VERSION ""

NS_ :

CM_ "#file:heartbeat.h";
CM_ "#file:VCU_heartbeat_state.h";
CM_ "#file:vcu_state_machine.c";

VAL_ 2418327552 BMU_Heartbeat_State 0 "BMU_UNKNOWN" 1 "BMU_READY" 2 "BMU_PRECHARGE" 3 "BMU_TS_ACTIVE" 4 "BMU_ERROR";

VAL_ 2424619008 SW_Heartbeat_State 0 "START" 1 "PERIPHERAL_INIT" 2 "SENSOR_INIT" 3 "BOARD_CHECK" 10 "IDLE" 11 "PEDAL_CHECK" 15 "BMU_CHECK" 20 "EBS_PWR" 21 "EBS_CHECK_ASMS" 22 "EBS_CHECK_PRESSURE" 23 "EBS_CHECK_PRESSURE_BTN" 24 "EBS_CHECK_PRESSURE_LOW" 25 "EBS_CHECK_PRESSURE_HIGH" 26 "EBS_CTRL_ACK" 27 "EBS_IDLE" 28 "EBS_PCHRG_PRESSED" 29 "EBS_CHECK_TS" 30 "EBS_CHECK_COMPUTE" 31 "EBS_READY" 32 "EBS_RELEASE_BRAKE" 33 "EBS_DRIVE" 34 "EBS_BRAKING" 40 "PRECHARGE_REQUEST" 41 "PRECHARGE" 42 "INVERTER_CHECK" 43 "INVERTER_ENERGIZE" 60 "RTD_RDY" 61 "RTD_BTN" 100 "DRIVING" 150 "AV_IDLE" 151 "AV_PRECHARGE_REQUEST" 152 "AV_PRECHARGE" 153 "AV_INVERTER_CHECK" 154 "AV_RTD" 155 "AV_DRIVING" 156 "AV_EMERGENCY" 240 "TS_ERROR" 250 "SHUTDOWN" 251 "ERROR";

BS_:

BU_:

BO_ 2418327552 BMU_Heartbeat: 7 Vector__XXX
 SG_ BMU_Heartbeat_Flags : 8|32@1+ (1,0) [0|0] "" Vector__XXX
 SG_ BMU_Heartbeat_State : 0|8@1+ (1,0) [0|0] "" Vector__XXX

BO_ 2424356864 VCU_Heartbeat_CTRL: 8 Vector__XXX
 SG_ VCU_Heartbeat_StateID : 0|8@1+ (1,0) [0|0] "" Vector__XXX
 SG_ VCU_Heartbeat_Flags : 32|16@1+ (1,0) [0|0] "" Vector__XXX
 SG_ VCU_WARN_PedalPolarity : 48|1@1+ (1,0) [0|1] "" Vector__XXX
 SG_ VCU_Heartbeat_Reserved : 49|15@1+ (1,0) [0|0] "" Vector__XXX

BO_ 2424356865 VCU_Heartbeat_PERIPH: 8 Vector__XXX
 SG_ VCU_HeartbeatState_PERIPH : 0|64@1+ (1,0) [0|0] "" Vector__XXX

BO_ 1285 VCU_Sync: 4 Vector__XXX
 SG_ VCU_Timestamp : 0|32@1+ (1,0) [0|4294967295] "ms" Vector__XXX

BO_ 2290122752 VCU_ShutdownStatus: 3 Vector__XXX
 SG_ VCU_ShutdownStatus : 16|8@1+ (1,0) [0|1] "" Vector__XXX
 SG_ VCU_ShutdownLines : 0|16@1+ (1,0) [0|0] "" Vector__XXX

BO_ 2449473537 VCU_RTD: 8 Vector__XXX
 SG_ VCU_RTD_Front : 0|1@1+ (1,0) [0|1] "" Vector__XXX
 SG_ VCU_RTD_Rear : 1|1@1+ (1,0) [0|1] "" Vector__XXX

BO_ 2449473538 VCU_MotorTemp: 8 Vector__XXX
 SG_ VCU_MotorTemp_FL : 0|16@1+ (0.1,0) [0|100] "" Vector__XXX
 SG_ VCU_MotorTemp_FR : 16|16@1+ (0.1,0) [0|100] "" Vector__XXX
 SG_ VCU_MotorTemp_RL : 32|16@1+ (0.1,0) [0|100] "" Vector__XXX
 SG_ VCU_MotorTemp_RR : 48|16@1+ (0.1,0) [0|100] "" Vector__XXXd

BO_ 2449473539 VCU_IMU_Accel: 8 Vector__XXX
 SG_ VCU_IMU_Accel_X : 0|16@1+ (0.01,-10) [-10|10] "" Vector__XXX
 SG_ VCU_IMU_Accel_Y : 16|16@1+ (0.01,-10) [-10|10] "" Vector__XXX
 SG_ VCU_IMU_Accel_Z : 32|16@1+ (0.01,-10) [-10|10] "" Vector__XXX

BO_ 2449473540 VCU_IMU_Gyro: 8 Vector__XXX
 SG_ VCU_IMU_Gyro_X : 0|16@1+ (0.01,-500) [-500|500] "" Vector__XXX
 SG_ VCU_IMU_Gyro_Y : 16|16@1+ (0.01,-500) [-500|500] "" Vector__XXX
 SG_ VCU_IMU_Gyro_Z : 32|16@1+ (0.01,-500) [-500|500] "" Vector__XXX

BO_ 2449473541 VCU_OBJ_DICT: 8 Vector__XXX
 SG_ VCU_OBJ_DICT_Index : 0|16@1+ (1,0) [0|65535] "" Vector__XXX
 SG_ VCU_OBJ_DICT_SubIndex : 16|8@1+ (1,0) [0|255] "" Vector__XXX
 SG_ VCU_OBJ_DICT_Data : 24|40@1+ (1,0) [0|0] "" Vector__XXX

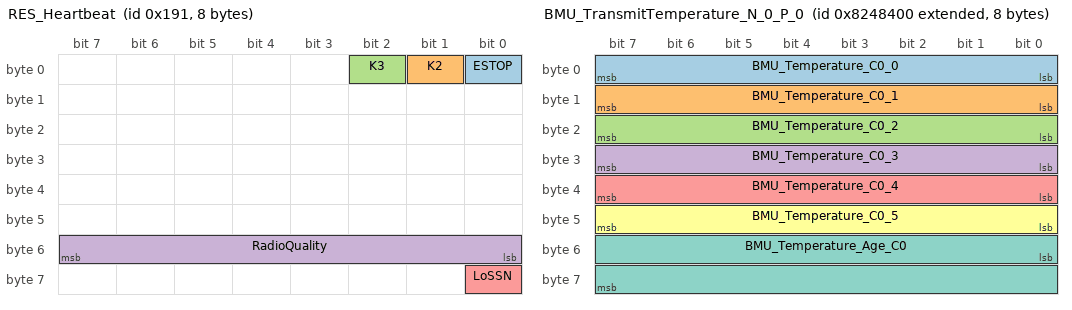
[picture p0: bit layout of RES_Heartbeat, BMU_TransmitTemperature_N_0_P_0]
BO_ 401 RES_Heartbeat: 8 Vector__XXX
 SG_ ESTOP : 0|1@1- (1,0) [0|1] "" Vector__XXX
 SG_ K2 : 1|1@1- (1,0) [0|1] "" Vector__XXX
 SG_ K3 : 2|1@1- (1,0) [0|1] "" Vector__XXX
 SG_ RadioQuality : 48|8@1+ (1,0) [0|255] "" Vector__XXX
 SG_ LoSSN : 56|1@1- (1,0) [0|1] "" Vector__XXX

BO_ 2420948992 EBS_CTRL_Heartbeat: 8 Vector___XXX
 SG_ State : 0|8@1+ (1, 0) [0|0] "" Vector__XXX

BO_ 2420424705 MCISO_Heartbeat_Right: 8 Vector__XXX
 SG_ MCISO_HeartbeatState_Right : 0|16@1+ (1,0) [0|0] "" Vector__XXX

BO_ 2420424704 MCISO_Heartbeat_Left: 8 Vector__XXX
 SG_ MCISO_HeartbeatState_Left : 0|16@1+ (1,0) [0|0] "" Vector__XXX

BO_ 2424619008 SW_Heartbeat: 8 Vector__XXX
 SG_ SW_Heartbeat_Flags : 16|16@1+ (1,0) [0|0] "" Vector__XXX
 SG_ SW_Heartbeat_State : 0|8@1+ (1,0) [0|0] "" Vector__XXX
 SG_ SW_Heartbeat_MissionID : 8|8@1+ (1,0) [0|0] "" Vector__XXX

BO_ 2290122937 VCU_Suspension_Rot_Front: 8 Vector__XXX
 SG_ VCU_Suspension_Rot_FL_ADC : 7|16@0+ (1,0) [0|0] "" Vector__XXX
 SG_ VCU_Suspension_Rot_FR_ADC : 23|16@0+ (1,0) [0|0] "" Vector__XXX
 SG_ VCU_Suspension_Rot_FL : 39|16@0- (0.001,0) [0|0] "" Vector__XXX
 SG_ VCU_Suspension_Rot_FR : 55|16@0- (0.001,0) [0|0] "" Vector__XXX

BO_ 2290122934 VCU_Suspension_Rot_Rear: 8 Vector__XXX
 SG_ VCU_Suspension_Rot_RL_ADC : 7|16@0+ (1,0) [0|0] "" Vector__XXX
 SG_ VCU_Suspension_Rot_RR_ADC : 23|16@0+ (1,0) [0|0] "" Vector__XXX
 SG_ VCU_Suspension_Rot_RL : 39|16@0- (0.001,0) [0|0] "" Vector__XXX
 SG_ VCU_Suspension_Rot_RR : 55|16@0- (0.001,0) [0|0] "" Vector__XXX

BO_ 2290122920 VCU_Temp_Gearbox_Right: 8 Vector__XXX
 SG_ VCU_Gearbox_Temp_Right_Temp : 39|16@0+ (0.1,0) [0|0] "" Vector__XXX
 SG_ VCU_Gearbox_Temp_Right_R : 23|16@0+ (1,0) [0|0] "" Vector__XXX
 SG_ VCU_Gearbox_Temp_Right_ADC : 7|16@0+ (1,0) [0|0] "" Vector__XXX

BO_ 2290122919 VCU_Temp_Gearbox_Left: 8 Vector__XXX
 SG_ VCU_Gearbox_Temp_Left_Temp : 39|16@0+ (0.1,0) [0|0] "" Vector__XXX
 SG_ VCU_Gearbox_Temp_Left_R : 23|16@0+ (1,0) [0|0] "" Vector__XXX
 SG_ VCU_Gearbox_Temp_Left_ADC : 7|16@0+ (1,0) [0|0] "" Vector__XXX

BO_ 2290122832 VCU_AirPressure: 8 Vector__XXX
 SG_ VCU_AirPressure_ADC : 7|16@0+ (1,0) [0|0] "" Vector__XXX

BO_ 2290122818 VCU_SuspensionTravel_DASH: 8 Vector__XXX
 SG_ VCU_SuspensionTravel_ADC_FR : 31|16@0+ (1,0) [0|0] "" Vector__XXX
 SG_ VCU_SuspensionTravel_ADC_FL : 15|16@0+ (1,0) [0|0] "" Vector__XXX

BO_ 2290122816 VCU_SuspensionTravel_SHDN: 8 Vector__XXX
 SG_ VCU_SuspensionTravel_ADC_RR : 31|16@0+ (1,0) [0|0] "" Vector__XXX
 SG_ VCU_SuspensionTravel_ADC_RL : 15|16@0+ (1,0) [0|0] "" Vector__XXX

BO_ 2290122784 VCU_Pedal_Accel: 8 Vector__XXX
 SG_ VCU_Pedal_Accel_0 : 7|16@0+ (1,0) [0|0] "" Vector__XXX
 SG_ VCU_Pedal_Accel_1 : 23|16@0+ (1,0) [0|0] "" Vector__XXX
 SG_ VCU_Pedal_Accel_ADC_0 : 39|16@0+ (1,0) [0|0] "" Vector__XXX
 SG_ VCU_Pedal_Accel_ADC_1 : 55|16@0+ (1,0) [0|0] "" Vector__XXX

BO_ 2290122800 VCU_Pedal_Brake: 8 Vector__XXX
 SG_ VCU_Pedal_Brake_ADC_0 : 7|16@0+ (1,0) [0|0] "" Vector__XXX
 SG_ VCU_Pedal_Brake_ADC_1 : 23|16@0+ (1,0) [0|0] "" Vector__XXX
 SG_ VCU_Pedal_Brake_PSI_0 : 39|16@0- (0.0625,0) [0|0] "" Vector__XXX
 SG_ VCU_Pedal_Brake_PSI_1 : 55|16@0- (0.0625,0) [0|0] "" Vector__XXX

BO_ 2290122848 VCU_TransmitSteering: 8 Vector__XXX
 SG_ VCU_Steering_ADC_0 : 32|16@1+ (0.1,0) [0|0] "" Vector__XXX
 SG_ VCU_Steering_ADC_1 : 48|16@1+ (0.1,0) [0|0] "" Vector__XXX
 SG_ VCU_Steering_0 : 0|16@1- (0.1,0) [0|0] "deg" Vector__XXX
 SG_ VCU_Steering_1 : 16|16@1- (0.1,0) [0|0] "deg" Vector__XXX

BO_ 2290122960 VCU_Wheel_Speed_Front: 8 Vector__XXX
 SG_ VCU_Wheel_Freq_FL : 7|16@0+ (1,0) [0|0] "" Vector__XXX
 SG_ VCU_Wheel_Freq_FR : 23|16@0+ (1,0) [0|0] "" Vector__XXX
 SG_ VCU_Wheel_RPM_FL : 39|16@0+ (0.1,0) [0|0] "" Vector__XXX
 SG_ VCU_Wheel_RPM_FR : 55|16@0+ (0.1,0) [0|0] "" Vector__XXX

BO_ 2290122951 VCU_FlowRate_Left: 8 Vector__XXX
 SG_ VCU_FlowRate_lpm_L : 7|16@0+ (0.01,0) [0|0] "L/min" Vector___XXX
 SG_ VCU_FlowRate_Freq_L : 23|16@0+ (0.01,0) [0|0] "" Vector___XXX

BO_ 2291122952 VCU_FlowRate_Right: 8 Vector__XXX
 SG_ VCU_FlowRate_lpm_R : 7|16@0+ (0.01,0) [0|0] "L/min" Vector___XXX
 SG_ VCU_FlowRate_Freq_R : 23|16@0+ (0.01,0) [0|0] "" Vector___XXX

BO_ 2290122993 VCU_Pitot_Tube: 8 Vector___XXX
 SG_ VCU_Pitot_Tube_ADC : 7|16@0+ (1,0) [0|0] "" Vector___XXX
 SG_ VCU_Pitot_Tube_Pressure : 23|16@0+ (0.01,0) [0|0] "kPa" Vector___XXX

BO_ 2424340672 VCU_Cooling_R_In: 8 Vector__XXX
 SG_ VCU_CoolR_In_Pressure_kPa : 7|16@0+ (0.1,0) [0|1000] "kPa" Vector__XXX
 SG_ VCU_CoolR_In_Temp_mV : 23|16@0+ (1,0) [0|5000] "mV" Vector__XXX
 SG_ VCU_CoolR_In_Pressure_PSI : 39|16@0+ (0.01,0) [0|150] "PSI" Vector__XXX
 SG_ VCU_CoolR_In_Temp_Celsius : 55|16@0- (0.1,0) [-40|150] "degC" Vector__XXX

BO_ 2424340673 VCU_Cooling_L_In: 8 Vector__XXX
 SG_ VCU_CoolL_In_Pressure_kPa : 7|16@0+ (0.1,0) [0|1000] "kPa" Vector__XXX
 SG_ VCU_CoolL_In_Temp_mV : 23|16@0+ (1,0) [0|5000] "mV" Vector__XXX
 SG_ VCU_CoolL_In_Pressure_PSI : 39|16@0+ (0.01,0) [0|150] "PSI" Vector__XXX
 SG_ VCU_CoolL_In_Temp_Celsius : 55|16@0- (0.1,0) [-40|150] "degC" Vector__XXX

BO_ 2424340676 VCU_Cooling_R_Out: 8 Vector__XXX
 SG_ VCU_CoolR_Out_Pressure_kPa : 7|16@0+ (0.1,0) [0|1000] "kPa" Vector__XXX
 SG_ VCU_CoolR_Out_Temp_mV : 23|16@0+ (1,0) [0|5000] "mV" Vector__XXX
 SG_ VCU_CoolR_Out_Pressure_PSI : 39|16@0+ (0.01,0) [0|150] "PSI" Vector__XXX
 SG_ VCU_CoolR_Out_Temp_Celsius : 55|16@0- (0.1,0) [-40|150] "degC" Vector__XXX

BO_ 2424340677 VCU_Cooling_L_Out: 8 Vector__XXX
 SG_ VCU_CoolL_Out_Pressure_kPa : 7|16@0+ (0.1,0) [0|1000] "kPa" Vector__XXX
 SG_ VCU_CoolL_Out_Temp_mV : 23|16@0+ (1,0) [0|5000] "mV" Vector__XXX
 SG_ VCU_CoolL_Out_Pressure_PSI : 39|16@0+ (0.01,0) [0|150] "PSI" Vector__XXX
 SG_ VCU_CoolL_Out_Temp_Celsius : 55|16@0- (0.1,0) [-40|150] "degC" Vector__XXX

BO_ 2424340674 VCU_CoolingLoop_Status: 8 Vector__XXX
 SG_ VCU_Pump1_Pressure_Filtered : 7|16@0+ (1,0) [0|65535] "mV" Vector__XXX
 SG_ VCU_Pump1_Temp_Filtered : 23|16@0+ (1,0) [0|65535] "mV" Vector__XXX
 SG_ VCU_Pump2_Pressure_Filtered : 39|16@0+ (1,0) [0|65535] "mV" Vector__XXX
 SG_ VCU_Pump2_Temp_Filtered : 55|16@0+ (1,0) [0|65535] "mV" Vector__XXX

BO_ 2424340675 VCU_CoolingLoop_Pressure_Bar: 8 Vector__XXX
 SG_ VCU_Pump1_Pressure_Bar : 7|16@0+ (0.001,0) [0|65.535] "bar" Vector__XXX
 SG_ VCU_Pump2_Pressure_Bar : 23|16@0+ (0.001,0) [0|65.535] "bar" Vector__XXX
 SG_ VCU_Sensor_Status : 39|8@0+ (1,0) [0|255] "" Vector__XXX

BO_ 2284097024 BMU_TransmitPower: 8 Vector__XXX
 SG_ BMU_Power : 0|4@1- (0.001,0) [0|0] "" Vector__XXX

BO_ 2284096768 BMU_TransmitPackInfo: 8 Vector__XXX
 SG_ BMU_PackVoltage : 32|32@1- (1E-006,0) [0|0] "" Vector__XXX
 SG_ BMU_PackCurrent : 0|32@1- (1E-006,0) [0|0] "" Vector__XXX

BO_ 2284093440 BMU_TransmitVoltage_N_0_P_0: 8 Vector__XXX
 SG_ BMU_Voltage_C0_0 : 0|16@1+ (1,0) [0|0] "" Vector__XXX
 SG_ BMU_Voltage_C0_1 : 16|16@1+ (1,0) [0|0] "" Vector__XXX
 SG_ BMU_Voltage_C0_2 : 32|16@1+ (1,0) [0|0] "" Vector__XXX
 SG_ BMU_Voltage_Age_C0 : 48|16@1+ (1,0) [0|0] "" Vector__XXX

BO_ 2284093441 BMU_TransmitVoltage_N_0_P_1: 8 Vector__XXX
 SG_ BMU_Voltage_C0_3 : 0|16@1+ (1,0) [0|0] "" Vector__XXX
 SG_ BMU_Voltage_C0_4 : 16|16@1+ (1,0) [0|0] "" Vector__XXX
 SG_ BMU_Voltage_C0_5 : 32|16@1+ (1,0) [0|0] "" Vector__XXX
 SG_ BMU_Voltage_Age_C0 : 48|16@1+ (1,0) [0|0] "" Vector__XXX

BO_ 2284093442 BMU_TransmitVoltage_N_0_P_2: 8 Vector__XXX
 SG_ BMU_Voltage_C0_6 : 0|16@1+ (1,0) [0|0] "" Vector__XXX
 SG_ BMU_Voltage_C0_7 : 16|16@1+ (1,0) [0|0] "" Vector__XXX
 SG_ BMU_Voltage_C0_8 : 32|16@1+ (1,0) [0|0] "" Vector__XXX
 SG_ BMU_Voltage_Age_C0 : 48|16@1+ (1,0) [0|0] "" Vector__XXX

BO_ 2284093443 BMU_TransmitVoltage_N_0_P_3: 8 Vector__XXX
 SG_ BMU_Voltage_C0_9 : 0|16@1+ (1,0) [0|0] "" Vector__XXX
 SG_ BMU_Voltage_C0_10 : 16|16@1+ (1,0) [0|0] "" Vector__XXX
 SG_ BMU_Voltage_C0_11 : 32|16@1+ (1,0) [0|0] "" Vector__XXX
 SG_ BMU_Voltage_Age_C0 : 48|16@1+ (1,0) [0|0] "" Vector__XXX

BO_ 2284093444 BMU_TransmitVoltage_N_0_P_4: 8 Vector__XXX
 SG_ BMU_Voltage_C0_12 : 0|16@1+ (1,0) [0|0] "" Vector__XXX
 SG_ BMU_Voltage_C0_13 : 16|16@1+ (1,0) [0|0] "" Vector__XXX
 SG_ BMU_Voltage_Age_C0 : 48|16@1+ (1,0) [0|0] "" Vector__XXX

BO_ 2284093456 BMU_TransmitVoltage_N_1_P_0: 8 Vector__XXX
 SG_ BMU_Voltage_C1_0 : 0|16@1+ (1,0) [0|0] "" Vector__XXX
 SG_ BMU_Voltage_C1_1 : 16|16@1+ (1,0) [0|0] "" Vector__XXX
 SG_ BMU_Voltage_C1_2 : 32|16@1+ (1,0) [0|0] "" Vector__XXX
 SG_ BMU_Voltage_Age_C1 : 48|16@1+ (1,0) [0|0] "" Vector__XXX

BO_ 2284093457 BMU_TransmitVoltage_N_1_P_1: 8 Vector__XXX
 SG_ BMU_Voltage_C1_3 : 0|16@1+ (1,0) [0|0] "" Vector__XXX
 SG_ BMU_Voltage_C1_4 : 16|16@1+ (1,0) [0|0] "" Vector__XXX
 SG_ BMU_Voltage_C1_5 : 32|16@1+ (1,0) [0|0] "" Vector__XXX
 SG_ BMU_Voltage_Age_C1 : 48|16@1+ (1,0) [0|0] "" Vector__XXX

BO_ 2284093458 BMU_TransmitVoltage_N_1_P_2: 8 Vector__XXX
 SG_ BMU_Voltage_C1_6 : 0|16@1+ (1,0) [0|0] "" Vector__XXX
 SG_ BMU_Voltage_C1_7 : 16|16@1+ (1,0) [0|0] "" Vector__XXX
 SG_ BMU_Voltage_C1_8 : 32|16@1+ (1,0) [0|0] "" Vector__XXX
 SG_ BMU_Voltage_Age_C1 : 48|16@1+ (1,0) [0|0] "" Vector__XXX

BO_ 2284093459 BMU_TransmitVoltage_N_1_P_3: 8 Vector__XXX
 SG_ BMU_Voltage_C1_9 : 0|16@1+ (1,0) [0|0] "" Vector__XXX
 SG_ BMU_Voltage_C1_10 : 16|16@1+ (1,0) [0|0] "" Vector__XXX
 SG_ BMU_Voltage_C1_11 : 32|16@1+ (1,0) [0|0] "" Vector__XXX
 SG_ BMU_Voltage_Age_C1 : 48|16@1+ (1,0) [0|0] "" Vector__XXX

BO_ 2284093460 BMU_TransmitVoltage_N_1_P_4: 8 Vector__XXX
 SG_ BMU_Voltage_C1_12 : 0|16@1+ (1,0) [0|0] "" Vector__XXX
 SG_ BMU_Voltage_C1_13 : 16|16@1+ (1,0) [0|0] "" Vector__XXX
 SG_ BMU_Voltage_Age_C1 : 48|16@1+ (1,0) [0|0] "" Vector__XXX

BO_ 2284093472 BMU_TransmitVoltage_N_2_P_0: 8 Vector__XXX
 SG_ BMU_Voltage_C2_0 : 0|16@1+ (1,0) [0|0] "" Vector__XXX
 SG_ BMU_Voltage_C2_1 : 16|16@1+ (1,0) [0|0] "" Vector__XXX
 SG_ BMU_Voltage_C2_2 : 32|16@1+ (1,0) [0|0] "" Vector__XXX
 SG_ BMU_Voltage_Age_C2 : 48|16@1+ (1,0) [0|0] "" Vector__XXX

BO_ 2284093473 BMU_TransmitVoltage_N_2_P_1: 8 Vector__XXX
 SG_ BMU_Voltage_C2_3 : 0|16@1+ (1,0) [0|0] "" Vector__XXX
 SG_ BMU_Voltage_C2_4 : 16|16@1+ (1,0) [0|0] "" Vector__XXX
 SG_ BMU_Voltage_C2_5 : 32|16@1+ (1,0) [0|0] "" Vector__XXX
 SG_ BMU_Voltage_Age_C2 : 48|16@1+ (1,0) [0|0] "" Vector__XXX

BO_ 2284093474 BMU_TransmitVoltage_N_2_P_2: 8 Vector__XXX
 SG_ BMU_Voltage_C2_6 : 0|16@1+ (1,0) [0|0] "" Vector__XXX
 SG_ BMU_Voltage_C2_7 : 16|16@1+ (1,0) [0|0] "" Vector__XXX
 SG_ BMU_Voltage_C2_8 : 32|16@1+ (1,0) [0|0] "" Vector__XXX
 SG_ BMU_Voltage_Age_C2 : 48|16@1+ (1,0) [0|0] "" Vector__XXX

BO_ 2284093475 BMU_TransmitVoltage_N_2_P_3: 8 Vector__XXX
 SG_ BMU_Voltage_C2_9 : 0|16@1+ (1,0) [0|0] "" Vector__XXX
 SG_ BMU_Voltage_C2_10 : 16|16@1+ (1,0) [0|0] "" Vector__XXX
 SG_ BMU_Voltage_C2_11 : 32|16@1+ (1,0) [0|0] "" Vector__XXX
 SG_ BMU_Voltage_Age_C2 : 48|16@1+ (1,0) [0|0] "" Vector__XXX

BO_ 2284093476 BMU_TransmitVoltage_N_2_P_4: 8 Vector__XXX
 SG_ BMU_Voltage_C2_12 : 0|16@1+ (1,0) [0|0] "" Vector__XXX
 SG_ BMU_Voltage_C2_13 : 16|16@1+ (1,0) [0|0] "" Vector__XXX
 SG_ BMU_Voltage_Age_C2 : 48|16@1+ (1,0) [0|0] "" Vector__XXX

BO_ 2284093488 BMU_TransmitVoltage_N_3_P_0: 8 Vector__XXX
 SG_ BMU_Voltage_C3_0 : 0|16@1+ (1,0) [0|0] "" Vector__XXX
 SG_ BMU_Voltage_C3_1 : 16|16@1+ (1,0) [0|0] "" Vector__XXX
 SG_ BMU_Voltage_C3_2 : 32|16@1+ (1,0) [0|0] "" Vector__XXX
 SG_ BMU_Voltage_Age_C3 : 48|16@1+ (1,0) [0|0] "" Vector__XXX

BO_ 2284093489 BMU_TransmitVoltage_N_3_P_1: 8 Vector__XXX
 SG_ BMU_Voltage_C3_3 : 0|16@1+ (1,0) [0|0] "" Vector__XXX
 SG_ BMU_Voltage_C3_4 : 16|16@1+ (1,0) [0|0] "" Vector__XXX
 SG_ BMU_Voltage_C3_5 : 32|16@1+ (1,0) [0|0] "" Vector__XXX
 SG_ BMU_Voltage_Age_C3 : 48|16@1+ (1,0) [0|0] "" Vector__XXX

BO_ 2284093490 BMU_TransmitVoltage_N_3_P_2: 8 Vector__XXX
 SG_ BMU_Voltage_C3_6 : 0|16@1+ (1,0) [0|0] "" Vector__XXX
 SG_ BMU_Voltage_C3_7 : 16|16@1+ (1,0) [0|0] "" Vector__XXX
 SG_ BMU_Voltage_C3_8 : 32|16@1+ (1,0) [0|0] "" Vector__XXX
 SG_ BMU_Voltage_Age_C3 : 48|16@1+ (1,0) [0|0] "" Vector__XXX

BO_ 2284093491 BMU_TransmitVoltage_N_3_P_3: 8 Vector__XXX
 SG_ BMU_Voltage_C3_9 : 0|16@1+ (1,0) [0|0] "" Vector__XXX
 SG_ BMU_Voltage_C3_10 : 16|16@1+ (1,0) [0|0] "" Vector__XXX
 SG_ BMU_Voltage_C3_11 : 32|16@1+ (1,0) [0|0] "" Vector__XXX
 SG_ BMU_Voltage_Age_C3 : 48|16@1+ (1,0) [0|0] "" Vector__XXX

BO_ 2284093492 BMU_TransmitVoltage_N_3_P_4: 8 Vector__XXX
 SG_ BMU_Voltage_C3_12 : 0|16@1+ (1,0) [0|0] "" Vector__XXX
 SG_ BMU_Voltage_C3_13 : 16|16@1+ (1,0) [0|0] "" Vector__XXX
 SG_ BMU_Voltage_Age_C3 : 48|16@1+ (1,0) [0|0] "" Vector__XXX

BO_ 2284093504 BMU_TransmitVoltage_N_4_P_0: 8 Vector__XXX
 SG_ BMU_Voltage_C4_0 : 0|16@1+ (1,0) [0|0] "" Vector__XXX
 SG_ BMU_Voltage_C4_1 : 16|16@1+ (1,0) [0|0] "" Vector__XXX
 SG_ BMU_Voltage_C4_2 : 32|16@1+ (1,0) [0|0] "" Vector__XXX
 SG_ BMU_Voltage_Age_C4 : 48|16@1+ (1,0) [0|0] "" Vector__XXX

BO_ 2284093505 BMU_TransmitVoltage_N_4_P_1: 8 Vector__XXX
 SG_ BMU_Voltage_C4_3 : 0|16@1+ (1,0) [0|0] "" Vector__XXX
 SG_ BMU_Voltage_C4_4 : 16|16@1+ (1,0) [0|0] "" Vector__XXX
 SG_ BMU_Voltage_C4_5 : 32|16@1+ (1,0) [0|0] "" Vector__XXX
 SG_ BMU_Voltage_Age_C4 : 48|16@1+ (1,0) [0|0] "" Vector__XXX

BO_ 2284093506 BMU_TransmitVoltage_N_4_P_2: 8 Vector__XXX
 SG_ BMU_Voltage_C4_6 : 0|16@1+ (1,0) [0|0] "" Vector__XXX
 SG_ BMU_Voltage_C4_7 : 16|16@1+ (1,0) [0|0] "" Vector__XXX
 SG_ BMU_Voltage_C4_8 : 32|16@1+ (1,0) [0|0] "" Vector__XXX
 SG_ BMU_Voltage_Age_C4 : 48|16@1+ (1,0) [0|0] "" Vector__XXX

BO_ 2284093507 BMU_TransmitVoltage_N_4_P_3: 8 Vector__XXX
 SG_ BMU_Voltage_C4_9 : 0|16@1+ (1,0) [0|0] "" Vector__XXX
 SG_ BMU_Voltage_C4_10 : 16|16@1+ (1,0) [0|0] "" Vector__XXX
 SG_ BMU_Voltage_C4_11 : 32|16@1+ (1,0) [0|0] "" Vector__XXX
 SG_ BMU_Voltage_Age_C4 : 48|16@1+ (1,0) [0|0] "" Vector__XXX

BO_ 2284093508 BMU_TransmitVoltage_N_4_P_4: 8 Vector__XXX
 SG_ BMU_Voltage_C4_12 : 0|16@1+ (1,0) [0|0] "" Vector__XXX
 SG_ BMU_Voltage_C4_13 : 16|16@1+ (1,0) [0|0] "" Vector__XXX
 SG_ BMU_Voltage_Age_C4 : 48|16@1+ (1,0) [0|0] "" Vector__XXX

BO_ 2284093520 BMU_TransmitVoltage_N_5_P_0: 8 Vector__XXX
 SG_ BMU_Voltage_C5_0 : 0|16@1+ (1,0) [0|0] "" Vector__XXX
 SG_ BMU_Voltage_C5_1 : 16|16@1+ (1,0) [0|0] "" Vector__XXX
 SG_ BMU_Voltage_C5_2 : 32|16@1+ (1,0) [0|0] "" Vector__XXX
 SG_ BMU_Voltage_Age_C5 : 48|16@1+ (1,0) [0|0] "" Vector__XXX

BO_ 2284093521 BMU_TransmitVoltage_N_5_P_1: 8 Vector__XXX
 SG_ BMU_Voltage_C5_3 : 0|16@1+ (1,0) [0|0] "" Vector__XXX
 SG_ BMU_Voltage_C5_4 : 16|16@1+ (1,0) [0|0] "" Vector__XXX
 SG_ BMU_Voltage_C5_5 : 32|16@1+ (1,0) [0|0] "" Vector__XXX
 SG_ BMU_Voltage_Age_C5 : 48|16@1+ (1,0) [0|0] "" Vector__XXX

BO_ 2284093522 BMU_TransmitVoltage_N_5_P_2: 8 Vector__XXX
 SG_ BMU_Voltage_C5_6 : 0|16@1+ (1,0) [0|0] "" Vector__XXX
 SG_ BMU_Voltage_C5_7 : 16|16@1+ (1,0) [0|0] "" Vector__XXX
 SG_ BMU_Voltage_C5_8 : 32|16@1+ (1,0) [0|0] "" Vector__XXX
 SG_ BMU_Voltage_Age_C5 : 48|16@1+ (1,0) [0|0] "" Vector__XXX

BO_ 2284093523 BMU_TransmitVoltage_N_5_P_3: 8 Vector__XXX
 SG_ BMU_Voltage_C5_9 : 0|16@1+ (1,0) [0|0] "" Vector__XXX
 SG_ BMU_Voltage_C5_10 : 16|16@1+ (1,0) [0|0] "" Vector__XXX
 SG_ BMU_Voltage_C5_11 : 32|16@1+ (1,0) [0|0] "" Vector__XXX
 SG_ BMU_Voltage_Age_C5 : 48|16@1+ (1,0) [0|0] "" Vector__XXX

BO_ 2284093524 BMU_TransmitVoltage_N_5_P_4: 8 Vector__XXX
 SG_ BMU_Voltage_C5_12 : 0|16@1+ (1,0) [0|0] "" Vector__XXX
 SG_ BMU_Voltage_C5_13 : 16|16@1+ (1,0) [0|0] "" Vector__XXX
 SG_ BMU_Voltage_Age_C5 : 48|16@1+ (1,0) [0|0] "" Vector__XXX

BO_ 2284093536 BMU_TransmitVoltage_N_6_P_0: 8 Vector__XXX
 SG_ BMU_Voltage_C6_0 : 0|16@1+ (1,0) [0|0] "" Vector__XXX
 SG_ BMU_Voltage_C6_1 : 16|16@1+ (1,0) [0|0] "" Vector__XXX
 SG_ BMU_Voltage_C6_2 : 32|16@1+ (1,0) [0|0] "" Vector__XXX
 SG_ BMU_Voltage_Age_C6 : 48|16@1+ (1,0) [0|0] "" Vector__XXX

BO_ 2284093537 BMU_TransmitVoltage_N_6_P_1: 8 Vector__XXX
 SG_ BMU_Voltage_C6_3 : 0|16@1+ (1,0) [0|0] "" Vector__XXX
 SG_ BMU_Voltage_C6_4 : 16|16@1+ (1,0) [0|0] "" Vector__XXX
 SG_ BMU_Voltage_C6_5 : 32|16@1+ (1,0) [0|0] "" Vector__XXX
 SG_ BMU_Voltage_Age_C6 : 48|16@1+ (1,0) [0|0] "" Vector__XXX

BO_ 2284093538 BMU_TransmitVoltage_N_6_P_2: 8 Vector__XXX
 SG_ BMU_Voltage_C6_6 : 0|16@1+ (1,0) [0|0] "" Vector__XXX
 SG_ BMU_Voltage_C6_7 : 16|16@1+ (1,0) [0|0] "" Vector__XXX
 SG_ BMU_Voltage_C6_8 : 32|16@1+ (1,0) [0|0] "" Vector__XXX
 SG_ BMU_Voltage_Age_C6 : 48|16@1+ (1,0) [0|0] "" Vector__XXX

BO_ 2284093539 BMU_TransmitVoltage_N_6_P_3: 8 Vector__XXX
 SG_ BMU_Voltage_C6_9 : 0|16@1+ (1,0) [0|0] "" Vector__XXX
 SG_ BMU_Voltage_C6_10 : 16|16@1+ (1,0) [0|0] "" Vector__XXX
 SG_ BMU_Voltage_C6_11 : 32|16@1+ (1,0) [0|0] "" Vector__XXX
 SG_ BMU_Voltage_Age_C6 : 48|16@1+ (1,0) [0|0] "" Vector__XXX

BO_ 2284093540 BMU_TransmitVoltage_N_6_P_4: 8 Vector__XXX
 SG_ BMU_Voltage_C6_12 : 0|16@1+ (1,0) [0|0] "" Vector__XXX
 SG_ BMU_Voltage_C6_13 : 16|16@1+ (1,0) [0|0] "" Vector__XXX
 SG_ BMU_Voltage_Age_C6 : 48|16@1+ (1,0) [0|0] "" Vector__XXX

BO_ 2284093552 BMU_TransmitVoltage_N_7_P_0: 8 Vector__XXX
 SG_ BMU_Voltage_C7_0 : 0|16@1+ (1,0) [0|0] "" Vector__XXX
 SG_ BMU_Voltage_C7_1 : 16|16@1+ (1,0) [0|0] "" Vector__XXX
 SG_ BMU_Voltage_C7_2 : 32|16@1+ (1,0) [0|0] "" Vector__XXX
 SG_ BMU_Voltage_Age_C7 : 48|16@1+ (1,0) [0|0] "" Vector__XXX

BO_ 2284093553 BMU_TransmitVoltage_N_7_P_1: 8 Vector__XXX
 SG_ BMU_Voltage_C7_3 : 0|16@1+ (1,0) [0|0] "" Vector__XXX
 SG_ BMU_Voltage_C7_4 : 16|16@1+ (1,0) [0|0] "" Vector__XXX
 SG_ BMU_Voltage_C7_5 : 32|16@1+ (1,0) [0|0] "" Vector__XXX
 SG_ BMU_Voltage_Age_C7 : 48|16@1+ (1,0) [0|0] "" Vector__XXX

BO_ 2284093554 BMU_TransmitVoltage_N_7_P_2: 8 Vector__XXX
 SG_ BMU_Voltage_C7_6 : 0|16@1+ (1,0) [0|0] "" Vector__XXX
 SG_ BMU_Voltage_C7_7 : 16|16@1+ (1,0) [0|0] "" Vector__XXX
 SG_ BMU_Voltage_C7_8 : 32|16@1+ (1,0) [0|0] "" Vector__XXX
 SG_ BMU_Voltage_Age_C7 : 48|16@1+ (1,0) [0|0] "" Vector__XXX

BO_ 2284093555 BMU_TransmitVoltage_N_7_P_3: 8 Vector__XXX
 SG_ BMU_Voltage_C7_9 : 0|16@1+ (1,0) [0|0] "" Vector__XXX
 SG_ BMU_Voltage_C7_10 : 16|16@1+ (1,0) [0|0] "" Vector__XXX
 SG_ BMU_Voltage_C7_11 : 32|16@1+ (1,0) [0|0] "" Vector__XXX
 SG_ BMU_Voltage_Age_C7 : 48|16@1+ (1,0) [0|0] "" Vector__XXX

BO_ 2284093556 BMU_TransmitVoltage_N_7_P_4: 8 Vector__XXX
 SG_ BMU_Voltage_C7_12 : 0|16@1+ (1,0) [0|0] "" Vector__XXX
 SG_ BMU_Voltage_C7_13 : 16|16@1+ (1,0) [0|0] "" Vector__XXX
 SG_ BMU_Voltage_Age_C7 : 48|16@1+ (1,0) [0|0] "" Vector__XXX

BO_ 2284093568 BMU_TransmitVoltage_N_8_P_0: 8 Vector__XXX
 SG_ BMU_Voltage_C8_0 : 0|16@1+ (1,0) [0|0] "" Vector__XXX
 SG_ BMU_Voltage_C8_1 : 16|16@1+ (1,0) [0|0] "" Vector__XXX
 SG_ BMU_Voltage_C8_2 : 32|16@1+ (1,0) [0|0] "" Vector__XXX
 SG_ BMU_Voltage_Age_C8 : 48|16@1+ (1,0) [0|0] "" Vector__XXX

BO_ 2284093569 BMU_TransmitVoltage_N_8_P_1: 8 Vector__XXX
 SG_ BMU_Voltage_C8_3 : 0|16@1+ (1,0) [0|0] "" Vector__XXX
 SG_ BMU_Voltage_C8_4 : 16|16@1+ (1,0) [0|0] "" Vector__XXX
 SG_ BMU_Voltage_C8_5 : 32|16@1+ (1,0) [0|0] "" Vector__XXX
 SG_ BMU_Voltage_Age_C8 : 48|16@1+ (1,0) [0|0] "" Vector__XXX

BO_ 2284093570 BMU_TransmitVoltage_N_8_P_2: 8 Vector__XXX
 SG_ BMU_Voltage_C8_6 : 0|16@1+ (1,0) [0|0] "" Vector__XXX
 SG_ BMU_Voltage_C8_7 : 16|16@1+ (1,0) [0|0] "" Vector__XXX
 SG_ BMU_Voltage_C8_8 : 32|16@1+ (1,0) [0|0] "" Vector__XXX
 SG_ BMU_Voltage_Age_C8 : 48|16@1+ (1,0) [0|0] "" Vector__XXX

BO_ 2284093571 BMU_TransmitVoltage_N_8_P_3: 8 Vector__XXX
 SG_ BMU_Voltage_C8_9 : 0|16@1+ (1,0) [0|0] "" Vector__XXX
 SG_ BMU_Voltage_C8_10 : 16|16@1+ (1,0) [0|0] "" Vector__XXX
 SG_ BMU_Voltage_C8_11 : 32|16@1+ (1,0) [0|0] "" Vector__XXX
 SG_ BMU_Voltage_Age_C8 : 48|16@1+ (1,0) [0|0] "" Vector__XXX

BO_ 2284093572 BMU_TransmitVoltage_N_8_P_4: 8 Vector__XXX
 SG_ BMU_Voltage_C8_12 : 0|16@1+ (1,0) [0|0] "" Vector__XXX
 SG_ BMU_Voltage_C8_13 : 16|16@1+ (1,0) [0|0] "" Vector__XXX
 SG_ BMU_Voltage_Age_C8 : 48|16@1+ (1,0) [0|0] "" Vector__XXX

BO_ 2284093584 BMU_TransmitVoltage_N_9_P_0: 8 Vector__XXX
 SG_ BMU_Voltage_C9_0 : 0|16@1+ (1,0) [0|0] "" Vector__XXX
 SG_ BMU_Voltage_C9_1 : 16|16@1+ (1,0) [0|0] "" Vector__XXX
 SG_ BMU_Voltage_C9_2 : 32|16@1+ (1,0) [0|0] "" Vector__XXX
 SG_ BMU_Voltage_Age_C9 : 48|16@1+ (1,0) [0|0] "" Vector__XXX

BO_ 2284093585 BMU_TransmitVoltage_N_9_P_1: 8 Vector__XXX
 SG_ BMU_Voltage_C9_3 : 0|16@1+ (1,0) [0|0] "" Vector__XXX
 SG_ BMU_Voltage_C9_4 : 16|16@1+ (1,0) [0|0] "" Vector__XXX
 SG_ BMU_Voltage_C9_5 : 32|16@1+ (1,0) [0|0] "" Vector__XXX
 SG_ BMU_Voltage_Age_C9 : 48|16@1+ (1,0) [0|0] "" Vector__XXX

BO_ 2284093586 BMU_TransmitVoltage_N_9_P_2: 8 Vector__XXX
 SG_ BMU_Voltage_C9_6 : 0|16@1+ (1,0) [0|0] "" Vector__XXX
 SG_ BMU_Voltage_C9_7 : 16|16@1+ (1,0) [0|0] "" Vector__XXX
 SG_ BMU_Voltage_C9_8 : 32|16@1+ (1,0) [0|0] "" Vector__XXX
 SG_ BMU_Voltage_Age_C9 : 48|16@1+ (1,0) [0|0] "" Vector__XXX

BO_ 2284093587 BMU_TransmitVoltage_N_9_P_3: 8 Vector__XXX
 SG_ BMU_Voltage_C9_9 : 0|16@1+ (1,0) [0|0] "" Vector__XXX
 SG_ BMU_Voltage_C9_10 : 16|16@1+ (1,0) [0|0] "" Vector__XXX
 SG_ BMU_Voltage_C9_11 : 32|16@1+ (1,0) [0|0] "" Vector__XXX
 SG_ BMU_Voltage_Age_C9 : 48|16@1+ (1,0) [0|0] "" Vector__XXX

BO_ 2284093588 BMU_TransmitVoltage_N_9_P_4: 8 Vector__XXX
 SG_ BMU_Voltage_C9_12 : 0|16@1+ (1,0) [0|0] "" Vector__XXX
 SG_ BMU_Voltage_C9_13 : 16|16@1+ (1,0) [0|0] "" Vector__XXX
 SG_ BMU_Voltage_Age_C9 : 48|16@1+ (1,0) [0|0] "" Vector__XXX

BO_ 2284093600 BMU_TransmitVoltage_N_10_P_0: 8 Vector__XXX
 SG_ BMU_Voltage_C10_0 : 0|16@1+ (1,0) [0|0] "" Vector__XXX
 SG_ BMU_Voltage_C10_1 : 16|16@1+ (1,0) [0|0] "" Vector__XXX
 SG_ BMU_Voltage_C10_2 : 32|16@1+ (1,0) [0|0] "" Vector__XXX
 SG_ BMU_Voltage_Age_C10 : 48|16@1+ (1,0) [0|0] "" Vector__XXX

BO_ 2284093601 BMU_TransmitVoltage_N_10_P_1: 8 Vector__XXX
 SG_ BMU_Voltage_C10_3 : 0|16@1+ (1,0) [0|0] "" Vector__XXX
 SG_ BMU_Voltage_C10_4 : 16|16@1+ (1,0) [0|0] "" Vector__XXX
 SG_ BMU_Voltage_C10_5 : 32|16@1+ (1,0) [0|0] "" Vector__XXX
 SG_ BMU_Voltage_Age_C10 : 48|16@1+ (1,0) [0|0] "" Vector__XXX

BO_ 2284093602 BMU_TransmitVoltage_N_10_P_2: 8 Vector__XXX
 SG_ BMU_Voltage_C10_6 : 0|16@1+ (1,0) [0|0] "" Vector__XXX
 SG_ BMU_Voltage_C10_7 : 16|16@1+ (1,0) [0|0] "" Vector__XXX
 SG_ BMU_Voltage_C10_8 : 32|16@1+ (1,0) [0|0] "" Vector__XXX
 SG_ BMU_Voltage_Age_C10 : 48|16@1+ (1,0) [0|0] "" Vector__XXX

BO_ 2284093603 BMU_TransmitVoltage_N_10_P_3: 8 Vector__XXX
 SG_ BMU_Voltage_C10_9 : 0|16@1+ (1,0) [0|0] "" Vector__XXX
 SG_ BMU_Voltage_C10_10 : 16|16@1+ (1,0) [0|0] "" Vector__XXX
 SG_ BMU_Voltage_C10_11 : 32|16@1+ (1,0) [0|0] "" Vector__XXX
 SG_ BMU_Voltage_Age_C10 : 48|16@1+ (1,0) [0|0] "" Vector__XXX

BO_ 2284093604 BMU_TransmitVoltage_N_10_P_4: 8 Vector__XXX
 SG_ BMU_Voltage_C10_12 : 0|16@1+ (1,0) [0|0] "" Vector__XXX
 SG_ BMU_Voltage_C10_13 : 16|16@1+ (1,0) [0|0] "" Vector__XXX
 SG_ BMU_Voltage_Age_C10 : 48|16@1+ (1,0) [0|0] "" Vector__XXX

BO_ 2284093616 BMU_TransmitVoltage_N_11_P_0: 8 Vector__XXX
 SG_ BMU_Voltage_C11_0 : 0|16@1+ (1,0) [0|0] "" Vector__XXX
 SG_ BMU_Voltage_C11_1 : 16|16@1+ (1,0) [0|0] "" Vector__XXX
 SG_ BMU_Voltage_C11_2 : 32|16@1+ (1,0) [0|0] "" Vector__XXX
 SG_ BMU_Voltage_Age_C11 : 48|16@1+ (1,0) [0|0] "" Vector__XXX

BO_ 2284093617 BMU_TransmitVoltage_N_11_P_1: 8 Vector__XXX
 SG_ BMU_Voltage_C11_3 : 0|16@1+ (1,0) [0|0] "" Vector__XXX
 SG_ BMU_Voltage_C11_4 : 16|16@1+ (1,0) [0|0] "" Vector__XXX
 SG_ BMU_Voltage_C11_5 : 32|16@1+ (1,0) [0|0] "" Vector__XXX
 SG_ BMU_Voltage_Age_C11 : 48|16@1+ (1,0) [0|0] "" Vector__XXX

BO_ 2284093618 BMU_TransmitVoltage_N_11_P_2: 8 Vector__XXX
 SG_ BMU_Voltage_C11_6 : 0|16@1+ (1,0) [0|0] "" Vector__XXX
 SG_ BMU_Voltage_C11_7 : 16|16@1+ (1,0) [0|0] "" Vector__XXX
 SG_ BMU_Voltage_C11_8 : 32|16@1+ (1,0) [0|0] "" Vector__XXX
 SG_ BMU_Voltage_Age_C11 : 48|16@1+ (1,0) [0|0] "" Vector__XXX

BO_ 2284093619 BMU_TransmitVoltage_N_11_P_3: 8 Vector__XXX
 SG_ BMU_Voltage_C11_9 : 0|16@1+ (1,0) [0|0] "" Vector__XXX
 SG_ BMU_Voltage_C11_10 : 16|16@1+ (1,0) [0|0] "" Vector__XXX
 SG_ BMU_Voltage_C11_11 : 32|16@1+ (1,0) [0|0] "" Vector__XXX
 SG_ BMU_Voltage_Age_C11 : 48|16@1+ (1,0) [0|0] "" Vector__XXX

BO_ 2284093620 BMU_TransmitVoltage_N_11_P_4: 8 Vector__XXX
 SG_ BMU_Voltage_C11_12 : 0|16@1+ (1,0) [0|0] "" Vector__XXX
 SG_ BMU_Voltage_C11_13 : 16|16@1+ (1,0) [0|0] "" Vector__XXX
 SG_ BMU_Voltage_Age_C11 : 48|16@1+ (1,0) [0|0] "" Vector__XXX

BO_ 2284093632 BMU_TransmitVoltage_N_12_P_0: 8 Vector__XXX
 SG_ BMU_Voltage_C12_0 : 0|16@1+ (1,0) [0|0] "" Vector__XXX
 SG_ BMU_Voltage_C12_1 : 16|16@1+ (1,0) [0|0] "" Vector__XXX
 SG_ BMU_Voltage_C12_2 : 32|16@1+ (1,0) [0|0] "" Vector__XXX
 SG_ BMU_Voltage_Age_C12 : 48|16@1+ (1,0) [0|0] "" Vector__XXX

BO_ 2284093633 BMU_TransmitVoltage_N_12_P_1: 8 Vector__XXX
 SG_ BMU_Voltage_C12_3 : 0|16@1+ (1,0) [0|0] "" Vector__XXX
 SG_ BMU_Voltage_C12_4 : 16|16@1+ (1,0) [0|0] "" Vector__XXX
 SG_ BMU_Voltage_C12_5 : 32|16@1+ (1,0) [0|0] "" Vector__XXX
 SG_ BMU_Voltage_Age_C12 : 48|16@1+ (1,0) [0|0] "" Vector__XXX

BO_ 2284093634 BMU_TransmitVoltage_N_12_P_2: 8 Vector__XXX
 SG_ BMU_Voltage_C12_6 : 0|16@1+ (1,0) [0|0] "" Vector__XXX
 SG_ BMU_Voltage_C12_7 : 16|16@1+ (1,0) [0|0] "" Vector__XXX
 SG_ BMU_Voltage_C12_8 : 32|16@1+ (1,0) [0|0] "" Vector__XXX
 SG_ BMU_Voltage_Age_C12 : 48|16@1+ (1,0) [0|0] "" Vector__XXX

BO_ 2284093635 BMU_TransmitVoltage_N_12_P_3: 8 Vector__XXX
 SG_ BMU_Voltage_C12_9 : 0|16@1+ (1,0) [0|0] "" Vector__XXX
 SG_ BMU_Voltage_C12_10 : 16|16@1+ (1,0) [0|0] "" Vector__XXX
 SG_ BMU_Voltage_C12_11 : 32|16@1+ (1,0) [0|0] "" Vector__XXX
 SG_ BMU_Voltage_Age_C12 : 48|16@1+ (1,0) [0|0] "" Vector__XXX

BO_ 2284093636 BMU_TransmitVoltage_N_12_P_4: 8 Vector__XXX
 SG_ BMU_Voltage_C12_12 : 0|16@1+ (1,0) [0|0] "" Vector__XXX
 SG_ BMU_Voltage_C12_13 : 16|16@1+ (1,0) [0|0] "" Vector__XXX
 SG_ BMU_Voltage_Age_C12 : 48|16@1+ (1,0) [0|0] "" Vector__XXX

BO_ 2284093648 BMU_TransmitVoltage_N_13_P_0: 8 Vector__XXX
 SG_ BMU_Voltage_C13_0 : 0|16@1+ (1,0) [0|0] "" Vector__XXX
 SG_ BMU_Voltage_C13_1 : 16|16@1+ (1,0) [0|0] "" Vector__XXX
 SG_ BMU_Voltage_C13_2 : 32|16@1+ (1,0) [0|0] "" Vector__XXX
 SG_ BMU_Voltage_Age_C13 : 48|16@1+ (1,0) [0|0] "" Vector__XXX

BO_ 2284093649 BMU_TransmitVoltage_N_13_P_1: 8 Vector__XXX
 SG_ BMU_Voltage_C13_3 : 0|16@1+ (1,0) [0|0] "" Vector__XXX
 SG_ BMU_Voltage_C13_4 : 16|16@1+ (1,0) [0|0] "" Vector__XXX
 SG_ BMU_Voltage_C13_5 : 32|16@1+ (1,0) [0|0] "" Vector__XXX
 SG_ BMU_Voltage_Age_C13 : 48|16@1+ (1,0) [0|0] "" Vector__XXX

BO_ 2284093650 BMU_TransmitVoltage_N_13_P_2: 8 Vector__XXX
 SG_ BMU_Voltage_C13_6 : 0|16@1+ (1,0) [0|0] "" Vector__XXX
 SG_ BMU_Voltage_C13_7 : 16|16@1+ (1,0) [0|0] "" Vector__XXX
 SG_ BMU_Voltage_C13_8 : 32|16@1+ (1,0) [0|0] "" Vector__XXX
 SG_ BMU_Voltage_Age_C13 : 48|16@1+ (1,0) [0|0] "" Vector__XXX

BO_ 2284093651 BMU_TransmitVoltage_N_13_P_3: 8 Vector__XXX
 SG_ BMU_Voltage_C13_9 : 0|16@1+ (1,0) [0|0] "" Vector__XXX
 SG_ BMU_Voltage_C13_10 : 16|16@1+ (1,0) [0|0] "" Vector__XXX
 SG_ BMU_Voltage_C13_11 : 32|16@1+ (1,0) [0|0] "" Vector__XXX
 SG_ BMU_Voltage_Age_C13 : 48|16@1+ (1,0) [0|0] "" Vector__XXX

BO_ 2284093652 BMU_TransmitVoltage_N_13_P_4: 8 Vector__XXX
 SG_ BMU_Voltage_C13_12 : 0|16@1+ (1,0) [0|0] "" Vector__XXX
 SG_ BMU_Voltage_C13_13 : 16|16@1+ (1,0) [0|0] "" Vector__XXX
 SG_ BMU_Voltage_Age_C13 : 48|16@1+ (1,0) [0|0] "" Vector__XXX

BO_ 2284093664 BMU_TransmitVoltage_N_14_P_0: 8 Vector__XXX
 SG_ BMU_Voltage_C14_0 : 0|16@1+ (1,0) [0|0] "" Vector__XXX
 SG_ BMU_Voltage_C14_1 : 16|16@1+ (1,0) [0|0] "" Vector__XXX
 SG_ BMU_Voltage_C14_2 : 32|16@1+ (1,0) [0|0] "" Vector__XXX
 SG_ BMU_Voltage_Age_C14 : 48|16@1+ (1,0) [0|0] "" Vector__XXX

BO_ 2284093665 BMU_TransmitVoltage_N_14_P_1: 8 Vector__XXX
 SG_ BMU_Voltage_C14_3 : 0|16@1+ (1,0) [0|0] "" Vector__XXX
 SG_ BMU_Voltage_C14_4 : 16|16@1+ (1,0) [0|0] "" Vector__XXX
 SG_ BMU_Voltage_C14_5 : 32|16@1+ (1,0) [0|0] "" Vector__XXX
 SG_ BMU_Voltage_Age_C14 : 48|16@1+ (1,0) [0|0] "" Vector__XXX

BO_ 2284093666 BMU_TransmitVoltage_N_14_P_2: 8 Vector__XXX
 SG_ BMU_Voltage_C14_6 : 0|16@1+ (1,0) [0|0] "" Vector__XXX
 SG_ BMU_Voltage_C14_7 : 16|16@1+ (1,0) [0|0] "" Vector__XXX
 SG_ BMU_Voltage_C14_8 : 32|16@1+ (1,0) [0|0] "" Vector__XXX
 SG_ BMU_Voltage_Age_C14 : 48|16@1+ (1,0) [0|0] "" Vector__XXX

BO_ 2284093667 BMU_TransmitVoltage_N_14_P_3: 8 Vector__XXX
 SG_ BMU_Voltage_C14_9 : 0|16@1+ (1,0) [0|0] "" Vector__XXX
 SG_ BMU_Voltage_C14_10 : 16|16@1+ (1,0) [0|0] "" Vector__XXX
 SG_ BMU_Voltage_C14_11 : 32|16@1+ (1,0) [0|0] "" Vector__XXX
 SG_ BMU_Voltage_Age_C14 : 48|16@1+ (1,0) [0|0] "" Vector__XXX

BO_ 2284093668 BMU_TransmitVoltage_N_14_P_4: 8 Vector__XXX
 SG_ BMU_Voltage_C14_12 : 0|16@1+ (1,0) [0|0] "" Vector__XXX
 SG_ BMU_Voltage_C14_13 : 16|16@1+ (1,0) [0|0] "" Vector__XXX
 SG_ BMU_Voltage_Age_C14 : 48|16@1+ (1,0) [0|0] "" Vector__XXX

BO_ 2284093680 BMU_TransmitVoltage_N_15_P_0: 8 Vector__XXX
 SG_ BMU_Voltage_C15_0 : 0|16@1+ (1,0) [0|0] "" Vector__XXX
 SG_ BMU_Voltage_C15_1 : 16|16@1+ (1,0) [0|0] "" Vector__XXX
 SG_ BMU_Voltage_C15_2 : 32|16@1+ (1,0) [0|0] "" Vector__XXX
 SG_ BMU_Voltage_Age_C15 : 48|16@1+ (1,0) [0|0] "" Vector__XXX

BO_ 2284093681 BMU_TransmitVoltage_N_15_P_1: 8 Vector__XXX
 SG_ BMU_Voltage_C15_3 : 0|16@1+ (1,0) [0|0] "" Vector__XXX
 SG_ BMU_Voltage_C15_4 : 16|16@1+ (1,0) [0|0] "" Vector__XXX
 SG_ BMU_Voltage_C15_5 : 32|16@1+ (1,0) [0|0] "" Vector__XXX
 SG_ BMU_Voltage_Age_C15 : 48|16@1+ (1,0) [0|0] "" Vector__XXX

BO_ 2284093682 BMU_TransmitVoltage_N_15_P_2: 8 Vector__XXX
 SG_ BMU_Voltage_C15_6 : 0|16@1+ (1,0) [0|0] "" Vector__XXX
 SG_ BMU_Voltage_C15_7 : 16|16@1+ (1,0) [0|0] "" Vector__XXX
 SG_ BMU_Voltage_C15_8 : 32|16@1+ (1,0) [0|0] "" Vector__XXX
 SG_ BMU_Voltage_Age_C15 : 48|16@1+ (1,0) [0|0] "" Vector__XXX

BO_ 2284093683 BMU_TransmitVoltage_N_15_P_3: 8 Vector__XXX
 SG_ BMU_Voltage_C15_9 : 0|16@1+ (1,0) [0|0] "" Vector__XXX
 SG_ BMU_Voltage_C15_10 : 16|16@1+ (1,0) [0|0] "" Vector__XXX
 SG_ BMU_Voltage_C15_11 : 32|16@1+ (1,0) [0|0] "" Vector__XXX
 SG_ BMU_Voltage_Age_C15 : 48|16@1+ (1,0) [0|0] "" Vector__XXX

BO_ 2284093684 BMU_TransmitVoltage_N_15_P_4: 8 Vector__XXX
 SG_ BMU_Voltage_C15_12 : 0|16@1+ (1,0) [0|0] "" Vector__XXX
 SG_ BMU_Voltage_C15_13 : 16|16@1+ (1,0) [0|0] "" Vector__XXX
 SG_ BMU_Voltage_Age_C15 : 48|16@1+ (1,0) [0|0] "" Vector__XXX

BO_ 2284093696 BMU_TransmitVoltage_N_16_P_0: 8 Vector__XXX
 SG_ BMU_Voltage_C16_0 : 0|16@1+ (1,0) [0|0] "" Vector__XXX
 SG_ BMU_Voltage_C16_1 : 16|16@1+ (1,0) [0|0] "" Vector__XXX
 SG_ BMU_Voltage_C16_2 : 32|16@1+ (1,0) [0|0] "" Vector__XXX
 SG_ BMU_Voltage_Age_C16 : 48|16@1+ (1,0) [0|0] "" Vector__XXX

BO_ 2284093697 BMU_TransmitVoltage_N_16_P_1: 8 Vector__XXX
 SG_ BMU_Voltage_C16_3 : 0|16@1+ (1,0) [0|0] "" Vector__XXX
 SG_ BMU_Voltage_C16_4 : 16|16@1+ (1,0) [0|0] "" Vector__XXX
 SG_ BMU_Voltage_C16_5 : 32|16@1+ (1,0) [0|0] "" Vector__XXX
 SG_ BMU_Voltage_Age_C16 : 48|16@1+ (1,0) [0|0] "" Vector__XXX

BO_ 2284093698 BMU_TransmitVoltage_N_16_P_2: 8 Vector__XXX
 SG_ BMU_Voltage_C16_6 : 0|16@1+ (1,0) [0|0] "" Vector__XXX
 SG_ BMU_Voltage_C16_7 : 16|16@1+ (1,0) [0|0] "" Vector__XXX
 SG_ BMU_Voltage_C16_8 : 32|16@1+ (1,0) [0|0] "" Vector__XXX
 SG_ BMU_Voltage_Age_C16 : 48|16@1+ (1,0) [0|0] "" Vector__XXX

BO_ 2284093699 BMU_TransmitVoltage_N_16_P_3: 8 Vector__XXX
 SG_ BMU_Voltage_C16_9 : 0|16@1+ (1,0) [0|0] "" Vector__XXX
 SG_ BMU_Voltage_C16_10 : 16|16@1+ (1,0) [0|0] "" Vector__XXX
 SG_ BMU_Voltage_C16_11 : 32|16@1+ (1,0) [0|0] "" Vector__XXX
 SG_ BMU_Voltage_Age_C16 : 48|16@1+ (1,0) [0|0] "" Vector__XXX

BO_ 2284093700 BMU_TransmitVoltage_N_16_P_4: 8 Vector__XXX
 SG_ BMU_Voltage_C16_12 : 0|16@1+ (1,0) [0|0] "" Vector__XXX
 SG_ BMU_Voltage_C16_13 : 16|16@1+ (1,0) [0|0] "" Vector__XXX
 SG_ BMU_Voltage_Age_C16 : 48|16@1+ (1,0) [0|0] "" Vector__XXX

BO_ 2284093712 BMU_TransmitVoltage_N_17_P_0: 8 Vector__XXX
 SG_ BMU_Voltage_C17_0 : 0|16@1+ (1,0) [0|0] "" Vector__XXX
 SG_ BMU_Voltage_C17_1 : 16|16@1+ (1,0) [0|0] "" Vector__XXX
 SG_ BMU_Voltage_C17_2 : 32|16@1+ (1,0) [0|0] "" Vector__XXX
 SG_ BMU_Voltage_Age_C17 : 48|16@1+ (1,0) [0|0] "" Vector__XXX

BO_ 2284093713 BMU_TransmitVoltage_N_17_P_1: 8 Vector__XXX
 SG_ BMU_Voltage_C17_3 : 0|16@1+ (1,0) [0|0] "" Vector__XXX
 SG_ BMU_Voltage_C17_4 : 16|16@1+ (1,0) [0|0] "" Vector__XXX
 SG_ BMU_Voltage_C17_5 : 32|16@1+ (1,0) [0|0] "" Vector__XXX
 SG_ BMU_Voltage_Age_C17 : 48|16@1+ (1,0) [0|0] "" Vector__XXX

BO_ 2284093714 BMU_TransmitVoltage_N_17_P_2: 8 Vector__XXX
 SG_ BMU_Voltage_C17_6 : 0|16@1+ (1,0) [0|0] "" Vector__XXX
 SG_ BMU_Voltage_C17_7 : 16|16@1+ (1,0) [0|0] "" Vector__XXX
 SG_ BMU_Voltage_C17_8 : 32|16@1+ (1,0) [0|0] "" Vector__XXX
 SG_ BMU_Voltage_Age_C17 : 48|16@1+ (1,0) [0|0] "" Vector__XXX

BO_ 2284093715 BMU_TransmitVoltage_N_17_P_3: 8 Vector__XXX
 SG_ BMU_Voltage_C17_9 : 0|16@1+ (1,0) [0|0] "" Vector__XXX
 SG_ BMU_Voltage_C17_10 : 16|16@1+ (1,0) [0|0] "" Vector__XXX
 SG_ BMU_Voltage_C17_11 : 32|16@1+ (1,0) [0|0] "" Vector__XXX
 SG_ BMU_Voltage_Age_C17 : 48|16@1+ (1,0) [0|0] "" Vector__XXX

BO_ 2284093716 BMU_TransmitVoltage_N_17_P_4: 8 Vector__XXX
 SG_ BMU_Voltage_C17_12 : 0|16@1+ (1,0) [0|0] "" Vector__XXX
 SG_ BMU_Voltage_C17_13 : 16|16@1+ (1,0) [0|0] "" Vector__XXX
 SG_ BMU_Voltage_Age_C17 : 48|16@1+ (1,0) [0|0] "" Vector__XXX

BO_ 2284093728 BMU_TransmitVoltage_N_18_P_0: 8 Vector__XXX
 SG_ BMU_Voltage_C18_0 : 0|16@1+ (1,0) [0|0] "" Vector__XXX
 SG_ BMU_Voltage_C18_1 : 16|16@1+ (1,0) [0|0] "" Vector__XXX
 SG_ BMU_Voltage_C18_2 : 32|16@1+ (1,0) [0|0] "" Vector__XXX
 SG_ BMU_Voltage_Age_C18 : 48|16@1+ (1,0) [0|0] "" Vector__XXX

BO_ 2284093729 BMU_TransmitVoltage_N_18_P_1: 8 Vector__XXX
 SG_ BMU_Voltage_C18_3 : 0|16@1+ (1,0) [0|0] "" Vector__XXX
 SG_ BMU_Voltage_C18_4 : 16|16@1+ (1,0) [0|0] "" Vector__XXX
 SG_ BMU_Voltage_C18_5 : 32|16@1+ (1,0) [0|0] "" Vector__XXX
 SG_ BMU_Voltage_Age_C18 : 48|16@1+ (1,0) [0|0] "" Vector__XXX

BO_ 2284093730 BMU_TransmitVoltage_N_18_P_2: 8 Vector__XXX
 SG_ BMU_Voltage_C18_6 : 0|16@1+ (1,0) [0|0] "" Vector__XXX
 SG_ BMU_Voltage_C18_7 : 16|16@1+ (1,0) [0|0] "" Vector__XXX
 SG_ BMU_Voltage_C18_8 : 32|16@1+ (1,0) [0|0] "" Vector__XXX
 SG_ BMU_Voltage_Age_C18 : 48|16@1+ (1,0) [0|0] "" Vector__XXX

BO_ 2284093731 BMU_TransmitVoltage_N_18_P_3: 8 Vector__XXX
 SG_ BMU_Voltage_C18_9 : 0|16@1+ (1,0) [0|0] "" Vector__XXX
 SG_ BMU_Voltage_C18_10 : 16|16@1+ (1,0) [0|0] "" Vector__XXX
 SG_ BMU_Voltage_C18_11 : 32|16@1+ (1,0) [0|0] "" Vector__XXX
 SG_ BMU_Voltage_Age_C18 : 48|16@1+ (1,0) [0|0] "" Vector__XXX

BO_ 2284093732 BMU_TransmitVoltage_N_18_P_4: 8 Vector__XXX
 SG_ BMU_Voltage_C18_12 : 0|16@1+ (1,0) [0|0] "" Vector__XXX
 SG_ BMU_Voltage_C18_13 : 16|16@1+ (1,0) [0|0] "" Vector__XXX
 SG_ BMU_Voltage_Age_C18 : 48|16@1+ (1,0) [0|0] "" Vector__XXX

BO_ 2284093744 BMU_TransmitVoltage_N_19_P_0: 8 Vector__XXX
 SG_ BMU_Voltage_C19_0 : 0|16@1+ (1,0) [0|0] "" Vector__XXX
 SG_ BMU_Voltage_C19_1 : 16|16@1+ (1,0) [0|0] "" Vector__XXX
 SG_ BMU_Voltage_C19_2 : 32|16@1+ (1,0) [0|0] "" Vector__XXX
 SG_ BMU_Voltage_Age_C19 : 48|16@1+ (1,0) [0|0] "" Vector__XXX

BO_ 2284093745 BMU_TransmitVoltage_N_19_P_1: 8 Vector__XXX
 SG_ BMU_Voltage_C19_3 : 0|16@1+ (1,0) [0|0] "" Vector__XXX
 SG_ BMU_Voltage_C19_4 : 16|16@1+ (1,0) [0|0] "" Vector__XXX
 SG_ BMU_Voltage_C19_5 : 32|16@1+ (1,0) [0|0] "" Vector__XXX
 SG_ BMU_Voltage_Age_C19 : 48|16@1+ (1,0) [0|0] "" Vector__XXX

BO_ 2284093746 BMU_TransmitVoltage_N_19_P_2: 8 Vector__XXX
 SG_ BMU_Voltage_C19_6 : 0|16@1+ (1,0) [0|0] "" Vector__XXX
 SG_ BMU_Voltage_C19_7 : 16|16@1+ (1,0) [0|0] "" Vector__XXX
 SG_ BMU_Voltage_C19_8 : 32|16@1+ (1,0) [0|0] "" Vector__XXX
 SG_ BMU_Voltage_Age_C19 : 48|16@1+ (1,0) [0|0] "" Vector__XXX

BO_ 2284093747 BMU_TransmitVoltage_N_19_P_3: 8 Vector__XXX
 SG_ BMU_Voltage_C19_9 : 0|16@1+ (1,0) [0|0] "" Vector__XXX
 SG_ BMU_Voltage_C19_10 : 16|16@1+ (1,0) [0|0] "" Vector__XXX
 SG_ BMU_Voltage_C19_11 : 32|16@1+ (1,0) [0|0] "" Vector__XXX
 SG_ BMU_Voltage_Age_C19 : 48|16@1+ (1,0) [0|0] "" Vector__XXX

BO_ 2284093748 BMU_TransmitVoltage_N_19_P_4: 8 Vector__XXX
 SG_ BMU_Voltage_C19_12 : 0|16@1+ (1,0) [0|0] "" Vector__XXX
 SG_ BMU_Voltage_C19_13 : 16|16@1+ (1,0) [0|0] "" Vector__XXX
 SG_ BMU_Voltage_Age_C19 : 48|16@1+ (1,0) [0|0] "" Vector__XXX

BO_ 2284094464 BMU_TransmitTemperature_N_0_P_0: 8 Vector__XXX
 SG_ BMU_Temperature_C0_0 : 0|8@1+ (1,0) [0|0] "" Vector__XXX
 SG_ BMU_Temperature_C0_1 : 8|8@1+ (1,0) [0|0] "" Vector__XXX
 SG_ BMU_Temperature_C0_2 : 16|8@1+ (1,0) [0|0] "" Vector__XXX
 SG_ BMU_Temperature_C0_3 : 24|8@1+ (1,0) [0|0] "" Vector__XXX
 SG_ BMU_Temperature_C0_4 : 32|8@1+ (1,0) [0|0] "" Vector__XXX
 SG_ BMU_Temperature_C0_5 : 40|8@1+ (1,0) [0|0] "" Vector__XXX
 SG_ BMU_Temperature_Age_C0 : 48|16@1+ (1,0) [0|0] "" Vector__XXX

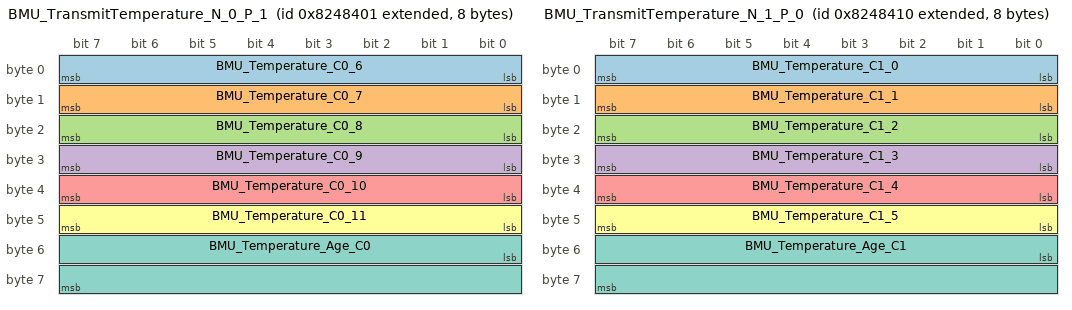
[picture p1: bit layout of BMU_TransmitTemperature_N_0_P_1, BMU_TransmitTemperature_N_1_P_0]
BO_ 2284094465 BMU_TransmitTemperature_N_0_P_1: 8 Vector__XXX
 SG_ BMU_Temperature_C0_6 : 0|8@1+ (1,0) [0|0] "" Vector__XXX
 SG_ BMU_Temperature_C0_7 : 8|8@1+ (1,0) [0|0] "" Vector__XXX
 SG_ BMU_Temperature_C0_8 : 16|8@1+ (1,0) [0|0] "" Vector__XXX
 SG_ BMU_Temperature_C0_9 : 24|8@1+ (1,0) [0|0] "" Vector__XXX
 SG_ BMU_Temperature_C0_10 : 32|8@1+ (1,0) [0|0] "" Vector__XXX
 SG_ BMU_Temperature_C0_11 : 40|8@1+ (1,0) [0|0] "" Vector__XXX
 SG_ BMU_Temperature_Age_C0 : 48|16@1+ (1,0) [0|0] "" Vector__XXX

BO_ 2284094466 BMU_TransmitTemperature_N_0_P_2: 8 Vector__XXX
 SG_ BMU_Temperature_C0_12 : 0|8@1+ (1,0) [0|0] "" Vector__XXX
 SG_ BMU_Temperature_C0_13 : 8|8@1+ (1,0) [0|0] "" Vector__XXX
 SG_ BMU_Temperature_C0_14 : 16|8@1+ (1,0) [0|0] "" Vector__XXX
 SG_ BMU_Temperature_C0_15 : 24|8@1+ (1,0) [0|0] "" Vector__XXX
 SG_ BMU_Temperature_Age_C0 : 48|16@1+ (1,0) [0|0] "" Vector__XXX

BO_ 2284094480 BMU_TransmitTemperature_N_1_P_0: 8 Vector__XXX
 SG_ BMU_Temperature_C1_0 : 0|8@1+ (1,0) [0|0] "" Vector__XXX
 SG_ BMU_Temperature_C1_1 : 8|8@1+ (1,0) [0|0] "" Vector__XXX
 SG_ BMU_Temperature_C1_2 : 16|8@1+ (1,0) [0|0] "" Vector__XXX
 SG_ BMU_Temperature_C1_3 : 24|8@1+ (1,0) [0|0] "" Vector__XXX
 SG_ BMU_Temperature_C1_4 : 32|8@1+ (1,0) [0|0] "" Vector__XXX
 SG_ BMU_Temperature_C1_5 : 40|8@1+ (1,0) [0|0] "" Vector__XXX
 SG_ BMU_Temperature_Age_C1 : 48|16@1+ (1,0) [0|0] "" Vector__XXX

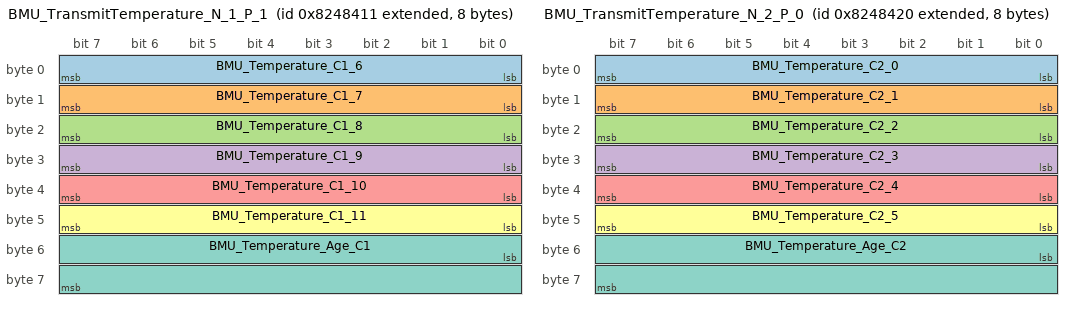
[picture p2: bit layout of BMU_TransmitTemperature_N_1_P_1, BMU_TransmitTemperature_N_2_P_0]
BO_ 2284094481 BMU_TransmitTemperature_N_1_P_1: 8 Vector__XXX
 SG_ BMU_Temperature_C1_6 : 0|8@1+ (1,0) [0|0] "" Vector__XXX
 SG_ BMU_Temperature_C1_7 : 8|8@1+ (1,0) [0|0] "" Vector__XXX
 SG_ BMU_Temperature_C1_8 : 16|8@1+ (1,0) [0|0] "" Vector__XXX
 SG_ BMU_Temperature_C1_9 : 24|8@1+ (1,0) [0|0] "" Vector__XXX
 SG_ BMU_Temperature_C1_10 : 32|8@1+ (1,0) [0|0] "" Vector__XXX
 SG_ BMU_Temperature_C1_11 : 40|8@1+ (1,0) [0|0] "" Vector__XXX
 SG_ BMU_Temperature_Age_C1 : 48|16@1+ (1,0) [0|0] "" Vector__XXX

BO_ 2284094482 BMU_TransmitTemperature_N_1_P_2: 8 Vector__XXX
 SG_ BMU_Temperature_C1_12 : 0|8@1+ (1,0) [0|0] "" Vector__XXX
 SG_ BMU_Temperature_C1_13 : 8|8@1+ (1,0) [0|0] "" Vector__XXX
 SG_ BMU_Temperature_C1_14 : 16|8@1+ (1,0) [0|0] "" Vector__XXX
 SG_ BMU_Temperature_C1_15 : 24|8@1+ (1,0) [0|0] "" Vector__XXX
 SG_ BMU_Temperature_Age_C1 : 48|16@1+ (1,0) [0|0] "" Vector__XXX

BO_ 2284094496 BMU_TransmitTemperature_N_2_P_0: 8 Vector__XXX
 SG_ BMU_Temperature_C2_0 : 0|8@1+ (1,0) [0|0] "" Vector__XXX
 SG_ BMU_Temperature_C2_1 : 8|8@1+ (1,0) [0|0] "" Vector__XXX
 SG_ BMU_Temperature_C2_2 : 16|8@1+ (1,0) [0|0] "" Vector__XXX
 SG_ BMU_Temperature_C2_3 : 24|8@1+ (1,0) [0|0] "" Vector__XXX
 SG_ BMU_Temperature_C2_4 : 32|8@1+ (1,0) [0|0] "" Vector__XXX
 SG_ BMU_Temperature_C2_5 : 40|8@1+ (1,0) [0|0] "" Vector__XXX
 SG_ BMU_Temperature_Age_C2 : 48|16@1+ (1,0) [0|0] "" Vector__XXX

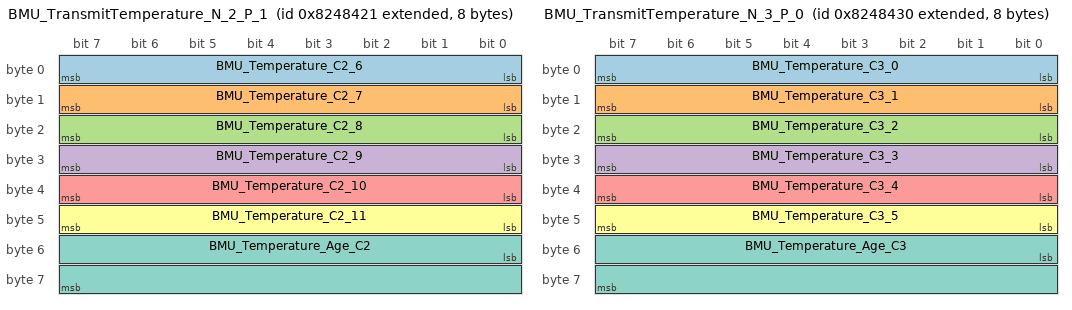
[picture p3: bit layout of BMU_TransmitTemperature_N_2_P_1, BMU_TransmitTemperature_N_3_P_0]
BO_ 2284094497 BMU_TransmitTemperature_N_2_P_1: 8 Vector__XXX
 SG_ BMU_Temperature_C2_6 : 0|8@1+ (1,0) [0|0] "" Vector__XXX
 SG_ BMU_Temperature_C2_7 : 8|8@1+ (1,0) [0|0] "" Vector__XXX
 SG_ BMU_Temperature_C2_8 : 16|8@1+ (1,0) [0|0] "" Vector__XXX
 SG_ BMU_Temperature_C2_9 : 24|8@1+ (1,0) [0|0] "" Vector__XXX
 SG_ BMU_Temperature_C2_10 : 32|8@1+ (1,0) [0|0] "" Vector__XXX
 SG_ BMU_Temperature_C2_11 : 40|8@1+ (1,0) [0|0] "" Vector__XXX
 SG_ BMU_Temperature_Age_C2 : 48|16@1+ (1,0) [0|0] "" Vector__XXX

BO_ 2284094498 BMU_TransmitTemperature_N_2_P_2: 8 Vector__XXX
 SG_ BMU_Temperature_C2_12 : 0|8@1+ (1,0) [0|0] "" Vector__XXX
 SG_ BMU_Temperature_C2_13 : 8|8@1+ (1,0) [0|0] "" Vector__XXX
 SG_ BMU_Temperature_C2_14 : 16|8@1+ (1,0) [0|0] "" Vector__XXX
 SG_ BMU_Temperature_C2_15 : 24|8@1+ (1,0) [0|0] "" Vector__XXX
 SG_ BMU_Temperature_Age_C2 : 48|16@1+ (1,0) [0|0] "" Vector__XXX

BO_ 2284094512 BMU_TransmitTemperature_N_3_P_0: 8 Vector__XXX
 SG_ BMU_Temperature_C3_0 : 0|8@1+ (1,0) [0|0] "" Vector__XXX
 SG_ BMU_Temperature_C3_1 : 8|8@1+ (1,0) [0|0] "" Vector__XXX
 SG_ BMU_Temperature_C3_2 : 16|8@1+ (1,0) [0|0] "" Vector__XXX
 SG_ BMU_Temperature_C3_3 : 24|8@1+ (1,0) [0|0] "" Vector__XXX
 SG_ BMU_Temperature_C3_4 : 32|8@1+ (1,0) [0|0] "" Vector__XXX
 SG_ BMU_Temperature_C3_5 : 40|8@1+ (1,0) [0|0] "" Vector__XXX
 SG_ BMU_Temperature_Age_C3 : 48|16@1+ (1,0) [0|0] "" Vector__XXX

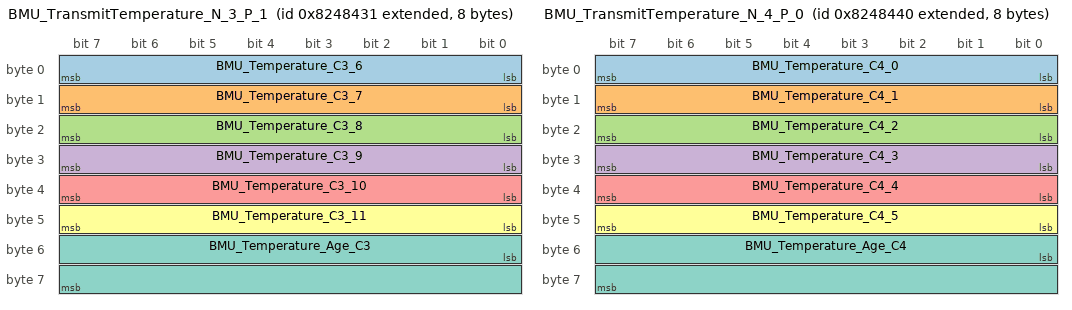
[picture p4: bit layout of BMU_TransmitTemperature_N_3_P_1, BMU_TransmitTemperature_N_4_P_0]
BO_ 2284094513 BMU_TransmitTemperature_N_3_P_1: 8 Vector__XXX
 SG_ BMU_Temperature_C3_6 : 0|8@1+ (1,0) [0|0] "" Vector__XXX
 SG_ BMU_Temperature_C3_7 : 8|8@1+ (1,0) [0|0] "" Vector__XXX
 SG_ BMU_Temperature_C3_8 : 16|8@1+ (1,0) [0|0] "" Vector__XXX
 SG_ BMU_Temperature_C3_9 : 24|8@1+ (1,0) [0|0] "" Vector__XXX
 SG_ BMU_Temperature_C3_10 : 32|8@1+ (1,0) [0|0] "" Vector__XXX
 SG_ BMU_Temperature_C3_11 : 40|8@1+ (1,0) [0|0] "" Vector__XXX
 SG_ BMU_Temperature_Age_C3 : 48|16@1+ (1,0) [0|0] "" Vector__XXX

BO_ 2284094514 BMU_TransmitTemperature_N_3_P_2: 8 Vector__XXX
 SG_ BMU_Temperature_C3_12 : 0|8@1+ (1,0) [0|0] "" Vector__XXX
 SG_ BMU_Temperature_C3_13 : 8|8@1+ (1,0) [0|0] "" Vector__XXX
 SG_ BMU_Temperature_C3_14 : 16|8@1+ (1,0) [0|0] "" Vector__XXX
 SG_ BMU_Temperature_C3_15 : 24|8@1+ (1,0) [0|0] "" Vector__XXX
 SG_ BMU_Temperature_Age_C3 : 48|16@1+ (1,0) [0|0] "" Vector__XXX

BO_ 2284094528 BMU_TransmitTemperature_N_4_P_0: 8 Vector__XXX
 SG_ BMU_Temperature_C4_0 : 0|8@1+ (1,0) [0|0] "" Vector__XXX
 SG_ BMU_Temperature_C4_1 : 8|8@1+ (1,0) [0|0] "" Vector__XXX
 SG_ BMU_Temperature_C4_2 : 16|8@1+ (1,0) [0|0] "" Vector__XXX
 SG_ BMU_Temperature_C4_3 : 24|8@1+ (1,0) [0|0] "" Vector__XXX
 SG_ BMU_Temperature_C4_4 : 32|8@1+ (1,0) [0|0] "" Vector__XXX
 SG_ BMU_Temperature_C4_5 : 40|8@1+ (1,0) [0|0] "" Vector__XXX
 SG_ BMU_Temperature_Age_C4 : 48|16@1+ (1,0) [0|0] "" Vector__XXX

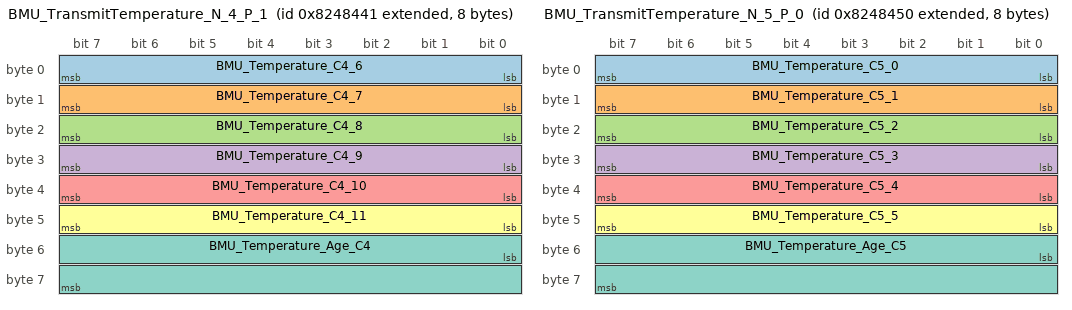
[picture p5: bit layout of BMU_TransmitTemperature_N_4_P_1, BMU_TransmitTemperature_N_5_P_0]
BO_ 2284094529 BMU_TransmitTemperature_N_4_P_1: 8 Vector__XXX
 SG_ BMU_Temperature_C4_6 : 0|8@1+ (1,0) [0|0] "" Vector__XXX
 SG_ BMU_Temperature_C4_7 : 8|8@1+ (1,0) [0|0] "" Vector__XXX
 SG_ BMU_Temperature_C4_8 : 16|8@1+ (1,0) [0|0] "" Vector__XXX
 SG_ BMU_Temperature_C4_9 : 24|8@1+ (1,0) [0|0] "" Vector__XXX
 SG_ BMU_Temperature_C4_10 : 32|8@1+ (1,0) [0|0] "" Vector__XXX
 SG_ BMU_Temperature_C4_11 : 40|8@1+ (1,0) [0|0] "" Vector__XXX
 SG_ BMU_Temperature_Age_C4 : 48|16@1+ (1,0) [0|0] "" Vector__XXX

BO_ 2284094530 BMU_TransmitTemperature_N_4_P_2: 8 Vector__XXX
 SG_ BMU_Temperature_C4_12 : 0|8@1+ (1,0) [0|0] "" Vector__XXX
 SG_ BMU_Temperature_C4_13 : 8|8@1+ (1,0) [0|0] "" Vector__XXX
 SG_ BMU_Temperature_C4_14 : 16|8@1+ (1,0) [0|0] "" Vector__XXX
 SG_ BMU_Temperature_C4_15 : 24|8@1+ (1,0) [0|0] "" Vector__XXX
 SG_ BMU_Temperature_Age_C4 : 48|16@1+ (1,0) [0|0] "" Vector__XXX

BO_ 2284094544 BMU_TransmitTemperature_N_5_P_0: 8 Vector__XXX
 SG_ BMU_Temperature_C5_0 : 0|8@1+ (1,0) [0|0] "" Vector__XXX
 SG_ BMU_Temperature_C5_1 : 8|8@1+ (1,0) [0|0] "" Vector__XXX
 SG_ BMU_Temperature_C5_2 : 16|8@1+ (1,0) [0|0] "" Vector__XXX
 SG_ BMU_Temperature_C5_3 : 24|8@1+ (1,0) [0|0] "" Vector__XXX
 SG_ BMU_Temperature_C5_4 : 32|8@1+ (1,0) [0|0] "" Vector__XXX
 SG_ BMU_Temperature_C5_5 : 40|8@1+ (1,0) [0|0] "" Vector__XXX
 SG_ BMU_Temperature_Age_C5 : 48|16@1+ (1,0) [0|0] "" Vector__XXX

BO_ 2284094545 BMU_TransmitTemperature_N_5_P_1: 8 Vector__XXX
 SG_ BMU_Temperature_C5_6 : 0|8@1+ (1,0) [0|0] "" Vector__XXX
 SG_ BMU_Temperature_C5_7 : 8|8@1+ (1,0) [0|0] "" Vector__XXX
 SG_ BMU_Temperature_C5_8 : 16|8@1+ (1,0) [0|0] "" Vector__XXX
 SG_ BMU_Temperature_C5_9 : 24|8@1+ (1,0) [0|0] "" Vector__XXX
 SG_ BMU_Temperature_C5_10 : 32|8@1+ (1,0) [0|0] "" Vector__XXX
 SG_ BMU_Temperature_C5_11 : 40|8@1+ (1,0) [0|0] "" Vector__XXX
 SG_ BMU_Temperature_Age_C5 : 48|16@1+ (1,0) [0|0] "" Vector__XXX

BO_ 2284094546 BMU_TransmitTemperature_N_5_P_2: 8 Vector__XXX
 SG_ BMU_Temperature_C5_12 : 0|8@1+ (1,0) [0|0] "" Vector__XXX
 SG_ BMU_Temperature_C5_13 : 8|8@1+ (1,0) [0|0] "" Vector__XXX
 SG_ BMU_Temperature_C5_14 : 16|8@1+ (1,0) [0|0] "" Vector__XXX
 SG_ BMU_Temperature_C5_15 : 24|8@1+ (1,0) [0|0] "" Vector__XXX
 SG_ BMU_Temperature_Age_C5 : 48|16@1+ (1,0) [0|0] "" Vector__XXX

BO_ 2284094560 BMU_TransmitTemperature_N_6_P_0: 8 Vector__XXX
 SG_ BMU_Temperature_C6_0 : 0|8@1+ (1,0) [0|0] "" Vector__XXX
 SG_ BMU_Temperature_C6_1 : 8|8@1+ (1,0) [0|0] "" Vector__XXX
 SG_ BMU_Temperature_C6_2 : 16|8@1+ (1,0) [0|0] "" Vector__XXX
 SG_ BMU_Temperature_C6_3 : 24|8@1+ (1,0) [0|0] "" Vector__XXX
 SG_ BMU_Temperature_C6_4 : 32|8@1+ (1,0) [0|0] "" Vector__XXX
 SG_ BMU_Temperature_C6_5 : 40|8@1+ (1,0) [0|0] "" Vector__XXX
 SG_ BMU_Temperature_Age_C6 : 48|16@1+ (1,0) [0|0] "" Vector__XXX

BO_ 2284094561 BMU_TransmitTemperature_N_6_P_1: 8 Vector__XXX
 SG_ BMU_Temperature_C6_6 : 0|8@1+ (1,0) [0|0] "" Vector__XXX
 SG_ BMU_Temperature_C6_7 : 8|8@1+ (1,0) [0|0] "" Vector__XXX
 SG_ BMU_Temperature_C6_8 : 16|8@1+ (1,0) [0|0] "" Vector__XXX
 SG_ BMU_Temperature_C6_9 : 24|8@1+ (1,0) [0|0] "" Vector__XXX
 SG_ BMU_Temperature_C6_10 : 32|8@1+ (1,0) [0|0] "" Vector__XXX
 SG_ BMU_Temperature_C6_11 : 40|8@1+ (1,0) [0|0] "" Vector__XXX
 SG_ BMU_Temperature_Age_C6 : 48|16@1+ (1,0) [0|0] "" Vector__XXX

BO_ 2284094562 BMU_TransmitTemperature_N_6_P_2: 8 Vector__XXX
 SG_ BMU_Temperature_C6_12 : 0|8@1+ (1,0) [0|0] "" Vector__XXX
 SG_ BMU_Temperature_C6_13 : 8|8@1+ (1,0) [0|0] "" Vector__XXX
 SG_ BMU_Temperature_C6_14 : 16|8@1+ (1,0) [0|0] "" Vector__XXX
 SG_ BMU_Temperature_C6_15 : 24|8@1+ (1,0) [0|0] "" Vector__XXX
 SG_ BMU_Temperature_Age_C6 : 48|16@1+ (1,0) [0|0] "" Vector__XXX

BO_ 2284094576 BMU_TransmitTemperature_N_7_P_0: 8 Vector__XXX
 SG_ BMU_Temperature_C7_0 : 0|8@1+ (1,0) [0|0] "" Vector__XXX
 SG_ BMU_Temperature_C7_1 : 8|8@1+ (1,0) [0|0] "" Vector__XXX
 SG_ BMU_Temperature_C7_2 : 16|8@1+ (1,0) [0|0] "" Vector__XXX
 SG_ BMU_Temperature_C7_3 : 24|8@1+ (1,0) [0|0] "" Vector__XXX
 SG_ BMU_Temperature_C7_4 : 32|8@1+ (1,0) [0|0] "" Vector__XXX
 SG_ BMU_Temperature_C7_5 : 40|8@1+ (1,0) [0|0] "" Vector__XXX
 SG_ BMU_Temperature_Age_C7 : 48|16@1+ (1,0) [0|0] "" Vector__XXX

BO_ 2284094577 BMU_TransmitTemperature_N_7_P_1: 8 Vector__XXX
 SG_ BMU_Temperature_C7_6 : 0|8@1+ (1,0) [0|0] "" Vector__XXX
 SG_ BMU_Temperature_C7_7 : 8|8@1+ (1,0) [0|0] "" Vector__XXX
 SG_ BMU_Temperature_C7_8 : 16|8@1+ (1,0) [0|0] "" Vector__XXX
 SG_ BMU_Temperature_C7_9 : 24|8@1+ (1,0) [0|0] "" Vector__XXX
 SG_ BMU_Temperature_C7_10 : 32|8@1+ (1,0) [0|0] "" Vector__XXX
 SG_ BMU_Temperature_C7_11 : 40|8@1+ (1,0) [0|0] "" Vector__XXX
 SG_ BMU_Temperature_Age_C7 : 48|16@1+ (1,0) [0|0] "" Vector__XXX

BO_ 2284094578 BMU_TransmitTemperature_N_7_P_2: 8 Vector__XXX
 SG_ BMU_Temperature_C7_12 : 0|8@1+ (1,0) [0|0] "" Vector__XXX
 SG_ BMU_Temperature_C7_13 : 8|8@1+ (1,0) [0|0] "" Vector__XXX
 SG_ BMU_Temperature_C7_14 : 16|8@1+ (1,0) [0|0] "" Vector__XXX
 SG_ BMU_Temperature_C7_15 : 24|8@1+ (1,0) [0|0] "" Vector__XXX
 SG_ BMU_Temperature_Age_C7 : 48|16@1+ (1,0) [0|0] "" Vector__XXX

BO_ 2284094592 BMU_TransmitTemperature_N_8_P_0: 8 Vector__XXX
 SG_ BMU_Temperature_C8_0 : 0|8@1+ (1,0) [0|0] "" Vector__XXX
 SG_ BMU_Temperature_C8_1 : 8|8@1+ (1,0) [0|0] "" Vector__XXX
 SG_ BMU_Temperature_C8_2 : 16|8@1+ (1,0) [0|0] "" Vector__XXX
 SG_ BMU_Temperature_C8_3 : 24|8@1+ (1,0) [0|0] "" Vector__XXX
 SG_ BMU_Temperature_C8_4 : 32|8@1+ (1,0) [0|0] "" Vector__XXX
 SG_ BMU_Temperature_C8_5 : 40|8@1+ (1,0) [0|0] "" Vector__XXX
 SG_ BMU_Temperature_Age_C8 : 48|16@1+ (1,0) [0|0] "" Vector__XXX

BO_ 2284094593 BMU_TransmitTemperature_N_8_P_1: 8 Vector__XXX
 SG_ BMU_Temperature_C8_6 : 0|8@1+ (1,0) [0|0] "" Vector__XXX
 SG_ BMU_Temperature_C8_7 : 8|8@1+ (1,0) [0|0] "" Vector__XXX
 SG_ BMU_Temperature_C8_8 : 16|8@1+ (1,0) [0|0] "" Vector__XXX
 SG_ BMU_Temperature_C8_9 : 24|8@1+ (1,0) [0|0] "" Vector__XXX
 SG_ BMU_Temperature_C8_10 : 32|8@1+ (1,0) [0|0] "" Vector__XXX
 SG_ BMU_Temperature_C8_11 : 40|8@1+ (1,0) [0|0] "" Vector__XXX
 SG_ BMU_Temperature_Age_C8 : 48|16@1+ (1,0) [0|0] "" Vector__XXX

BO_ 2284094594 BMU_TransmitTemperature_N_8_P_2: 8 Vector__XXX
 SG_ BMU_Temperature_C8_12 : 0|8@1+ (1,0) [0|0] "" Vector__XXX
 SG_ BMU_Temperature_C8_13 : 8|8@1+ (1,0) [0|0] "" Vector__XXX
 SG_ BMU_Temperature_C8_14 : 16|8@1+ (1,0) [0|0] "" Vector__XXX
 SG_ BMU_Temperature_C8_15 : 24|8@1+ (1,0) [0|0] "" Vector__XXX
 SG_ BMU_Temperature_Age_C8 : 48|16@1+ (1,0) [0|0] "" Vector__XXX

BO_ 2284094608 BMU_TransmitTemperature_N_9_P_0: 8 Vector__XXX
 SG_ BMU_Temperature_C9_0 : 0|8@1+ (1,0) [0|0] "" Vector__XXX
 SG_ BMU_Temperature_C9_1 : 8|8@1+ (1,0) [0|0] "" Vector__XXX
 SG_ BMU_Temperature_C9_2 : 16|8@1+ (1,0) [0|0] "" Vector__XXX
 SG_ BMU_Temperature_C9_3 : 24|8@1+ (1,0) [0|0] "" Vector__XXX
 SG_ BMU_Temperature_C9_4 : 32|8@1+ (1,0) [0|0] "" Vector__XXX
 SG_ BMU_Temperature_C9_5 : 40|8@1+ (1,0) [0|0] "" Vector__XXX
 SG_ BMU_Temperature_Age_C9 : 48|16@1+ (1,0) [0|0] "" Vector__XXX

BO_ 2284094609 BMU_TransmitTemperature_N_9_P_1: 8 Vector__XXX
 SG_ BMU_Temperature_C9_6 : 0|8@1+ (1,0) [0|0] "" Vector__XXX
 SG_ BMU_Temperature_C9_7 : 8|8@1+ (1,0) [0|0] "" Vector__XXX
 SG_ BMU_Temperature_C9_8 : 16|8@1+ (1,0) [0|0] "" Vector__XXX
 SG_ BMU_Temperature_C9_9 : 24|8@1+ (1,0) [0|0] "" Vector__XXX
 SG_ BMU_Temperature_C9_10 : 32|8@1+ (1,0) [0|0] "" Vector__XXX
 SG_ BMU_Temperature_C9_11 : 40|8@1+ (1,0) [0|0] "" Vector__XXX
 SG_ BMU_Temperature_Age_C9 : 48|16@1+ (1,0) [0|0] "" Vector__XXX

BO_ 2284094610 BMU_TransmitTemperature_N_9_P_2: 8 Vector__XXX
 SG_ BMU_Temperature_C9_12 : 0|8@1+ (1,0) [0|0] "" Vector__XXX
 SG_ BMU_Temperature_C9_13 : 8|8@1+ (1,0) [0|0] "" Vector__XXX
 SG_ BMU_Temperature_C9_14 : 16|8@1+ (1,0) [0|0] "" Vector__XXX
 SG_ BMU_Temperature_C9_15 : 24|8@1+ (1,0) [0|0] "" Vector__XXX
 SG_ BMU_Temperature_Age_C9 : 48|16@1+ (1,0) [0|0] "" Vector__XXX

BO_ 2284094624 BMU_TransmitTemperature_N_10_P_0: 8 Vector__XXX
 SG_ BMU_Temperature_C10_0 : 0|8@1+ (1,0) [0|0] "" Vector__XXX
 SG_ BMU_Temperature_C10_1 : 8|8@1+ (1,0) [0|0] "" Vector__XXX
 SG_ BMU_Temperature_C10_2 : 16|8@1+ (1,0) [0|0] "" Vector__XXX
 SG_ BMU_Temperature_C10_3 : 24|8@1+ (1,0) [0|0] "" Vector__XXX
 SG_ BMU_Temperature_C10_4 : 32|8@1+ (1,0) [0|0] "" Vector__XXX
 SG_ BMU_Temperature_C10_5 : 40|8@1+ (1,0) [0|0] "" Vector__XXX
 SG_ BMU_Temperature_Age_C10 : 48|16@1+ (1,0) [0|0] "" Vector__XXX

BO_ 2284094625 BMU_TransmitTemperature_N_10_P_1: 8 Vector__XXX
 SG_ BMU_Temperature_C10_6 : 0|8@1+ (1,0) [0|0] "" Vector__XXX
 SG_ BMU_Temperature_C10_7 : 8|8@1+ (1,0) [0|0] "" Vector__XXX
 SG_ BMU_Temperature_C10_8 : 16|8@1+ (1,0) [0|0] "" Vector__XXX
 SG_ BMU_Temperature_C10_9 : 24|8@1+ (1,0) [0|0] "" Vector__XXX
 SG_ BMU_Temperature_C10_10 : 32|8@1+ (1,0) [0|0] "" Vector__XXX
 SG_ BMU_Temperature_C10_11 : 40|8@1+ (1,0) [0|0] "" Vector__XXX
 SG_ BMU_Temperature_Age_C10 : 48|16@1+ (1,0) [0|0] "" Vector__XXX

BO_ 2284094626 BMU_TransmitTemperature_N_10_P_2: 8 Vector__XXX
 SG_ BMU_Temperature_C10_12 : 0|8@1+ (1,0) [0|0] "" Vector__XXX
 SG_ BMU_Temperature_C10_13 : 8|8@1+ (1,0) [0|0] "" Vector__XXX
 SG_ BMU_Temperature_C10_14 : 16|8@1+ (1,0) [0|0] "" Vector__XXX
 SG_ BMU_Temperature_C10_15 : 24|8@1+ (1,0) [0|0] "" Vector__XXX
 SG_ BMU_Temperature_Age_C10 : 48|16@1+ (1,0) [0|0] "" Vector__XXX

BO_ 2284094640 BMU_TransmitTemperature_N_11_P_0: 8 Vector__XXX
 SG_ BMU_Temperature_C11_0 : 0|8@1+ (1,0) [0|0] "" Vector__XXX
 SG_ BMU_Temperature_C11_1 : 8|8@1+ (1,0) [0|0] "" Vector__XXX
 SG_ BMU_Temperature_C11_2 : 16|8@1+ (1,0) [0|0] "" Vector__XXX
 SG_ BMU_Temperature_C11_3 : 24|8@1+ (1,0) [0|0] "" Vector__XXX
 SG_ BMU_Temperature_C11_4 : 32|8@1+ (1,0) [0|0] "" Vector__XXX
 SG_ BMU_Temperature_C11_5 : 40|8@1+ (1,0) [0|0] "" Vector__XXX
 SG_ BMU_Temperature_Age_C11 : 48|16@1+ (1,0) [0|0] "" Vector__XXX

BO_ 2284094641 BMU_TransmitTemperature_N_11_P_1: 8 Vector__XXX
 SG_ BMU_Temperature_C11_6 : 0|8@1+ (1,0) [0|0] "" Vector__XXX
 SG_ BMU_Temperature_C11_7 : 8|8@1+ (1,0) [0|0] "" Vector__XXX
 SG_ BMU_Temperature_C11_8 : 16|8@1+ (1,0) [0|0] "" Vector__XXX
 SG_ BMU_Temperature_C11_9 : 24|8@1+ (1,0) [0|0] "" Vector__XXX
 SG_ BMU_Temperature_C11_10 : 32|8@1+ (1,0) [0|0] "" Vector__XXX
 SG_ BMU_Temperature_C11_11 : 40|8@1+ (1,0) [0|0] "" Vector__XXX
 SG_ BMU_Temperature_Age_C11 : 48|16@1+ (1,0) [0|0] "" Vector__XXX

BO_ 2284094642 BMU_TransmitTemperature_N_11_P_2: 8 Vector__XXX
 SG_ BMU_Temperature_C11_12 : 0|8@1+ (1,0) [0|0] "" Vector__XXX
 SG_ BMU_Temperature_C11_13 : 8|8@1+ (1,0) [0|0] "" Vector__XXX
 SG_ BMU_Temperature_C11_14 : 16|8@1+ (1,0) [0|0] "" Vector__XXX
 SG_ BMU_Temperature_C11_15 : 24|8@1+ (1,0) [0|0] "" Vector__XXX
 SG_ BMU_Temperature_Age_C11 : 48|16@1+ (1,0) [0|0] "" Vector__XXX

BO_ 2284094656 BMU_TransmitTemperature_N_12_P_0: 8 Vector__XXX
 SG_ BMU_Temperature_C12_0 : 0|8@1+ (1,0) [0|0] "" Vector__XXX
 SG_ BMU_Temperature_C12_1 : 8|8@1+ (1,0) [0|0] "" Vector__XXX
 SG_ BMU_Temperature_C12_2 : 16|8@1+ (1,0) [0|0] "" Vector__XXX
 SG_ BMU_Temperature_C12_3 : 24|8@1+ (1,0) [0|0] "" Vector__XXX
 SG_ BMU_Temperature_C12_4 : 32|8@1+ (1,0) [0|0] "" Vector__XXX
 SG_ BMU_Temperature_C12_5 : 40|8@1+ (1,0) [0|0] "" Vector__XXX
 SG_ BMU_Temperature_Age_C12 : 48|16@1+ (1,0) [0|0] "" Vector__XXX

BO_ 2284094657 BMU_TransmitTemperature_N_12_P_1: 8 Vector__XXX
 SG_ BMU_Temperature_C12_6 : 0|8@1+ (1,0) [0|0] "" Vector__XXX
 SG_ BMU_Temperature_C12_7 : 8|8@1+ (1,0) [0|0] "" Vector__XXX
 SG_ BMU_Temperature_C12_8 : 16|8@1+ (1,0) [0|0] "" Vector__XXX
 SG_ BMU_Temperature_C12_9 : 24|8@1+ (1,0) [0|0] "" Vector__XXX
 SG_ BMU_Temperature_C12_10 : 32|8@1+ (1,0) [0|0] "" Vector__XXX
 SG_ BMU_Temperature_C12_11 : 40|8@1+ (1,0) [0|0] "" Vector__XXX
 SG_ BMU_Temperature_Age_C12 : 48|16@1+ (1,0) [0|0] "" Vector__XXX

BO_ 2284094658 BMU_TransmitTemperature_N_12_P_2: 8 Vector__XXX
 SG_ BMU_Temperature_C12_12 : 0|8@1+ (1,0) [0|0] "" Vector__XXX
 SG_ BMU_Temperature_C12_13 : 8|8@1+ (1,0) [0|0] "" Vector__XXX
 SG_ BMU_Temperature_C12_14 : 16|8@1+ (1,0) [0|0] "" Vector__XXX
 SG_ BMU_Temperature_C12_15 : 24|8@1+ (1,0) [0|0] "" Vector__XXX
 SG_ BMU_Temperature_Age_C12 : 48|16@1+ (1,0) [0|0] "" Vector__XXX

BO_ 2284094672 BMU_TransmitTemperature_N_13_P_0: 8 Vector__XXX
 SG_ BMU_Temperature_C13_0 : 0|8@1+ (1,0) [0|0] "" Vector__XXX
 SG_ BMU_Temperature_C13_1 : 8|8@1+ (1,0) [0|0] "" Vector__XXX
 SG_ BMU_Temperature_C13_2 : 16|8@1+ (1,0) [0|0] "" Vector__XXX
 SG_ BMU_Temperature_C13_3 : 24|8@1+ (1,0) [0|0] "" Vector__XXX
 SG_ BMU_Temperature_C13_4 : 32|8@1+ (1,0) [0|0] "" Vector__XXX
 SG_ BMU_Temperature_C13_5 : 40|8@1+ (1,0) [0|0] "" Vector__XXX
 SG_ BMU_Temperature_Age_C13 : 48|16@1+ (1,0) [0|0] "" Vector__XXX

BO_ 2284094673 BMU_TransmitTemperature_N_13_P_1: 8 Vector__XXX
 SG_ BMU_Temperature_C13_6 : 0|8@1+ (1,0) [0|0] "" Vector__XXX
 SG_ BMU_Temperature_C13_7 : 8|8@1+ (1,0) [0|0] "" Vector__XXX
 SG_ BMU_Temperature_C13_8 : 16|8@1+ (1,0) [0|0] "" Vector__XXX
 SG_ BMU_Temperature_C13_9 : 24|8@1+ (1,0) [0|0] "" Vector__XXX
 SG_ BMU_Temperature_C13_10 : 32|8@1+ (1,0) [0|0] "" Vector__XXX
 SG_ BMU_Temperature_C13_11 : 40|8@1+ (1,0) [0|0] "" Vector__XXX
 SG_ BMU_Temperature_Age_C13 : 48|16@1+ (1,0) [0|0] "" Vector__XXX

BO_ 2284094674 BMU_TransmitTemperature_N_13_P_2: 8 Vector__XXX
 SG_ BMU_Temperature_C13_12 : 0|8@1+ (1,0) [0|0] "" Vector__XXX
 SG_ BMU_Temperature_C13_13 : 8|8@1+ (1,0) [0|0] "" Vector__XXX
 SG_ BMU_Temperature_C13_14 : 16|8@1+ (1,0) [0|0] "" Vector__XXX
 SG_ BMU_Temperature_C13_15 : 24|8@1+ (1,0) [0|0] "" Vector__XXX
 SG_ BMU_Temperature_Age_C13 : 48|16@1+ (1,0) [0|0] "" Vector__XXX

BO_ 2284094688 BMU_TransmitTemperature_N_14_P_0: 8 Vector__XXX
 SG_ BMU_Temperature_C14_0 : 0|8@1+ (1,0) [0|0] "" Vector__XXX
 SG_ BMU_Temperature_C14_1 : 8|8@1+ (1,0) [0|0] "" Vector__XXX
 SG_ BMU_Temperature_C14_2 : 16|8@1+ (1,0) [0|0] "" Vector__XXX
 SG_ BMU_Temperature_C14_3 : 24|8@1+ (1,0) [0|0] "" Vector__XXX
 SG_ BMU_Temperature_C14_4 : 32|8@1+ (1,0) [0|0] "" Vector__XXX
 SG_ BMU_Temperature_C14_5 : 40|8@1+ (1,0) [0|0] "" Vector__XXX
 SG_ BMU_Temperature_Age_C14 : 48|16@1+ (1,0) [0|0] "" Vector__XXX

BO_ 2284094689 BMU_TransmitTemperature_N_14_P_1: 8 Vector__XXX
 SG_ BMU_Temperature_C14_6 : 0|8@1+ (1,0) [0|0] "" Vector__XXX
 SG_ BMU_Temperature_C14_7 : 8|8@1+ (1,0) [0|0] "" Vector__XXX
 SG_ BMU_Temperature_C14_8 : 16|8@1+ (1,0) [0|0] "" Vector__XXX
 SG_ BMU_Temperature_C14_9 : 24|8@1+ (1,0) [0|0] "" Vector__XXX
 SG_ BMU_Temperature_C14_10 : 32|8@1+ (1,0) [0|0] "" Vector__XXX
 SG_ BMU_Temperature_C14_11 : 40|8@1+ (1,0) [0|0] "" Vector__XXX
 SG_ BMU_Temperature_Age_C14 : 48|16@1+ (1,0) [0|0] "" Vector__XXX

BO_ 2284094690 BMU_TransmitTemperature_N_14_P_2: 8 Vector__XXX
 SG_ BMU_Temperature_C14_12 : 0|8@1+ (1,0) [0|0] "" Vector__XXX
 SG_ BMU_Temperature_C14_13 : 8|8@1+ (1,0) [0|0] "" Vector__XXX
 SG_ BMU_Temperature_C14_14 : 16|8@1+ (1,0) [0|0] "" Vector__XXX
 SG_ BMU_Temperature_C14_15 : 24|8@1+ (1,0) [0|0] "" Vector__XXX
 SG_ BMU_Temperature_Age_C14 : 48|16@1+ (1,0) [0|0] "" Vector__XXX

BO_ 2284094704 BMU_TransmitTemperature_N_15_P_0: 8 Vector__XXX
 SG_ BMU_Temperature_C15_0 : 0|8@1+ (1,0) [0|0] "" Vector__XXX
 SG_ BMU_Temperature_C15_1 : 8|8@1+ (1,0) [0|0] "" Vector__XXX
 SG_ BMU_Temperature_C15_2 : 16|8@1+ (1,0) [0|0] "" Vector__XXX
 SG_ BMU_Temperature_C15_3 : 24|8@1+ (1,0) [0|0] "" Vector__XXX
 SG_ BMU_Temperature_C15_4 : 32|8@1+ (1,0) [0|0] "" Vector__XXX
 SG_ BMU_Temperature_C15_5 : 40|8@1+ (1,0) [0|0] "" Vector__XXX
 SG_ BMU_Temperature_Age_C15 : 48|16@1+ (1,0) [0|0] "" Vector__XXX

BO_ 2284094705 BMU_TransmitTemperature_N_15_P_1: 8 Vector__XXX
 SG_ BMU_Temperature_C15_6 : 0|8@1+ (1,0) [0|0] "" Vector__XXX
 SG_ BMU_Temperature_C15_7 : 8|8@1+ (1,0) [0|0] "" Vector__XXX
 SG_ BMU_Temperature_C15_8 : 16|8@1+ (1,0) [0|0] "" Vector__XXX
 SG_ BMU_Temperature_C15_9 : 24|8@1+ (1,0) [0|0] "" Vector__XXX
 SG_ BMU_Temperature_C15_10 : 32|8@1+ (1,0) [0|0] "" Vector__XXX
 SG_ BMU_Temperature_C15_11 : 40|8@1+ (1,0) [0|0] "" Vector__XXX
 SG_ BMU_Temperature_Age_C15 : 48|16@1+ (1,0) [0|0] "" Vector__XXX

BO_ 2284094706 BMU_TransmitTemperature_N_15_P_2: 8 Vector__XXX
 SG_ BMU_Temperature_C15_12 : 0|8@1+ (1,0) [0|0] "" Vector__XXX
 SG_ BMU_Temperature_C15_13 : 8|8@1+ (1,0) [0|0] "" Vector__XXX
 SG_ BMU_Temperature_C15_14 : 16|8@1+ (1,0) [0|0] "" Vector__XXX
 SG_ BMU_Temperature_C15_15 : 24|8@1+ (1,0) [0|0] "" Vector__XXX
 SG_ BMU_Temperature_Age_C15 : 48|16@1+ (1,0) [0|0] "" Vector__XXX

BO_ 2284094720 BMU_TransmitTemperature_N_16_P_0: 8 Vector__XXX
 SG_ BMU_Temperature_C16_0 : 0|8@1+ (1,0) [0|0] "" Vector__XXX
 SG_ BMU_Temperature_C16_1 : 8|8@1+ (1,0) [0|0] "" Vector__XXX
 SG_ BMU_Temperature_C16_2 : 16|8@1+ (1,0) [0|0] "" Vector__XXX
 SG_ BMU_Temperature_C16_3 : 24|8@1+ (1,0) [0|0] "" Vector__XXX
 SG_ BMU_Temperature_C16_4 : 32|8@1+ (1,0) [0|0] "" Vector__XXX
 SG_ BMU_Temperature_C16_5 : 40|8@1+ (1,0) [0|0] "" Vector__XXX
 SG_ BMU_Temperature_Age_C16 : 48|16@1+ (1,0) [0|0] "" Vector__XXX

BO_ 2284094721 BMU_TransmitTemperature_N_16_P_1: 8 Vector__XXX
 SG_ BMU_Temperature_C16_6 : 0|8@1+ (1,0) [0|0] "" Vector__XXX
 SG_ BMU_Temperature_C16_7 : 8|8@1+ (1,0) [0|0] "" Vector__XXX
 SG_ BMU_Temperature_C16_8 : 16|8@1+ (1,0) [0|0] "" Vector__XXX
 SG_ BMU_Temperature_C16_9 : 24|8@1+ (1,0) [0|0] "" Vector__XXX
 SG_ BMU_Temperature_C16_10 : 32|8@1+ (1,0) [0|0] "" Vector__XXX
 SG_ BMU_Temperature_C16_11 : 40|8@1+ (1,0) [0|0] "" Vector__XXX
 SG_ BMU_Temperature_Age_C16 : 48|16@1+ (1,0) [0|0] "" Vector__XXX

BO_ 2284094722 BMU_TransmitTemperature_N_16_P_2: 8 Vector__XXX
 SG_ BMU_Temperature_C16_12 : 0|8@1+ (1,0) [0|0] "" Vector__XXX
 SG_ BMU_Temperature_C16_13 : 8|8@1+ (1,0) [0|0] "" Vector__XXX
 SG_ BMU_Temperature_C16_14 : 16|8@1+ (1,0) [0|0] "" Vector__XXX
 SG_ BMU_Temperature_C16_15 : 24|8@1+ (1,0) [0|0] "" Vector__XXX
 SG_ BMU_Temperature_Age_C16 : 48|16@1+ (1,0) [0|0] "" Vector__XXX

BO_ 2284094736 BMU_TransmitTemperature_N_17_P_0: 8 Vector__XXX
 SG_ BMU_Temperature_C17_0 : 0|8@1+ (1,0) [0|0] "" Vector__XXX
 SG_ BMU_Temperature_C17_1 : 8|8@1+ (1,0) [0|0] "" Vector__XXX
 SG_ BMU_Temperature_C17_2 : 16|8@1+ (1,0) [0|0] "" Vector__XXX
 SG_ BMU_Temperature_C17_3 : 24|8@1+ (1,0) [0|0] "" Vector__XXX
 SG_ BMU_Temperature_C17_4 : 32|8@1+ (1,0) [0|0] "" Vector__XXX
 SG_ BMU_Temperature_C17_5 : 40|8@1+ (1,0) [0|0] "" Vector__XXX
 SG_ BMU_Temperature_Age_C17 : 48|16@1+ (1,0) [0|0] "" Vector__XXX

BO_ 2284094737 BMU_TransmitTemperature_N_17_P_1: 8 Vector__XXX
 SG_ BMU_Temperature_C17_6 : 0|8@1+ (1,0) [0|0] "" Vector__XXX
 SG_ BMU_Temperature_C17_7 : 8|8@1+ (1,0) [0|0] "" Vector__XXX
 SG_ BMU_Temperature_C17_8 : 16|8@1+ (1,0) [0|0] "" Vector__XXX
 SG_ BMU_Temperature_C17_9 : 24|8@1+ (1,0) [0|0] "" Vector__XXX
 SG_ BMU_Temperature_C17_10 : 32|8@1+ (1,0) [0|0] "" Vector__XXX
 SG_ BMU_Temperature_C17_11 : 40|8@1+ (1,0) [0|0] "" Vector__XXX
 SG_ BMU_Temperature_Age_C17 : 48|16@1+ (1,0) [0|0] "" Vector__XXX

BO_ 2284094738 BMU_TransmitTemperature_N_17_P_2: 8 Vector__XXX
 SG_ BMU_Temperature_C17_12 : 0|8@1+ (1,0) [0|0] "" Vector__XXX
 SG_ BMU_Temperature_C17_13 : 8|8@1+ (1,0) [0|0] "" Vector__XXX
 SG_ BMU_Temperature_C17_14 : 16|8@1+ (1,0) [0|0] "" Vector__XXX
 SG_ BMU_Temperature_C17_15 : 24|8@1+ (1,0) [0|0] "" Vector__XXX
 SG_ BMU_Temperature_Age_C17 : 48|16@1+ (1,0) [0|0] "" Vector__XXX

BO_ 2284094752 BMU_TransmitTemperature_N_18_P_0: 8 Vector__XXX
 SG_ BMU_Temperature_C18_0 : 0|8@1+ (1,0) [0|0] "" Vector__XXX
 SG_ BMU_Temperature_C18_1 : 8|8@1+ (1,0) [0|0] "" Vector__XXX
 SG_ BMU_Temperature_C18_2 : 16|8@1+ (1,0) [0|0] "" Vector__XXX
 SG_ BMU_Temperature_C18_3 : 24|8@1+ (1,0) [0|0] "" Vector__XXX
 SG_ BMU_Temperature_C18_4 : 32|8@1+ (1,0) [0|0] "" Vector__XXX
 SG_ BMU_Temperature_C18_5 : 40|8@1+ (1,0) [0|0] "" Vector__XXX
 SG_ BMU_Temperature_Age_C18 : 48|16@1+ (1,0) [0|0] "" Vector__XXX

BO_ 2284094753 BMU_TransmitTemperature_N_18_P_1: 8 Vector__XXX
 SG_ BMU_Temperature_C18_6 : 0|8@1+ (1,0) [0|0] "" Vector__XXX
 SG_ BMU_Temperature_C18_7 : 8|8@1+ (1,0) [0|0] "" Vector__XXX
 SG_ BMU_Temperature_C18_8 : 16|8@1+ (1,0) [0|0] "" Vector__XXX
 SG_ BMU_Temperature_C18_9 : 24|8@1+ (1,0) [0|0] "" Vector__XXX
 SG_ BMU_Temperature_C18_10 : 32|8@1+ (1,0) [0|0] "" Vector__XXX
 SG_ BMU_Temperature_C18_11 : 40|8@1+ (1,0) [0|0] "" Vector__XXX
 SG_ BMU_Temperature_Age_C18 : 48|16@1+ (1,0) [0|0] "" Vector__XXX

BO_ 2284094754 BMU_TransmitTemperature_N_18_P_2: 8 Vector__XXX
 SG_ BMU_Temperature_C18_12 : 0|8@1+ (1,0) [0|0] "" Vector__XXX
 SG_ BMU_Temperature_C18_13 : 8|8@1+ (1,0) [0|0] "" Vector__XXX
 SG_ BMU_Temperature_C18_14 : 16|8@1+ (1,0) [0|0] "" Vector__XXX
 SG_ BMU_Temperature_C18_15 : 24|8@1+ (1,0) [0|0] "" Vector__XXX
 SG_ BMU_Temperature_Age_C18 : 48|16@1+ (1,0) [0|0] "" Vector__XXX

BO_ 2284094768 BMU_TransmitTemperature_N_19_P_0: 8 Vector__XXX
 SG_ BMU_Temperature_C19_0 : 0|8@1+ (1,0) [0|0] "" Vector__XXX
 SG_ BMU_Temperature_C19_1 : 8|8@1+ (1,0) [0|0] "" Vector__XXX
 SG_ BMU_Temperature_C19_2 : 16|8@1+ (1,0) [0|0] "" Vector__XXX
 SG_ BMU_Temperature_C19_3 : 24|8@1+ (1,0) [0|0] "" Vector__XXX
 SG_ BMU_Temperature_C19_4 : 32|8@1+ (1,0) [0|0] "" Vector__XXX
 SG_ BMU_Temperature_C19_5 : 40|8@1+ (1,0) [0|0] "" Vector__XXX
 SG_ BMU_Temperature_Age_C19 : 48|16@1+ (1,0) [0|0] "" Vector__XXX

BO_ 2284094769 BMU_TransmitTemperature_N_19_P_1: 8 Vector__XXX
 SG_ BMU_Temperature_C19_6 : 0|8@1+ (1,0) [0|0] "" Vector__XXX
 SG_ BMU_Temperature_C19_7 : 8|8@1+ (1,0) [0|0] "" Vector__XXX
 SG_ BMU_Temperature_C19_8 : 16|8@1+ (1,0) [0|0] "" Vector__XXX
 SG_ BMU_Temperature_C19_9 : 24|8@1+ (1,0) [0|0] "" Vector__XXX
 SG_ BMU_Temperature_C19_10 : 32|8@1+ (1,0) [0|0] "" Vector__XXX
 SG_ BMU_Temperature_C19_11 : 40|8@1+ (1,0) [0|0] "" Vector__XXX
 SG_ BMU_Temperature_Age_C19 : 48|16@1+ (1,0) [0|0] "" Vector__XXX

BO_ 2284094770 BMU_TransmitTemperature_N_19_P_2: 8 Vector__XXX
 SG_ BMU_Temperature_C19_12 : 0|8@1+ (1,0) [0|0] "" Vector__XXX
 SG_ BMU_Temperature_C19_13 : 8|8@1+ (1,0) [0|0] "" Vector__XXX
 SG_ BMU_Temperature_C19_14 : 16|8@1+ (1,0) [0|0] "" Vector__XXX
 SG_ BMU_Temperature_C19_15 : 24|8@1+ (1,0) [0|0] "" Vector__XXX
 SG_ BMU_Temperature_Age_C19 : 48|16@1+ (1,0) [0|0] "" Vector__XXX

BO_ 2284095488 BMU_TransmitBalancing_N_0: 8 Vector__XXX
 SG_ BMU_BalanceState_C0 : 0|16@1+ (1,0) [0|0] "" Vector__XXX
 SG_ BMU_DieTemp_C0 : 16|8@1+ (1,0) [0|0] "" Vector__XXX

BO_ 2284095504 BMU_TransmitBalancing_N_1: 8 Vector__XXX
 SG_ BMU_BalanceState_C1 : 0|16@1+ (1,0) [0|0] "" Vector__XXX
 SG_ BMU_DieTemp_C1 : 16|8@1+ (1,0) [0|0] "" Vector__XXX

BO_ 2284095520 BMU_TransmitBalancing_N_2: 8 Vector__XXX
 SG_ BMU_BalanceState_C2 : 0|16@1+ (1,0) [0|0] "" Vector__XXX
 SG_ BMU_DieTemp_C2 : 16|8@1+ (1,0) [0|0] "" Vector__XXX

BO_ 2284095536 BMU_TransmitBalancing_N_3: 8 Vector__XXX
 SG_ BMU_BalanceState_C3 : 0|16@1+ (1,0) [0|0] "" Vector__XXX
 SG_ BMU_DieTemp_C3 : 16|8@1+ (1,0) [0|0] "" Vector__XXX

BO_ 2284095552 BMU_TransmitBalancing_N_4: 8 Vector__XXX
 SG_ BMU_BalanceState_C4 : 0|16@1+ (1,0) [0|0] "" Vector__XXX
 SG_ BMU_DieTemp_C4 : 16|8@1+ (1,0) [0|0] "" Vector__XXX

BO_ 2284095568 BMU_TransmitBalancing_N_5: 8 Vector__XXX
 SG_ BMU_BalanceState_C5 : 0|16@1+ (1,0) [0|0] "" Vector__XXX
 SG_ BMU_DieTemp_C5 : 16|8@1+ (1,0) [0|0] "" Vector__XXX

BO_ 2284095584 BMU_TransmitBalancing_N_6: 8 Vector__XXX
 SG_ BMU_BalanceState_C6 : 0|16@1+ (1,0) [0|0] "" Vector__XXX
 SG_ BMU_DieTemp_C6 : 16|8@1+ (1,0) [0|0] "" Vector__XXX

BO_ 2284095600 BMU_TransmitBalancing_N_7: 8 Vector__XXX
 SG_ BMU_BalanceState_C7 : 0|16@1+ (1,0) [0|0] "" Vector__XXX
 SG_ BMU_DieTemp_C7 : 16|8@1+ (1,0) [0|0] "" Vector__XXX

BO_ 2284095616 BMU_TransmitBalancing_N_8: 8 Vector__XXX
 SG_ BMU_BalanceState_C8 : 0|16@1+ (1,0) [0|0] "" Vector__XXX
 SG_ BMU_DieTemp_C8 : 16|8@1+ (1,0) [0|0] "" Vector__XXX

BO_ 2284095632 BMU_TransmitBalancing_N_9: 8 Vector__XXX
 SG_ BMU_BalanceState_C9 : 0|16@1+ (1,0) [0|0] "" Vector__XXX
 SG_ BMU_DieTemp_C9 : 16|8@1+ (1,0) [0|0] "" Vector__XXX

BO_ 2284095648 BMU_TransmitBalancing_N_10: 8 Vector__XXX
 SG_ BMU_BalanceState_C10 : 0|16@1+ (1,0) [0|0] "" Vector__XXX
 SG_ BMU_DieTemp_C10 : 16|8@1+ (1,0) [0|0] "" Vector__XXX

BO_ 2284095664 BMU_TransmitBalancing_N_11: 8 Vector__XXX
 SG_ BMU_BalanceState_C11 : 0|16@1+ (1,0) [0|0] "" Vector__XXX
 SG_ BMU_DieTemp_C11 : 16|8@1+ (1,0) [0|0] "" Vector__XXX

BO_ 2284095680 BMU_TransmitBalancing_N_12: 8 Vector__XXX
 SG_ BMU_BalanceState_C12 : 0|16@1+ (1,0) [0|0] "" Vector__XXX
 SG_ BMU_DieTemp_C12 : 16|8@1+ (1,0) [0|0] "" Vector__XXX

BO_ 2284095696 BMU_TransmitBalancing_N_13: 8 Vector__XXX
 SG_ BMU_BalanceState_C13 : 0|16@1+ (1,0) [0|0] "" Vector__XXX
 SG_ BMU_DieTemp_C13 : 16|8@1+ (1,0) [0|0] "" Vector__XXX

BO_ 2284095712 BMU_TransmitBalancing_N_14: 8 Vector__XXX
 SG_ BMU_BalanceState_C14 : 0|16@1+ (1,0) [0|0] "" Vector__XXX
 SG_ BMU_DieTemp_C14 : 16|8@1+ (1,0) [0|0] "" Vector__XXX

BO_ 2284095728 BMU_TransmitBalancing_N_15: 8 Vector__XXX
 SG_ BMU_BalanceState_C15 : 0|16@1+ (1,0) [0|0] "" Vector__XXX
 SG_ BMU_DieTemp_C15 : 16|8@1+ (1,0) [0|0] "" Vector__XXX

BO_ 2284095744 BMU_TransmitBalancing_N_16: 8 Vector__XXX
 SG_ BMU_BalanceState_C16 : 0|16@1+ (1,0) [0|0] "" Vector__XXX
 SG_ BMU_DieTemp_C16 : 16|8@1+ (1,0) [0|0] "" Vector__XXX

BO_ 2284095760 BMU_TransmitBalancing_N_17: 8 Vector__XXX
 SG_ BMU_BalanceState_C17 : 0|16@1+ (1,0) [0|0] "" Vector__XXX
 SG_ BMU_DieTemp_C17 : 16|8@1+ (1,0) [0|0] "" Vector__XXX

BO_ 2284095776 BMU_TransmitBalancing_N_18: 8 Vector__XXX
 SG_ BMU_BalanceState_C18 : 0|16@1+ (1,0) [0|0] "" Vector__XXX
 SG_ BMU_DieTemp_C18 : 16|8@1+ (1,0) [0|0] "" Vector__XXX

BO_ 2284095792 BMU_TransmitBalancing_N_19: 8 Vector__XXX
 SG_ BMU_BalanceState_C19 : 0|16@1+ (1,0) [0|0] "" Vector__XXX
 SG_ BMU_DieTemp_C19 : 16|8@1+ (1,0) [0|0] "" Vector__XXX

BO_ 544 SBG_ECAN_MSG_AUTO_SLIP_CURV: 7 Vector__XXX
 SG_ SBG_ASLIP_AUTO_STATUS : 48|8@1+ (1,0) [0|255] "" Vector__XXX
 SG_ SBG_ASLIP_CURVATURE_RADIUS : 32|16@1+ (0.01,0) [0|655.35] "m" Vector__XXX
 SG_ SBG_ASLIP_ANGLE_SLIP : 16|16@1- (0.0001,0) [-3.2768|3.2767] "rad" Vector__XXX
 SG_ SBG_ASLIP_ANGLE_TRACK : 0|16@1- (0.0001,0) [-3.2768|3.2767] "rad" Vector__XXX

BO_ 521 SBG_ECAN_MSG_EVENT_TIME_E: 8 Vector__XXX
 SG_ SBG_E_TIME_OFFSET_3 : 48|16@1+ (1,0) [0|65535] "µs" Vector__XXX
 SG_ SBG_E_TIME_OFFSET_2 : 32|16@1+ (1,0) [0|65535] "µs" Vector__XXX
 SG_ SBG_E_TIME_OFFSET_1 : 16|16@1+ (1,0) [0|65535] "µs" Vector__XXX
 SG_ SBG_E_TIME_OFFSET_0 : 0|16@1+ (1,0) [0|65535] "µs" Vector__XXX

BO_ 520 SBG_ECAN_MSG_EVENT_INFO_E: 8 Vector__XXX
 SG_ SBG_E_STATUS : 32|16@1+ (1,0) [0|65535] "" Vector__XXX
 SG_ SBG_E_TIME_STAMP : 0|32@1+ (1,0) [0|4294970000] "µs" Vector__XXX

BO_ 519 SBG_ECAN_MSG_EVENT_TIME_D: 8 Vector__XXX
 SG_ SBG_D_TIME_OFFSET_3 : 48|16@1+ (1,0) [0|65535] "µs" Vector__XXX
 SG_ SBG_D_TIME_OFFSET_2 : 32|16@1+ (1,0) [0|65535] "µs" Vector__XXX
 SG_ SBG_D_TIME_OFFSET_1 : 16|16@1+ (1,0) [0|65535] "µs" Vector__XXX
 SG_ SBG_D_TIME_OFFSET_0 : 0|16@1+ (1,0) [0|65535] "µs" Vector__XXX

BO_ 518 SBG_ECAN_MSG_EVENT_INFO_D: 8 Vector__XXX
 SG_ SBG_D_STATUS : 32|16@1+ (1,0) [0|65535] "" Vector__XXX
 SG_ SBG_D_TIME_STAMP : 0|32@1+ (1,0) [0|4294970000] "µs" Vector__XXX

BO_ 517 SBG_ECAN_MSG_EVENT_TIME_C: 8 Vector__XXX
 SG_ SBG_C_TIME_OFFSET_3 : 48|16@1+ (1,0) [0|65535] "µs" Vector__XXX
 SG_ SBG_C_TIME_OFFSET_2 : 32|16@1+ (1,0) [0|65535] "µs" Vector__XXX
 SG_ SBG_C_TIME_OFFSET_1 : 16|16@1+ (1,0) [0|65535] "µs" Vector__XXX
 SG_ SBG_C_TIME_OFFSET_0 : 0|16@1+ (1,0) [0|65535] "µs" Vector__XXX

BO_ 516 SBG_ECAN_MSG_EVENT_INFO_C: 8 Vector__XXX
 SG_ SBG_C_STATUS : 32|16@1+ (1,0) [0|65535] "" Vector__XXX
 SG_ SBG_C_TIME_STAMP : 0|32@1+ (1,0) [0|4294970000] "µs" Vector__XXX

BO_ 515 SBG_ECAN_MSG_EVENT_TIME_B: 8 Vector__XXX
 SG_ SBG_B_TIME_OFFSET_3 : 48|16@1+ (1,0) [0|65535] "µs" Vector__XXX
 SG_ SBG_B_TIME_OFFSET_2 : 32|16@1+ (1,0) [0|65535] "µs" Vector__XXX
 SG_ SBG_B_TIME_OFFSET_1 : 16|16@1+ (1,0) [0|65535] "µs" Vector__XXX
 SG_ SBG_B_TIME_OFFSET_0 : 0|16@1+ (1,0) [0|65535] "µs" Vector__XXX

BO_ 514 SBG_ECAN_MSG_EVENT_INFO_B: 8 Vector__XXX
 SG_ SBG_B_STATUS : 32|16@1+ (1,0) [0|65535] "" Vector__XXX
 SG_ SBG_B_TIME_STAMP : 0|32@1+ (1,0) [0|4294970000] "µs" Vector__XXX

BO_ 513 SBG_ECAN_MSG_EVENT_TIME_A: 8 Vector__XXX
 SG_ SBG_A_TIME_OFFSET_3 : 48|16@1+ (1,0) [0|65535] "µs" Vector__XXX
 SG_ SBG_A_TIME_OFFSET_2 : 32|16@1+ (1,0) [0|65535] "µs" Vector__XXX
 SG_ SBG_A_TIME_OFFSET_1 : 16|16@1+ (1,0) [0|65535] "µs" Vector__XXX
 SG_ SBG_A_TIME_OFFSET_0 : 0|16@1+ (1,0) [0|65535] "µs" Vector__XXX

BO_ 512 SBG_ECAN_MSG_EVENT_INFO_A: 8 Vector__XXX
 SG_ SBG_A_STATUS : 32|16@1+ (1,0) [0|65535] "" Vector__XXX
 SG_ SBG_A_TIME_STAMP : 0|32@1+ (1,0) [0|4294970000] "µs" Vector__XXX

BO_ 393 SBG_ECAN_MSG_GPS2_HDT: 8 Vector__XXX
 SG_ SBG_GPS2_HDT_PITCH_ACC : 48|16@1+ (0.01,0) [0|655.35] "°" Vector__XXX
 SG_ SBG_GPS2_HDT_PITCH : 32|16@1- (0.01,0) [-327.68|327.67] "°" Vector__XXX
 SG_ SBG_GPS2_HDT_TRUE_HEADING_ACC : 16|16@1+ (0.01,0) [0|655.35] "°" Vector__XXX
 SG_ SBG_GPS2_HDT_TRUE_HEADING : 0|16@1+ (0.01,0) [0|655.35] "°" Vector__XXX

BO_ 392 SBG_ECAN_MSG_GPS2_HDT_INFO: 6 Vector__XXX
 SG_ SBG_GPS2_HDT_STATUS : 32|16@1+ (1,0) [0|65535] "" Vector__XXX
 SG_ SBG_GPS2_HDT_TIME_STAMP : 0|32@1+ (1,0) [0|4294970000] "µs" Vector__XXX

BO_ 391 SBG_ECAN_MSG_GPS2_POS_ACC: 8 Vector__XXX
 SG_ SBG_GPS2_POS_BASE_STATION_ID : 48|16@1+ (1,0) [0|65535] "" Vector__XXX
 SG_ SBG_GPS2_POS_ALTITUDE_ACC : 32|16@1+ (0.01,0) [0|655.35] "m" Vector__XXX
 SG_ SBG_GPS2_POS_LONGITUDE_ACC : 16|16@1+ (0.01,0) [0|655.35] "m" Vector__XXX
 SG_ SBG_GPS2_POS_LATITUDE_ACC : 0|16@1+ (0.01,0) [0|655.35] "m" Vector__XXX

BO_ 390 SBG_ECAN_MSG_GPS2_POS_ALT: 8 Vector__XXX
 SG_ SBG_GPS2_POS_DIFF_CORR_AGE : 56|8@1+ (1,0) [0|255] "s" Vector__XXX
 SG_ SBG_GPS2_POS_NUM_SV : 48|8@1+ (1,0) [0|255] "" Vector__XXX
 SG_ SBG_GPS2_POS_UNDULATION : 32|16@1- (0.005,0) [-163.84|163.835] "m" Vector__XXX
 SG_ SBG_GPS2_POS_ALTITUDE : 0|32@1- (0.001,0) [-2147480|2147480] "m" Vector__XXX

BO_ 389 SBG_ECAN_MSG_GPS2_POS: 8 Vector__XXX
 SG_ SBG_GPS2_POS_LONGITUDE : 32|32@1- (1E-007,0) [-214.7483648|214.7483647] "°" Vector__XXX
 SG_ SBG_GPS2_POS_LATITUDE : 0|32@1- (1E-007,0) [-214.7483648|214.7483647] "°" Vector__XXX

BO_ 388 SBG_ECAN_MSG_GPS2_POS_INFO: 8 Vector__XXX
 SG_ SBG_GPS2_POS_STATUS : 32|32@1+ (1,0) [0|4294970000] "" Vector__XXX
 SG_ SGB_GPS2_POS_TIME_STAMP : 0|32@1+ (1,0) [0|4294970000] "µs" Vector__XXX

BO_ 387 SBG_ECAN_MSG_GPS2_VEL_COURSE: 4 Vector__XXX
 SG_ SBG_GPS2_VEL_COURSE_ACC : 16|16@1+ (0.01,0) [0|655.35] "°" Vector__XXX
 SG_ SBG_GPS2_VEL_COURSE : 0|16@1+ (0.01,0) [0|655.35] "°" Vector__XXX

BO_ 386 SBG_ECAN_MSG_GPS2_VEL_ACC: 6 Vector__XXX
 SG_ SBG_GPS2_VEL_VELOCITY_ACC_D : 32|16@1- (0.01,0) [-327.68|327.67] "m.s-1" Vector__XXX
 SG_ SBG_GPS2_VEL_VELOCITY_ACC_E : 16|16@1- (0.01,0) [-327.68|327.67] "m.s-1" Vector__XXX
 SG_ SBG_GPS2_VEL_VELOCITY_ACC_N : 0|16@1- (0.01,0) [-327.68|327.67] "m.s-1" Vector__XXX

BO_ 385 SBG_ECAN_MSG_GPS2_VEL: 6 Vector__XXX
 SG_ SBG_GPS2_VEL_VELOCITY_D : 32|16@1- (0.01,0) [-327.68|327.67] "m.s-1" Vector__XXX
 SG_ SBG_GPS2_VEL_VELOCITY_E : 16|16@1- (0.01,0) [-327.68|327.67] "m.s-1" Vector__XXX
 SG_ VELOCITY_N : 0|16@1- (0.01,0) [-327.68|327.67] "m.s-1" Vector__XXX

BO_ 384 SBG_ECAN_MSG_GPS2_VEL_INFO: 8 Vector__XXX
 SG_ SBG_GPS2_VEL_STATUS : 32|32@1+ (1,0) [0|4294970000] "" Vector__XXX
 SG_ SBG_GPS2_VEL_TIME_STAMP : 0|32@1+ (1,0) [0|4294970000] "µs" Vector__XXX

BO_ 377 SBG_ECAN_MSG_GPS1_HDT: 8 Vector__XXX
 SG_ SBG_GPS1_HDT_PITCH_ACC : 48|16@1+ (0.01,0) [0|655.35] "°" Vector__XXX
 SG_ SBG_GPS1_HDT_PITCH : 32|16@1- (0.01,0) [-327.68|327.67] "°" Vector__XXX
 SG_ SBG_GPS1_HDT_TRUE_HEADING_ACC : 16|16@1+ (0.01,0) [0|655.35] "°" Vector__XXX
 SG_ SBG_GPS1_HDT_TRUE_HEADING : 0|16@1+ (0.01,0) [0|655.35] "°" Vector__XXX

BO_ 376 SBG_ECAN_MSG_GPS1_HDT_INFO: 6 Vector__XXX
 SG_ SBG_GPS1_HDT_STATUS : 32|16@1+ (1,0) [0|65535] "" Vector__XXX
 SG_ SBG_GPS1_HDT_TIME_STAMP : 0|32@1+ (1,0) [0|4294970000] "µs" Vector__XXX

BO_ 375 SBG_ECAN_MSG_GPS1_POS_ACC: 8 Vector__XXX
 SG_ SBG_GPS1_POS_BASE_STATION_ID : 48|16@1+ (1,0) [0|65535] "" Vector__XXX
 SG_ SBG_GPS1_POS_ALTITUDE_ACC : 32|16@1+ (0.01,0) [0|655.35] "m" Vector__XXX
 SG_ SBG_GPS1_POS_LONGITUDE_ACC : 16|16@1+ (0.01,0) [0|655.35] "m" Vector__XXX
 SG_ SBG_GPS1_POS_LATITUDE_ACC : 0|16@1+ (0.01,0) [0|655.35] "m" Vector__XXX

BO_ 374 SBG_ECAN_MSG_GPS1_POS_ALT: 8 Vector__XXX
 SG_ SBG_GPS1_POS_DIFF_CORR_AGE : 56|8@1+ (1,0) [0|255] "s" Vector__XXX
 SG_ SBG_GPS1_POS_NUM_SV : 48|8@1+ (1,0) [0|255] "" Vector__XXX
 SG_ SBG_GPS1_POS_UNDULATION : 32|16@1- (0.005,0) [-163.84|163.835] "m" Vector__XXX
 SG_ SBG_GPS1_POS_ALTITUDE : 0|32@1- (0.001,0) [-2147480|2147480] "m" Vector__XXX

BO_ 373 SBG_ECAN_MSG_GPS1_POS: 8 Vector__XXX
 SG_ SBG_GPS1_POS_LONGITUDE : 32|32@1- (1E-007,0) [-214.7483648|214.7483647] "°" Vector__XXX
 SG_ SBG_GPS1_POS_LATITUDE : 0|32@1- (1E-007,0) [-214.7483648|214.7483647] "°" Vector__XXX

BO_ 372 SBG_ECAN_MSG_GPS1_POS_INFO: 8 Vector__XXX
 SG_ SBG_GPS1_POS_STATUS : 32|32@1+ (1,0) [0|4294970000] "" Vector__XXX
 SG_ SBG_GPS1_POS_TIME_STAMP : 0|32@1+ (1,0) [0|4294970000] "µs" Vector__XXX

BO_ 371 SBG_ECAN_MSG_GPS1_VEL_COURSE: 4 Vector__XXX
 SG_ SBG_GPS1_VEL_COURSE_ACC : 16|16@1+ (0.01,0) [0|655.35] "°" Vector__XXX
 SG_ SBG_GPS1_VEL_COURSE : 0|16@1+ (0.01,0) [0|655.35] "°" Vector__XXX

BO_ 370 SBG_ECAN_MSG_GPS1_VEL_ACC: 6 Vector__XXX
 SG_ SBG_GPS1_VEL_VELOCITY_ACC_D : 32|16@1- (0.01,0) [-327.68|327.67] "m.s-1" Vector__XXX
 SG_ SBG_GPS1_VEL_VELOCITY_ACC_E : 16|16@1- (0.01,0) [-327.68|327.67] "m.s-1" Vector__XXX
 SG_ SBG_GPS1_VEL_VELOCITY_ACC_N : 0|16@1- (0.01,0) [-327.68|327.67] "m.s-1" Vector__XXX

BO_ 369 SBG_ECAN_MSG_GPS1_VEL: 6 Vector__XXX
 SG_ SBG_GPS1_VEL_VELOCITY_D : 32|16@1- (0.01,0) [-327.68|327.67] "m.s-1" Vector__XXX
 SG_ SBG_GPS1_VEL_VELOCITY_E : 16|16@1- (0.01,0) [-327.68|327.67] "m.s-1" Vector__XXX
 SG_ SBG_GPS1_VEL_VELOCITY_N : 0|16@1- (0.01,0) [-327.68|327.67] "m.s-1" Vector__XXX

BO_ 368 SBG_ECAN_MSG_GPS1_VEL_INFO: 8 Vector__XXX
 SG_ SBG_GPS1_VEL_STATUS : 32|32@1+ (1,0) [0|4294970000] "" Vector__XXX
 SG_ SBG_GPS1_VEL_TIME_STAMP : 0|32@1+ (1,0) [0|4294970000] "µs" Vector__XXX

BO_ 359 SBG_ECAN_MSG_DEPTH_ALTITUDE: 8 Vector__XXX
 SG_ SBG_DEPTH_DEPTH : 32|32@1- (0.001,0) [-2147480|2147480] "m" Vector__XXX
 SG_ SBG_DEPTH_PRESSURE_ABS : 0|32@1+ (0.1,0) [0|429497000] "Pa" Vector__XXX

BO_ 358 SBG_ECAN_MSG_DEPTH_INFO: 5 Vector__XXX
 SG_ SBG_DEPTH_DEPTH_STATUS : 32|8@1+ (1,0) [0|255] "" Vector__XXX
 SG_ SBG_DEPTH_TIME_STAMP : 0|32@1+ (1,0) [0|4294970000] "us" Vector__XXX

BO_ 356 SBG_ECAN_MSG_AIR_DATA_AIRSPEED: 6 Vector__XXX
 SG_ SBG_AIR_AIRSPEED : 32|16@1- (0.01,0) [-327.68|327.67] "m.s-1" Vector__XXX
 SG_ SBG_AIR_PRESSURE_DIFF : 0|32@1- (0.001,0) [-2147483.648|2147483.647] "Pa" Vector__XXX

BO_ 355 SBG_ECAN_MSG_AIR_DATA_ALTITUDE: 8 Vector__XXX
 SG_ SBG_AIR_ALTITUDE : 32|32@1- (0.001,0) [-2147483.648|2147483.647] "m" Vector__XXX
 SG_ SBG_AIR_PRESSURE_ABS : 0|32@1+ (0.001,0) [0|4294967.295] "Pa" Vector__XXX

BO_ 354 SBG_ECAN_MSG_AIR_DATA_INFO: 7 Vector__XXX
 SG_ SBG_AIR_AIR_TEMPERATURE : 40|16@1- (0.01,0) [-327.68|327.67] "°C" Vector__XXX
 SG_ SBG_AIR_AIR_DATA_STATUS : 32|8@1+ (1,0) [0|255] "" Vector__XXX
 SG_ SBG_AIR_TIME_STAMP : 0|32@1+ (1,0) [0|4294970000] "us" Vector__XXX

BO_ 353 SBG_ECAN_MSG_ODO_VEL: 2 Vector__XXX
 SG_ SBG_ODO_VELOCITY : 0|16@1- (0.01,0) [-327.68|327.67] "m.s-1" Vector__XXX

BO_ 352 SBG_ECAN_MSG_ODO_INFO: 6 Vector__XXX
 SG_ SBG_ODO_ODO_STATUS : 32|16@1+ (1,0) [0|65535] "" Vector__XXX
 SG_ SBG_ODO_TIME_STAMP : 0|32@1+ (1,0) [0|4294970000] "µs" Vector__XXX

BO_ 338 SBG_ECAN_MSG_MAG_2: 6 Vector__XXX
 SG_ SBG_MAG_2_ACCEL_Z : 32|16@1- (0.01,0) [-327.68|327.67] "m.s-2" Vector__XXX
 SG_ SBG_MAG_2_ACCEL_Y : 16|16@1- (0.01,0) [-327.68|327.67] "m.s-2" Vector__XXX
 SG_ SBG_MAG_2_ACCEL_X : 0|16@1- (0.01,0) [-327.68|327.67] "m.s-2" Vector__XXX

BO_ 337 SBG_ECAN_MSG_MAG_1: 6 Vector__XXX
 SG_ SBG_MAG_1_MAG_Z : 32|16@1- (0.001,0) [-32.768|32.767] "a.u." Vector__XXX
 SG_ SBG_MAG_1_MAG_Y : 16|16@1- (0.001,0) [-32.768|32.767] "a.u." Vector__XXX
 SG_ SBG_MAG_1_MAG_X : 0|16@1- (0.001,0) [-32.768|32.767] "a.u." Vector__XXX

BO_ 336 SBG_ECAN_MSG_MAG_0: 6 Vector__XXX
 SG_ SBG_MAG_0_STATUS : 32|16@1+ (1,0) [0|65535] "" Vector__XXX
 SG_ SBG_MAG_0_TIME_STAMP : 0|32@1+ (1,0) [0|4294970000] "µs" Vector__XXX

BO_ 333 SBG_ECAN_MSG_SHIP_MOTION_HP_2: 6 Vector__XXX
 SG_ SBG_SM_HP_2_VEL_Z : 32|16@1- (0.01,0) [-327.68|327.67] "m.s-1" Vector__XXX
 SG_ SBG_SM_HP_2_VEL_Y : 16|16@1- (0.01,0) [-327.68|327.67] "m.s-1" Vector__XXX
 SG_ SBG_SM_HP_2_VEL_X : 0|16@1- (0.01,0) [-327.68|327.67] "m.s-1" Vector__XXX

BO_ 332 SBG_ECAN_MSG_SHIP_MOTION_HP_1: 6 Vector__XXX
 SG_ SBG_SM_HP_1_ACCEL_Z : 32|16@1- (0.01,0) [-327.68|327.67] "m.s-2" Vector__XXX
 SG_ SBG_SM_HP_1_ACCEL_Y : 16|16@1- (0.01,0) [-327.68|327.67] "m.s-2" Vector__XXX
 SG_ SBG_SM_HP_1_ACCEL_X : 0|16@1- (0.01,0) [-327.68|327.67] "m.s-2" Vector__XXX

BO_ 331 SBG_ECAN_MSG_SHIP_MOTION_HP_0: 6 Vector__XXX
 SG_ SBG_SM_HP_0_HEAVE : 32|16@1- (0.001,0) [-32.768|32.767] "m" Vector__XXX
 SG_ SBG_SM_HP_0_SWAY : 16|16@1- (0.001,0) [-32.768|32.767] "m" Vector__XXX
 SG_ SBG_SM_HP_0_SURGE : 0|16@1- (0.001,0) [-32.768|32.767] "m" Vector__XXX

BO_ 330 SBG_ECAN_MSG_SHIP_MOTION_HP_INFO: 8 Vector__XXX
 SG_ SBG_SM_HP_STATUS : 48|16@1+ (1,0) [0|65535] "" Vector__XXX
 SG_ SBG_SM_HP_PERIOD : 32|16@1+ (0.01,0) [0|655.35] "s" Vector__XXX
 SG_ SBG_SM_HP_TIME_STAMP : 0|32@1+ (1,0) [0|4294970000] "µs" Vector__XXX

BO_ 329 SBG_ECAN_MSG_SHIP_MOTION_2: 6 Vector__XXX
 SG_ SBG_SM_2_VEL_Z : 32|16@1- (0.01,0) [-327.68|327.67] "m.s-1" Vector__XXX
 SG_ SBG_SM_2_VEL_Y : 16|16@1- (0.01,0) [-327.68|327.67] "m.s-1" Vector__XXX
 SG_ SBG_SM_2_VEL_X : 0|16@1- (0.01,0) [-327.68|327.67] "m.s-1" Vector__XXX

BO_ 325 SBG_ECAN_MSG_SHIP_MOTION_1: 6 Vector__XXX
 SG_ SBG_SM_1_ACCEL_Z : 32|16@1- (0.01,0) [-327.68|327.67] "m.s-2" Vector__XXX
 SG_ SBG_SM_1_ACCEL_Y : 16|16@1- (0.01,0) [-327.68|327.67] "m.s-2" Vector__XXX
 SG_ SBG_SM_1_ACCEL_X : 0|16@1- (0.01,0) [-327.68|327.67] "m.s-2" Vector__XXX

BO_ 321 SBG_ECAN_MSG_SHIP_MOTION_0: 6 Vector__XXX
 SG_ SBG_SM_0_HEAVE : 32|16@1- (0.001,0) [-32.768|32.767] "m" Vector__XXX
 SG_ SBG_SM_0_SWAY : 16|16@1- (0.001,0) [-32.768|32.767] "m" Vector__XXX
 SG_ SBG_SM_0_SURGE : 0|16@1- (0.001,0) [-32.768|32.767] "m" Vector__XXX

BO_ 320 SBG_ECAN_MSG_SHIP_MOTION_INFO: 8 Vector__XXX
 SG_ SBG_SM_STATUS : 48|16@1+ (1,0) [0|65535] "" Vector__XXX
 SG_ SBG_SM_PERIOD : 32|16@1+ (0.01,0) [0|655.35] "s" Vector__XXX
 SG_ SBG_SM_TIME_STAMP : 0|32@1+ (1,0) [0|4294970000] "µs" Vector__XXX

BO_ 313 SBG_ECAN_MSG_EKF_VEL_BODY: 6 Vector__XXX
 SG_ SBG_EKF_BODY_VELOCITY_Z : 32|16@1- (0.01,0) [-327.68|327.67] "m.s-1" Vector__XXX
 SG_ SBG_EKF_BODY_VELOCITY_Y : 16|16@1- (0.01,0) [-327.68|327.67] "m.s-1" Vector__XXX
 SG_ SBG_EKF_BODY_VELOCITY_X : 0|16@1- (0.01,0) [-327.68|327.67] "m.s-1" Vector__XXX

BO_ 312 SBG_ECAN_MSG_EKF_VEL_NED_ACC: 6 Vector__XXX
 SG_ SBG_EKF_NED_VELOCITY_ACC_D : 32|16@1- (0.01,0) [-327.68|327.67] "m.s-1" Vector__XXX
 SG_ SBG_EKF_NED_VELOCITY_ACC_E : 16|16@1- (0.01,0) [-327.68|327.67] "m.s-1" Vector__XXX
 SG_ SBG_EKF_NED_VELOCITY_ACC_N : 0|16@1- (0.01,0) [-327.68|327.67] "m.s-1" Vector__XXX

BO_ 311 SBG_ECAN_MSG_EKF_VEL_NED: 6 Vector__XXX
 SG_ SBG_EKF_NED_VELOCITY_D : 32|16@1- (0.01,0) [-327.68|327.67] "m.s-1" Vector__XXX
 SG_ SBG_EKF_NED_VELOCITY_E : 16|16@1- (0.01,0) [-327.68|327.67] "m.s-1" Vector__XXX
 SG_ SBG_EKF_NED_VELOCITY_N : 0|16@1- (0.01,0) [-327.68|327.67] "m.s-1" Vector__XXX

BO_ 310 SBG_ECAN_MSG_EKF_POS_ACC: 6 Vector__XXX
 SG_ SBG_EKF_POS_ALTITUDE_ACC : 32|16@1+ (0.01,0) [0|655.35] "m" Vector__XXX
 SG_ SBG_EKF_POS_LONGITUDE_ACC : 16|16@1+ (0.01,0) [0|655.35] "m" Vector__XXX
 SG_ SBG_EKF_POS_LATITUDE_ACC : 0|16@1+ (0.01,0) [0|655.35] "m" Vector__XXX

BO_ 309 SBG_ECAN_MSG_EKF_ALTITUDE: 6 Vector__XXX
 SG_ SBG_EKF_UNDULATION : 32|16@1- (0.005,0) [-163.84|163.835] "m" Vector__XXX
 SG_ SBG_EKF_ALTITUDE : 0|32@1- (0.001,0) [-2147480|2147480] "m" Vector__XXX

BO_ 308 SBG_ECAN_MSG_EKF_POS: 8 Vector__XXX
 SG_ SBG_EKF_POS_LONGITUDE : 32|32@1- (1E-007,0) [-214.7483648|214.7483647] "°" Vector__XXX
 SG_ SBG_EKF_POS_LATITUDE : 0|32@1- (1E-007,0) [-214.7483648|214.7483647] "°" Vector__XXX

BO_ 307 SBG_ECAN_MSG_EKF_ORIENTATION_ACC: 6 Vector__XXX
 SG_ SBG_EKF_ORIE_YAW_ACC : 32|16@1+ (0.0001,0) [0|6.5535] "rad" Vector__XXX
 SG_ SBG_EKF_ORIE_PITCH_ACC : 16|16@1+ (0.0001,0) [0|6.5535] "rad" Vector__XXX
 SG_ SBG_EKF_ORIE_ROLL_ACC : 0|16@1+ (0.0001,0) [0|6.5535] "rad" Vector__XXX

BO_ 306 SBG_ECAN_MSG_EKF_EULER: 6 Vector__XXX
 SG_ SBG_EKF_EULER_YAW : 32|16@1- (0.0001,0) [-3.2768|3.2767] "rad" Vector__XXX
 SG_ SBG_EKF_EULER_PITCH : 16|16@1- (0.0001,0) [-3.2768|3.2767] "rad" Vector__XXX
 SG_ SBG_EKF_EULER_ROLL : 0|16@1- (0.0001,0) [-3.2768|3.2767] "rad" Vector__XXX

BO_ 305 SBG_ECAN_MSG_EKF_QUAT: 8 Vector__XXX
 SG_ Q3 : 48|16@1- (3.05185094759972E-005,0) [-1|1] "" Vector__XXX
 SG_ Q2 : 32|16@1- (3.05185094759972E-005,0) [-1|1] "" Vector__XXX
 SG_ Q1 : 16|16@1- (3.05185094759972E-005,0) [-1|1] "" Vector__XXX
 SG_ Q0 : 0|16@1- (3.05185094759972E-005,0) [-1|1] "" Vector__XXX

BO_ 304 SBG_ECAN_MSG_EKF_INFO: 4 Vector__XXX
 SG_ SBG_EFK_TIME_STAMP : 0|32@1+ (1,0) [0|4294970000] "µs" Vector__XXX

BO_ 292 SBG_ECAN_MSG_IMU_DELTA_ANGLE: 6 Vector__XXX
 SG_ SBG_DELTA_ANGLE_Z : 32|16@1- (0.001,0) [-32.768|32.767] "rad.s-1" Vector__XXX
 SG_ SBG_DELTA_ANGLE_Y : 16|16@1- (0.001,0) [-32.768|32.767] "rad.s-1" Vector__XXX
 SG_ SBG_DELTA_ANGLE_X : 0|16@1- (0.001,0) [-32.768|32.767] "rad.s-1" Vector__XXX

BO_ 291 SBG_ECAN_MSG_IMU_DELTA_VEL: 6 Vector__XXX
 SG_ SBG_DELTA_VEL_Z : 32|16@1- (0.01,0) [-327.68|327.67] "m.s-2" Vector__XXX
 SG_ SBG_DELTA_VEL_Y : 16|16@1- (0.01,0) [-327.68|327.67] "m.s-2" Vector__XXX
 SG_ SBG_DELTA_VEL_X : 0|16@1- (0.01,0) [-327.68|327.67] "m.s-2" Vector__XXX

BO_ 290 SBG_ECAN_MSG_IMU_GYRO: 6 Vector__XXX
 SG_ SBG_IMU_GYRO_Z : 32|16@1- (0.001,0) [-32.768|32.767] "rad.s-1" Vector__XXX
 SG_ SBG_IMU_GYRO_Y : 16|16@1- (0.001,0) [-32.768|32.767] "rad.s-1" Vector__XXX
 SG_ SBG_IMU_GYRO_X : 0|16@1- (0.001,0) [-32.768|32.767] "rad.s-1" Vector__XXX

BO_ 289 SBG_ECAN_MSG_IMU_ACCEL: 6 Vector__XXX
 SG_ SBG_IMU_ACCEL_Z : 32|16@1- (0.01,0) [-327.68|327.67] "m.s-2" Vector__XXX
 SG_ SBG_IMU_ACCEL_Y : 16|16@1- (0.01,0) [-327.68|327.67] "m.s-2" Vector__XXX
 SG_ SBG_IMU_ACCEL_X : 0|16@1- (0.01,0) [-327.68|327.67] "m.s-2" Vector__XXX

BO_ 288 SBG_ECAN_MSG_IMU_INFO: 8 Vector__XXX
 SG_ SBG_IMU_TEMPERATURE : 48|16@1- (0.01,0) [-327.68|327.67] "°C" Vector__XXX
 SG_ SBG_IMU_STATUS : 32|16@1+ (1,0) [0|65535] "" Vector__XXX
 SG_ SBG_IMU_TIME_STAMP : 0|32@1+ (1,0) [0|4294970000] "µs" Vector__XXX

BO_ 273 SBG_ECAN_MSG_UTC_1: 8 Vector__XXX
 SG_ MICRO_SEC : 48|16@1+ (100,0) [0|6553500] "us" Vector__XXX
 SG_ SEC : 40|8@1+ (1,0) [0|255] "s" Vector__XXX
 SG_ MIN : 32|8@1+ (1,0) [0|255] "min" Vector__XXX
 SG_ HOUR : 24|8@1+ (1,0) [0|255] "h" Vector__XXX
 SG_ DAY : 16|8@1+ (1,0) [0|255] "d" Vector__XXX
 SG_ MONTH : 8|8@1+ (1,0) [0|255] "month" Vector__XXX
 SG_ YEAR : 0|8@1+ (1,2000) [2000|2255] "year" Vector__XXX

BO_ 272 SBG_ECAN_MSG_UTC_0: 8 Vector__XXX
 SG_ SBG_UTC_0_GPS_TOW : 32|32@1+ (1,0) [0|4294970000] "ms" Vector__XXX
 SG_ SBG_UTC_0_TIME_STAMP : 0|32@1+ (1,0) [0|4294970000] "µs" Vector__XXX

BO_ 258 SBG_ECAN_MSG_STATUS_03: 6 Vector__XXX
 SG_ SBG_MSG_03_HEAVE_STATUS : 32|16@1+ (1,0) [0|65535] "" Vector__XXX
 SG_ SBG_MSG_03_SOLUTION : 0|32@1+ (1,0) [0|4294970000] "" Vector__XXX

BO_ 257 SBG_ECAN_MSG_STATUS_02: 8 Vector__XXX
 SG_ SBG_MSG_02_AIDING : 32|32@1+ (1,0) [0|4294970000] "" Vector__XXX
 SG_ SBG_MSG_02_COM : 0|32@1+ (1,0) [0|4294970000] "" Vector__XXX

BO_ 256 SBG_ECAN_MSG_STATUS_01: 8 Vector__XXX
 SG_ SBG_MSG_01_CLOCK : 48|16@1+ (1,0) [0|65535] "" Vector__XXX
 SG_ SBG_MSG_01_GENERAL : 32|16@1+ (1,0) [0|65535] "" Vector__XXX
 SG_ SBG_MSG_01_TIME_STAMP : 0|32@1+ (1,0) [0|4294970000] "µs" Vector__XXX

BO_ 2165338473 Sevcon_1_HC1: 8 Vector__XXX
 SG_ Sevcon_1_TorqueDemand : 0|16@1- (1,0) [0|0] "Nm" Vector__XXX
 SG_ Sevcon_1_ControlWord : 16|16@1+ (1,0) [0|0] "" Vector__XXX
 SG_ Sevcon_1_TorqueLimit : 32|16@1- (1,0) [0|0] "Nm" Vector__XXX

BO_ 2165404009 Sevcon_1_HC2: 8 Vector__XXX
 SG_ Sevcon_1_RegenTorqueLimit : 0|16@1- (1,0) [0|0] "Nm" Vector__XXX
 SG_ Sevcon_1_FwdSpeedLimit : 16|16@1+ (1,0) [0|0] "RPM" Vector__XXX
 SG_ Sevcon_1_RevSpeedLimit : 32|16@1- (1,0) [0|0] "RPM" Vector__XXX

BO_ 2165469545 Sevcon_1_HC3: 8 Vector__XXX
 SG_ Sevcon_1_DischargeLimit : 0|16@1- (1,0) [0|0] "A" Vector__XXX
 SG_ Sevcon_1_ChargeLimit : 16|16@1+ (1,0) [0|0] "A" Vector__XXX
 SG_ Sevcon_1_TargetCapVoltage : 32|16@1- (1,0) [0|0] "V" Vector__XXX

BO_ 2165338729 Sevcon_2_HC1: 8 Vector__XXX
 SG_ Sevcon_2_TorqueDemand : 0|16@1- (1,0) [0|0] "Nm" Vector__XXX
 SG_ Sevcon_2_ControlWord : 16|16@1+ (1,0) [0|0] "" Vector__XXX
 SG_ Sevcon_2_TorqueLimit : 32|16@1- (1,0) [0|0] "Nm" Vector__XXX

BO_ 2165404265 Sevcon_2_HC2: 8 Vector__XXX
 SG_ Sevcon_2_RegenTorqueLimit : 0|16@1- (1,0) [0|0] "Nm" Vector__XXX
 SG_ Sevcon_2_FwdSpeedLimit : 16|16@1+ (1,0) [0|0] "RPM" Vector__XXX
 SG_ Sevcon_2_RevSpeedLimit : 32|16@1- (1,0) [0|0] "RPM" Vector__XXX

BO_ 2165469801 Sevcon_2_HC3: 8 Vector__XXX
 SG_ Sevcon_2_DischargeLimit : 0|16@1- (1,0) [0|0] "A" Vector__XXX
 SG_ Sevcon_2_ChargeLimit : 16|16@1+ (1,0) [0|0] "A" Vector__XXX
 SG_ Sevcon_2_TargetCapVoltage : 32|16@1- (1,0) [0|0] "V" Vector__XXX

BO_ 2568552305 Sevcon_1_HS1: 8 Vector__XXX
 SG_ Sevcon_1_OutputTorque : 0|16@1- (0.0625,0) [0|0] "Nm" Vector__XXX
 SG_ Sevcon_1_Speed : 16|16@1- (1,0) [0|0] "RPM" Vector__XXX
 SG_ Sevcon_1_BatteryCurrent : 32|16@1- (1,0) [0|0] "A" Vector__XXX

BO_ 2568617841 Sevcon_1_HS2: 8 Vector__XXX
 SG_ Sevcon_1_AvailFwdTorque : 0|16@1- (0.0625,0) [0|0] "Nm" Vector__XXX
 SG_ Sevcon_1_AvailRevTorque : 16|16@1- (0.0625,0) [0|0] "Nm" Vector__XXX
 SG_ Sevcon_1_StatusWord : 32|16@1+ (1,0) [0|65535] "" Vector__XXX

BO_ 2568683377 Sevcon_1_HS3: 8 Vector__XXX
 SG_ Sevcon_1_HeatSinkTemp : 0|16@1- (1,0) [0|0] "degC" Vector__XXX
 SG_ Sevcon_1_RemainingTemp : 16|16@1- (1,0) [0|0] "degC" Vector__XXX
 SG_ Sevcon_1_CapVoltage : 32|16@1- (0.0625,0) [0|0] "V" Vector__XXX

BO_ 2568748913 Sevcon_1_HS4: 8 Vector__XXX
 SG_ Sevcon_1_FaultCode : 0|16@1+ (1,0) [0|0] "" Vector__XXX
 SG_ Sevcon_1_DebugBytes : 16|32@1+ (1,0) [0|0] "" Vector__XXX

BO_ 2568814449 Sevcon_1_HS5: 8 Vector__XXX
 SG_ Sevcon_1_EncoderAngle : 0|32@1- (1.525E-005,0) [0|0] "" Vector__XXX

BO_ 2568552306 Sevcon_2_HS1: 8 Vector__XXX
 SG_ Sevcon_2_OutputTorque : 0|16@1- (0.0625,0) [0|0] "Nm" Vector__XXX
 SG_ Sevcon_2_Speed : 16|16@1- (1,0) [0|0] "RPM" Vector__XXX
 SG_ Sevcon_2_BatteryCurrent : 32|16@1- (1,0) [0|0] "A" Vector__XXX

BO_ 2568617842 Sevcon_2_HS2: 8 Vector__XXX
 SG_ Sevcon_2_AvailFwdTorque : 0|16@1- (0.0625,0) [0|0] "Nm" Vector__XXX
 SG_ Sevcon_2_AvailRevTorque : 16|16@1- (0.0625,0) [0|0] "Nm" Vector__XXX
 SG_ Sevcon_2_StatusWord : 32|16@1+ (1,0) [0|65535] "" Vector__XXX

BO_ 2568683378 Sevcon_2_HS3: 8 Vector__XXX
 SG_ Sevcon_2_HeatSinkTemp : 0|16@1- (1,0) [0|0] "degC" Vector__XXX
 SG_ Sevcon_2_RemainingTemp : 16|16@1- (1,0) [0|0] "degC" Vector__XXX
 SG_ Sevcon_2_CapVoltage : 32|16@1- (0.0625,0) [0|0] "V" Vector__XXX

BO_ 2568748914 Sevcon_2_HS4: 8 Vector__XXX
 SG_ Sevcon_2_FaultCode : 0|16@1+ (1,0) [0|0] "" Vector__XXX
 SG_ Sevcon_2_DebugBytes : 16|32@1+ (1,0) [0|0] "" Vector__XXX

BO_ 2568814450 Sevcon_2_HS5: 8 Vector__XXX
 SG_ Sevcon_2_EncoderAngle : 0|32@1+ (1.525E-005,0) [0|0] "" Vector__XXX

BO_ 2569600881 Sevcon_1_HD1: 8 Vector__XXX
 SG_ Sevcon_1_IdActual : 0|16@1- (0.0625,0) [0|0] "A" Vector__XXX
 SG_ Sevcon_1_IqActual : 16|16@1- (0.0625,0) [0|0] "A" Vector__XXX
 SG_ Sevcon_1_IdRef : 32|16@1- (0.0625,0) [0|0] "A" Vector__XXX
 SG_ Sevcon_1_IqRef : 48|16@1- (0.0625,0) [0|0] "A" Vector__XXX

BO_ 2569666417 Sevcon_1_HD2: 8 Vector__XXX
 SG_ Sevcon_1_Ud : 0|16@1- (0.0625,0) [0|0] "V" Vector__XXX
 SG_ Sevcon_1_Uq : 16|16@1- (0.0625,0) [0|0] "V" Vector__XXX
 SG_ Sevcon_1_ModIndex : 32|16@1+ (0.0030517578125,0) [0|0] "%" Vector__XXX
 SG_ Sevcon_1_TargetTorque : 48|16@1- (0.0625,0) [0|0] "Nm" Vector__XXX

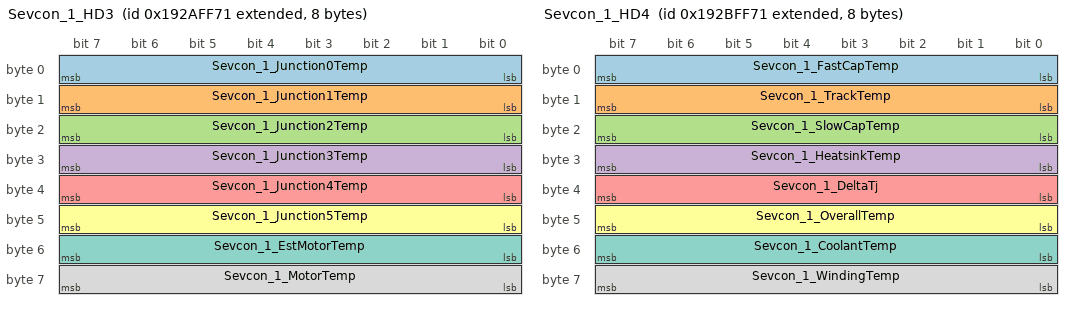
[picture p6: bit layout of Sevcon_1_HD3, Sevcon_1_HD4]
BO_ 2569731953 Sevcon_1_HD3: 8 Vector__XXX
 SG_ Sevcon_1_Junction0Temp : 0|8@1+ (1,0) [0|0] "degC" Vector__XXX
 SG_ Sevcon_1_Junction1Temp : 8|8@1+ (1,0) [0|0] "degC" Vector__XXX
 SG_ Sevcon_1_Junction2Temp : 16|8@1+ (1,0) [0|0] "degC" Vector__XXX
 SG_ Sevcon_1_Junction3Temp : 24|8@1+ (1,0) [0|0] "degC" Vector__XXX
 SG_ Sevcon_1_Junction4Temp : 32|8@1+ (1,0) [0|0] "degC" Vector__XXX
 SG_ Sevcon_1_Junction5Temp : 40|8@1+ (1,0) [0|0] "degC" Vector__XXX
 SG_ Sevcon_1_EstMotorTemp : 48|8@1+ (1,0) [0|0] "degC" Vector__XXX
 SG_ Sevcon_1_MotorTemp : 56|8@1+ (1,0) [0|0] "degC" Vector__XXX

BO_ 2569797489 Sevcon_1_HD4: 8 Vector__XXX
 SG_ Sevcon_1_FastCapTemp : 0|8@1+ (1,0) [0|0] "" Vector__XXX
 SG_ Sevcon_1_TrackTemp : 8|8@1+ (1,0) [0|0] "degC" Vector__XXX
 SG_ Sevcon_1_SlowCapTemp : 16|8@1+ (1,0) [0|0] "degC" Vector__XXX
 SG_ Sevcon_1_HeatsinkTemp : 24|8@1+ (1,0) [0|0] "degC" Vector__XXX
 SG_ Sevcon_1_DeltaTj : 32|8@1+ (1,0) [0|0] "degC" Vector__XXX
 SG_ Sevcon_1_OverallTemp : 40|8@1+ (1,0) [0|0] "degC" Vector__XXX
 SG_ Sevcon_1_CoolantTemp : 48|8@1+ (1,0) [0|0] "degC" Vector__XXX
 SG_ Sevcon_1_WindingTemp : 56|8@1+ (1,0) [0|0] "degC" Vector__XXX

BO_ 2569863025 Sevcon_1_HD5: 8 Vector__XXX
 SG_ Sevcon_1_MaxFlux : 0|16@1- (1,0) [0|0] "A" Vector__XXX
 SG_ Sevcon_1_IvLim : 16|16@1- (1,0) [0|0] "A" Vector__XXX
 SG_ Sevcon_1_IqMax : 32|16@1- (1,0) [0|0] "A" Vector__XXX
 SG_ Sevcon_1_Ls : 48|16@1+ (0.05960464498,0) [0|0] "uH" Vector__XXX

BO_ 2569600882 Sevcon_2_HD1: 8 Vector__XXX
 SG_ Sevcon_2_IdActual : 0|16@1- (0.0625,0) [0|0] "A" Vector__XXX
 SG_ Sevcon_2_IqActual : 16|16@1- (0.0625,0) [0|0] "A" Vector__XXX
 SG_ Sevcon_2_IdRef : 32|16@1- (0.0625,0) [0|0] "A" Vector__XXX
 SG_ Sevcon_2_IqRef : 48|16@1- (0.0625,0) [0|0] "A" Vector__XXX

BO_ 2569666418 Sevcon_2_HD2: 8 Vector__XXX
 SG_ Sevcon_2_Ud : 0|16@1- (0.0625,0) [0|0] "V" Vector__XXX
 SG_ Sevcon_2_Uq : 16|16@1- (0.0625,0) [0|0] "V" Vector__XXX
 SG_ Sevcon_2_ModIndex : 32|16@1+ (0.0030517578125,0) [0|0] "%" Vector__XXX
 SG_ Sevcon_2_TargetTorque : 48|16@1- (0.0625,0) [0|0] "Nm" Vector__XXX

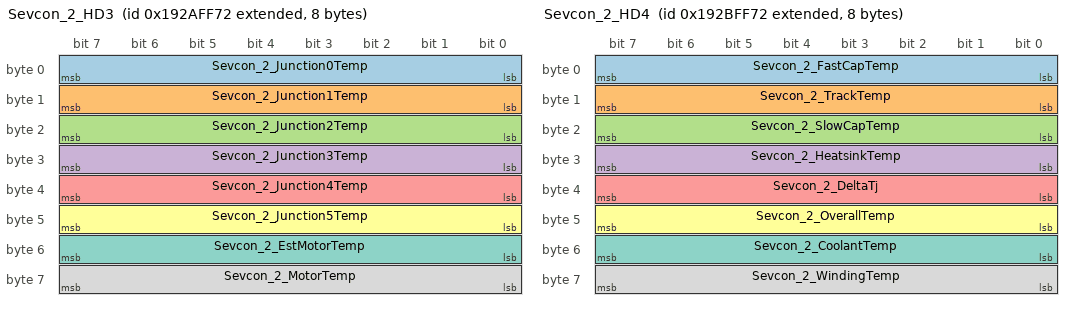
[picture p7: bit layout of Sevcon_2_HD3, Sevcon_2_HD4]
BO_ 2569731954 Sevcon_2_HD3: 8 Vector__XXX
 SG_ Sevcon_2_Junction0Temp : 0|8@1+ (1,0) [0|0] "degC" Vector__XXX
 SG_ Sevcon_2_Junction1Temp : 8|8@1+ (1,0) [0|0] "degC" Vector__XXX
 SG_ Sevcon_2_Junction2Temp : 16|8@1+ (1,0) [0|0] "degC" Vector__XXX
 SG_ Sevcon_2_Junction3Temp : 24|8@1+ (1,0) [0|0] "degC" Vector__XXX
 SG_ Sevcon_2_Junction4Temp : 32|8@1+ (1,0) [0|0] "degC" Vector__XXX
 SG_ Sevcon_2_Junction5Temp : 40|8@1+ (1,0) [0|0] "degC" Vector__XXX
 SG_ Sevcon_2_EstMotorTemp : 48|8@1+ (1,0) [0|0] "degC" Vector__XXX
 SG_ Sevcon_2_MotorTemp : 56|8@1+ (1,0) [0|0] "degC" Vector__XXX

BO_ 2569797490 Sevcon_2_HD4: 8 Vector__XXX
 SG_ Sevcon_2_FastCapTemp : 0|8@1+ (1,0) [0|0] "" Vector__XXX
 SG_ Sevcon_2_TrackTemp : 8|8@1+ (1,0) [0|0] "degC" Vector__XXX
 SG_ Sevcon_2_SlowCapTemp : 16|8@1+ (1,0) [0|0] "degC" Vector__XXX
 SG_ Sevcon_2_HeatsinkTemp : 24|8@1+ (1,0) [0|0] "degC" Vector__XXX
 SG_ Sevcon_2_DeltaTj : 32|8@1+ (1,0) [0|0] "degC" Vector__XXX
 SG_ Sevcon_2_OverallTemp : 40|8@1+ (1,0) [0|0] "degC" Vector__XXX
 SG_ Sevcon_2_CoolantTemp : 48|8@1+ (1,0) [0|0] "degC" Vector__XXX
 SG_ Sevcon_2_WindingTemp : 56|8@1+ (1,0) [0|0] "degC" Vector__XXX

BO_ 2569863026 Sevcon_2_HD5: 8 Vector__XXX
 SG_ Sevcon_2_MaxFlux : 0|16@1- (1,0) [0|0] "A" Vector__XXX
 SG_ Sevcon_2_IvLim : 16|16@1- (1,0) [0|0] "A" Vector__XXX
 SG_ Sevcon_2_IqMax : 32|16@1- (1,0) [0|0] "A" Vector__XXX
 SG_ Sevcon_2_Ls : 48|16@1+ (0.05960464498,0) [0|0] "uH" Vector__XXX

BA_DEF_  "BusType" STRING ;
BA_DEF_DEF_  "BusType" "CAN";

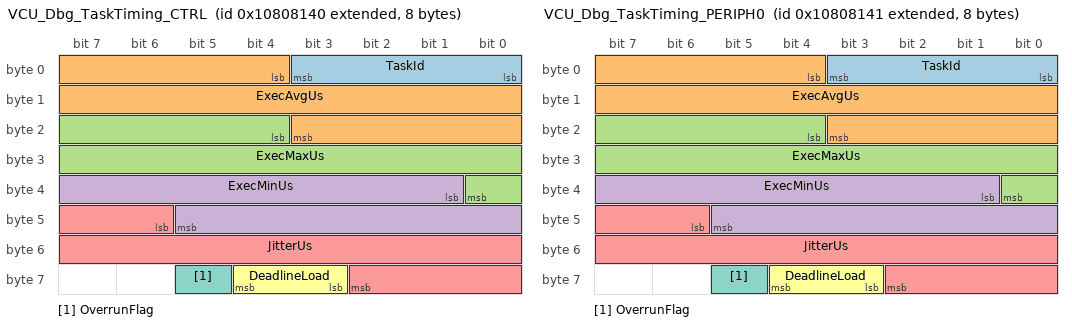
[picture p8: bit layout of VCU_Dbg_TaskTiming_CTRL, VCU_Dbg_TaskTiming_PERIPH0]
BO_ 2424340800 VCU_Dbg_TaskTiming_CTRL: 8 VCU
 SG_ TaskId : 0|4@1+ (1,0) [0|0] "" Vector__XXX
 SG_ ExecAvgUs : 4|16@1+ (1,0) [0|0] "" Vector__XXX
 SG_ ExecMaxUs : 20|13@1+ (1,0) [0|0] "" Vector__XXX
 SG_ ExecMinUs : 33|13@1+ (1,0) [0|0] "" Vector__XXX
 SG_ JitterUs : 46|13@1+ (1,0) [0|0] "" Vector__XXX
 SG_ DeadlineLoad : 59|2@1+ (1,0) [0|0] "" Vector__XXX
 SG_ OverrunFlag : 61|1@1+ (1,0) [0|0] "" Vector__XXX

BO_ 2424340801 VCU_Dbg_TaskTiming_PERIPH0: 8 VCU
 SG_ TaskId : 0|4@1+ (1,0) [0|0] "" Vector__XXX
 SG_ ExecAvgUs : 4|16@1+ (1,0) [0|0] "" Vector__XXX
 SG_ ExecMaxUs : 20|13@1+ (1,0) [0|0] "" Vector__XXX
 SG_ ExecMinUs : 33|13@1+ (1,0) [0|0] "" Vector__XXX
 SG_ JitterUs : 46|13@1+ (1,0) [0|0] "" Vector__XXX
 SG_ DeadlineLoad : 59|2@1+ (1,0) [0|0] "" Vector__XXX
 SG_ OverrunFlag : 61|1@1+ (1,0) [0|0] "" Vector__XXX

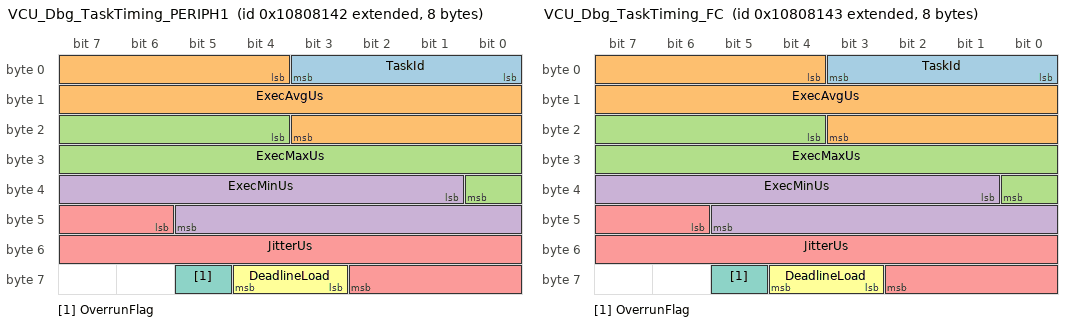
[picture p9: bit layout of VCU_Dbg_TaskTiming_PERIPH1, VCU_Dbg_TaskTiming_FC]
BO_ 2424340802 VCU_Dbg_TaskTiming_PERIPH1: 8 VCU
 SG_ TaskId : 0|4@1+ (1,0) [0|0] "" Vector__XXX
 SG_ ExecAvgUs : 4|16@1+ (1,0) [0|0] "" Vector__XXX
 SG_ ExecMaxUs : 20|13@1+ (1,0) [0|0] "" Vector__XXX
 SG_ ExecMinUs : 33|13@1+ (1,0) [0|0] "" Vector__XXX
 SG_ JitterUs : 46|13@1+ (1,0) [0|0] "" Vector__XXX
 SG_ DeadlineLoad : 59|2@1+ (1,0) [0|0] "" Vector__XXX
 SG_ OverrunFlag : 61|1@1+ (1,0) [0|0] "" Vector__XXX

BO_ 2424340803 VCU_Dbg_TaskTiming_FC: 8 VCU
 SG_ TaskId : 0|4@1+ (1,0) [0|0] "" Vector__XXX
 SG_ ExecAvgUs : 4|16@1+ (1,0) [0|0] "" Vector__XXX
 SG_ ExecMaxUs : 20|13@1+ (1,0) [0|0] "" Vector__XXX
 SG_ ExecMinUs : 33|13@1+ (1,0) [0|0] "" Vector__XXX
 SG_ JitterUs : 46|13@1+ (1,0) [0|0] "" Vector__XXX
 SG_ DeadlineLoad : 59|2@1+ (1,0) [0|0] "" Vector__XXX
 SG_ OverrunFlag : 61|1@1+ (1,0) [0|0] "" Vector__XXX

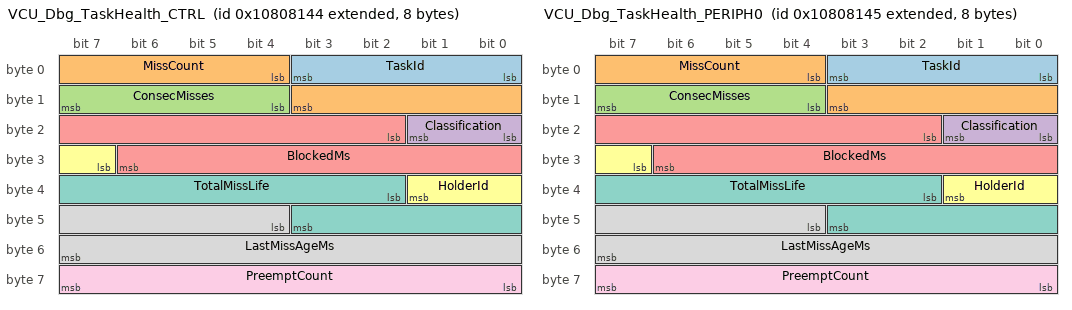
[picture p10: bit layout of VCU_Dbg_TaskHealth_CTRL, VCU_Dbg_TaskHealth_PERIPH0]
BO_ 2424340804 VCU_Dbg_TaskHealth_CTRL: 8 VCU
 SG_ TaskId : 0|4@1+ (1,0) [0|0] "" Vector__XXX
 SG_ MissCount : 4|8@1+ (1,0) [0|0] "" Vector__XXX
 SG_ ConsecMisses : 12|4@1+ (1,0) [0|0] "" Vector__XXX
 SG_ Classification : 16|2@1+ (1,0) [0|0] "" Vector__XXX
 SG_ BlockedMs : 18|13@1+ (1,0) [0|0] "" Vector__XXX
 SG_ HolderId : 31|3@1+ (1,0) [0|0] "" Vector__XXX
 SG_ TotalMissLife : 34|10@1+ (1,0) [0|0] "" Vector__XXX
 SG_ LastMissAgeMs : 44|12@1+ (1,0) [0|0] "" Vector__XXX
 SG_ PreemptCount : 56|8@1+ (1,0) [0|0] "" Vector__XXX

BO_ 2424340805 VCU_Dbg_TaskHealth_PERIPH0: 8 VCU
 SG_ TaskId : 0|4@1+ (1,0) [0|0] "" Vector__XXX
 SG_ MissCount : 4|8@1+ (1,0) [0|0] "" Vector__XXX
 SG_ ConsecMisses : 12|4@1+ (1,0) [0|0] "" Vector__XXX
 SG_ Classification : 16|2@1+ (1,0) [0|0] "" Vector__XXX
 SG_ BlockedMs : 18|13@1+ (1,0) [0|0] "" Vector__XXX
 SG_ HolderId : 31|3@1+ (1,0) [0|0] "" Vector__XXX
 SG_ TotalMissLife : 34|10@1+ (1,0) [0|0] "" Vector__XXX
 SG_ LastMissAgeMs : 44|12@1+ (1,0) [0|0] "" Vector__XXX
 SG_ PreemptCount : 56|8@1+ (1,0) [0|0] "" Vector__XXX

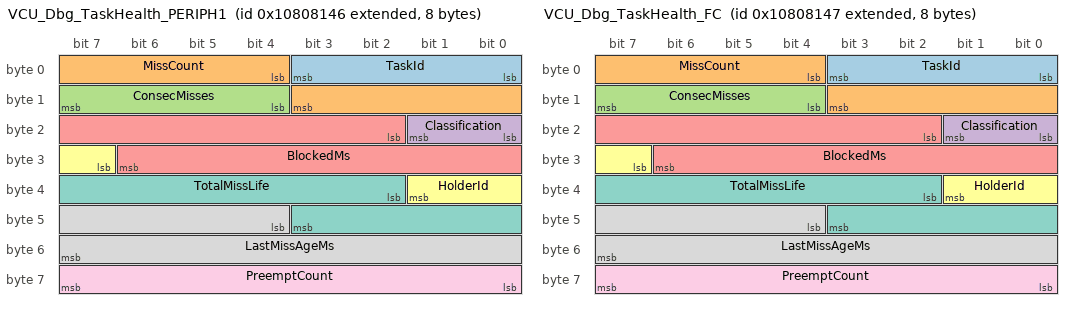
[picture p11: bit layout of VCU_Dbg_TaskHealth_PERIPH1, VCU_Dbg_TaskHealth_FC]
BO_ 2424340806 VCU_Dbg_TaskHealth_PERIPH1: 8 VCU
 SG_ TaskId : 0|4@1+ (1,0) [0|0] "" Vector__XXX
 SG_ MissCount : 4|8@1+ (1,0) [0|0] "" Vector__XXX
 SG_ ConsecMisses : 12|4@1+ (1,0) [0|0] "" Vector__XXX
 SG_ Classification : 16|2@1+ (1,0) [0|0] "" Vector__XXX
 SG_ BlockedMs : 18|13@1+ (1,0) [0|0] "" Vector__XXX
 SG_ HolderId : 31|3@1+ (1,0) [0|0] "" Vector__XXX
 SG_ TotalMissLife : 34|10@1+ (1,0) [0|0] "" Vector__XXX
 SG_ LastMissAgeMs : 44|12@1+ (1,0) [0|0] "" Vector__XXX
 SG_ PreemptCount : 56|8@1+ (1,0) [0|0] "" Vector__XXX

BO_ 2424340807 VCU_Dbg_TaskHealth_FC: 8 VCU
 SG_ TaskId : 0|4@1+ (1,0) [0|0] "" Vector__XXX
 SG_ MissCount : 4|8@1+ (1,0) [0|0] "" Vector__XXX
 SG_ ConsecMisses : 12|4@1+ (1,0) [0|0] "" Vector__XXX
 SG_ Classification : 16|2@1+ (1,0) [0|0] "" Vector__XXX
 SG_ BlockedMs : 18|13@1+ (1,0) [0|0] "" Vector__XXX
 SG_ HolderId : 31|3@1+ (1,0) [0|0] "" Vector__XXX
 SG_ TotalMissLife : 34|10@1+ (1,0) [0|0] "" Vector__XXX
 SG_ LastMissAgeMs : 44|12@1+ (1,0) [0|0] "" Vector__XXX
 SG_ PreemptCount : 56|8@1+ (1,0) [0|0] "" Vector__XXX

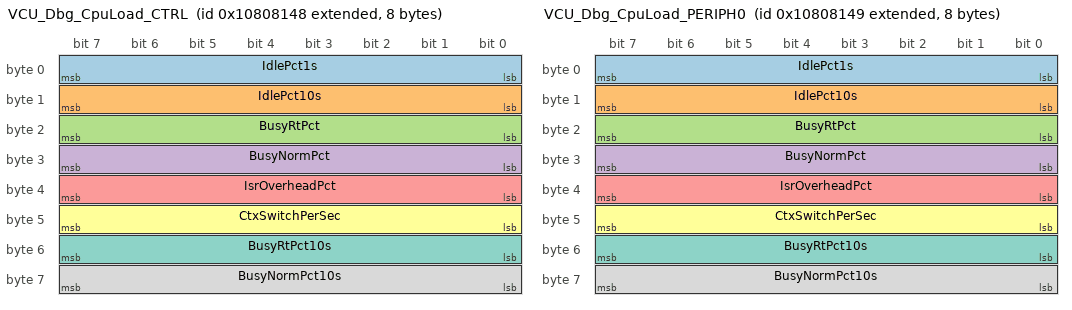
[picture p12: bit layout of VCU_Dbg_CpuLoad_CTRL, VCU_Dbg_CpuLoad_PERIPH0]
BO_ 2424340808 VCU_Dbg_CpuLoad_CTRL: 8 VCU
 SG_ IdlePct1s : 0|8@1+ (1,0) [0|0] "" Vector__XXX
 SG_ IdlePct10s : 8|8@1+ (1,0) [0|0] "" Vector__XXX
 SG_ BusyRtPct : 16|8@1+ (1,0) [0|0] "" Vector__XXX
 SG_ BusyNormPct : 24|8@1+ (1,0) [0|0] "" Vector__XXX
 SG_ IsrOverheadPct : 32|8@1+ (1,0) [0|0] "" Vector__XXX
 SG_ CtxSwitchPerSec : 40|8@1+ (1,0) [0|0] "" Vector__XXX
 SG_ BusyRtPct10s : 48|8@1+ (1,0) [0|0] "" Vector__XXX
 SG_ BusyNormPct10s : 56|8@1+ (1,0) [0|0] "" Vector__XXX

BO_ 2424340809 VCU_Dbg_CpuLoad_PERIPH0: 8 VCU
 SG_ IdlePct1s : 0|8@1+ (1,0) [0|0] "" Vector__XXX
 SG_ IdlePct10s : 8|8@1+ (1,0) [0|0] "" Vector__XXX
 SG_ BusyRtPct : 16|8@1+ (1,0) [0|0] "" Vector__XXX
 SG_ BusyNormPct : 24|8@1+ (1,0) [0|0] "" Vector__XXX
 SG_ IsrOverheadPct : 32|8@1+ (1,0) [0|0] "" Vector__XXX
 SG_ CtxSwitchPerSec : 40|8@1+ (1,0) [0|0] "" Vector__XXX
 SG_ BusyRtPct10s : 48|8@1+ (1,0) [0|0] "" Vector__XXX
 SG_ BusyNormPct10s : 56|8@1+ (1,0) [0|0] "" Vector__XXX

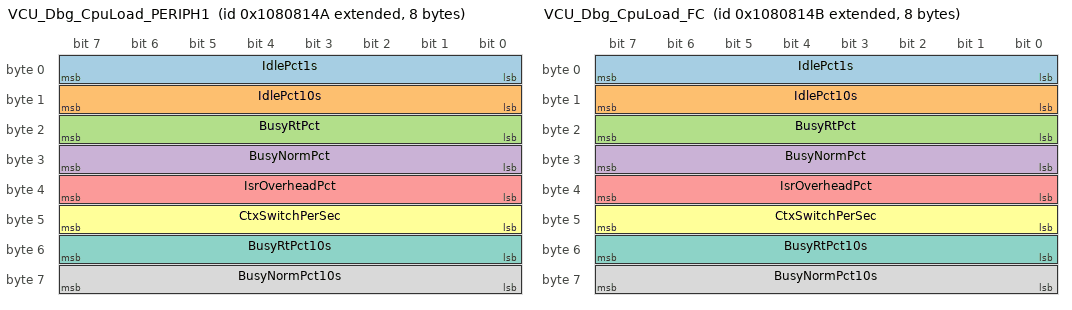
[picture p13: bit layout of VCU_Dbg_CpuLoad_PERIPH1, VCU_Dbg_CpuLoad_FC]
BO_ 2424340810 VCU_Dbg_CpuLoad_PERIPH1: 8 VCU
 SG_ IdlePct1s : 0|8@1+ (1,0) [0|0] "" Vector__XXX
 SG_ IdlePct10s : 8|8@1+ (1,0) [0|0] "" Vector__XXX
 SG_ BusyRtPct : 16|8@1+ (1,0) [0|0] "" Vector__XXX
 SG_ BusyNormPct : 24|8@1+ (1,0) [0|0] "" Vector__XXX
 SG_ IsrOverheadPct : 32|8@1+ (1,0) [0|0] "" Vector__XXX
 SG_ CtxSwitchPerSec : 40|8@1+ (1,0) [0|0] "" Vector__XXX
 SG_ BusyRtPct10s : 48|8@1+ (1,0) [0|0] "" Vector__XXX
 SG_ BusyNormPct10s : 56|8@1+ (1,0) [0|0] "" Vector__XXX

BO_ 2424340811 VCU_Dbg_CpuLoad_FC: 8 VCU
 SG_ IdlePct1s : 0|8@1+ (1,0) [0|0] "" Vector__XXX
 SG_ IdlePct10s : 8|8@1+ (1,0) [0|0] "" Vector__XXX
 SG_ BusyRtPct : 16|8@1+ (1,0) [0|0] "" Vector__XXX
 SG_ BusyNormPct : 24|8@1+ (1,0) [0|0] "" Vector__XXX
 SG_ IsrOverheadPct : 32|8@1+ (1,0) [0|0] "" Vector__XXX
 SG_ CtxSwitchPerSec : 40|8@1+ (1,0) [0|0] "" Vector__XXX
 SG_ BusyRtPct10s : 48|8@1+ (1,0) [0|0] "" Vector__XXX
 SG_ BusyNormPct10s : 56|8@1+ (1,0) [0|0] "" Vector__XXX

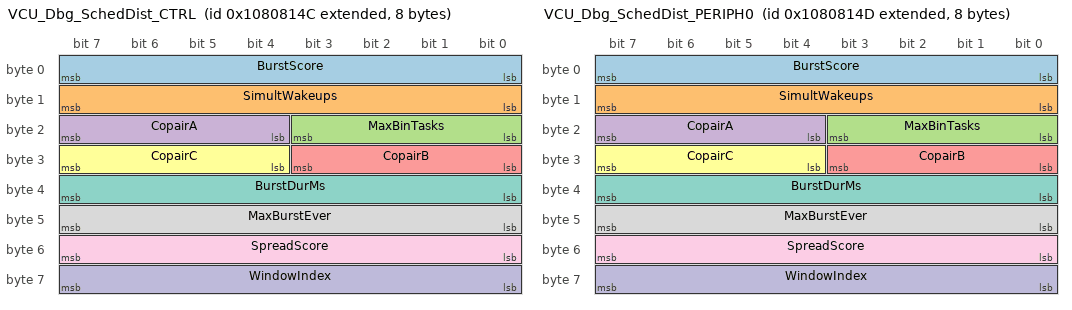
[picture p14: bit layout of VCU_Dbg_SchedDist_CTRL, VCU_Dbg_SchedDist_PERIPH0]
BO_ 2424340812 VCU_Dbg_SchedDist_CTRL: 8 VCU
 SG_ BurstScore : 0|8@1+ (1,0) [0|0] "" Vector__XXX
 SG_ SimultWakeups : 8|8@1+ (1,0) [0|0] "" Vector__XXX
 SG_ MaxBinTasks : 16|4@1+ (1,0) [0|0] "" Vector__XXX
 SG_ CopairA : 20|4@1+ (1,0) [0|0] "" Vector__XXX
 SG_ CopairB : 24|4@1+ (1,0) [0|0] "" Vector__XXX
 SG_ CopairC : 28|4@1+ (1,0) [0|0] "" Vector__XXX
 SG_ BurstDurMs : 32|8@1+ (1,0) [0|0] "" Vector__XXX
 SG_ MaxBurstEver : 40|8@1+ (1,0) [0|0] "" Vector__XXX
 SG_ SpreadScore : 48|8@1+ (1,0) [0|0] "" Vector__XXX
 SG_ WindowIndex : 56|8@1+ (1,0) [0|0] "" Vector__XXX

BO_ 2424340813 VCU_Dbg_SchedDist_PERIPH0: 8 VCU
 SG_ BurstScore : 0|8@1+ (1,0) [0|0] "" Vector__XXX
 SG_ SimultWakeups : 8|8@1+ (1,0) [0|0] "" Vector__XXX
 SG_ MaxBinTasks : 16|4@1+ (1,0) [0|0] "" Vector__XXX
 SG_ CopairA : 20|4@1+ (1,0) [0|0] "" Vector__XXX
 SG_ CopairB : 24|4@1+ (1,0) [0|0] "" Vector__XXX
 SG_ CopairC : 28|4@1+ (1,0) [0|0] "" Vector__XXX
 SG_ BurstDurMs : 32|8@1+ (1,0) [0|0] "" Vector__XXX
 SG_ MaxBurstEver : 40|8@1+ (1,0) [0|0] "" Vector__XXX
 SG_ SpreadScore : 48|8@1+ (1,0) [0|0] "" Vector__XXX
 SG_ WindowIndex : 56|8@1+ (1,0) [0|0] "" Vector__XXX

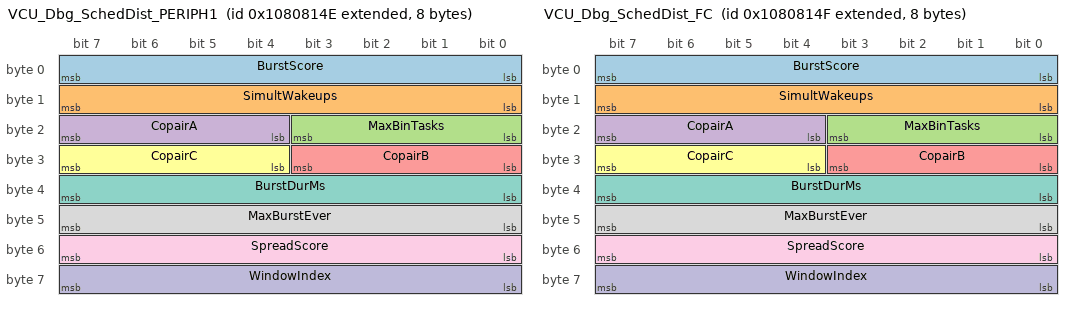
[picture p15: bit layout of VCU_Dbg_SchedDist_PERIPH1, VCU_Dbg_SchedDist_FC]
BO_ 2424340814 VCU_Dbg_SchedDist_PERIPH1: 8 VCU
 SG_ BurstScore : 0|8@1+ (1,0) [0|0] "" Vector__XXX
 SG_ SimultWakeups : 8|8@1+ (1,0) [0|0] "" Vector__XXX
 SG_ MaxBinTasks : 16|4@1+ (1,0) [0|0] "" Vector__XXX
 SG_ CopairA : 20|4@1+ (1,0) [0|0] "" Vector__XXX
 SG_ CopairB : 24|4@1+ (1,0) [0|0] "" Vector__XXX
 SG_ CopairC : 28|4@1+ (1,0) [0|0] "" Vector__XXX
 SG_ BurstDurMs : 32|8@1+ (1,0) [0|0] "" Vector__XXX
 SG_ MaxBurstEver : 40|8@1+ (1,0) [0|0] "" Vector__XXX
 SG_ SpreadScore : 48|8@1+ (1,0) [0|0] "" Vector__XXX
 SG_ WindowIndex : 56|8@1+ (1,0) [0|0] "" Vector__XXX

BO_ 2424340815 VCU_Dbg_SchedDist_FC: 8 VCU
 SG_ BurstScore : 0|8@1+ (1,0) [0|0] "" Vector__XXX
 SG_ SimultWakeups : 8|8@1+ (1,0) [0|0] "" Vector__XXX
 SG_ MaxBinTasks : 16|4@1+ (1,0) [0|0] "" Vector__XXX
 SG_ CopairA : 20|4@1+ (1,0) [0|0] "" Vector__XXX
 SG_ CopairB : 24|4@1+ (1,0) [0|0] "" Vector__XXX
 SG_ CopairC : 28|4@1+ (1,0) [0|0] "" Vector__XXX
 SG_ BurstDurMs : 32|8@1+ (1,0) [0|0] "" Vector__XXX
 SG_ MaxBurstEver : 40|8@1+ (1,0) [0|0] "" Vector__XXX
 SG_ SpreadScore : 48|8@1+ (1,0) [0|0] "" Vector__XXX
 SG_ WindowIndex : 56|8@1+ (1,0) [0|0] "" Vector__XXX

BO_ 2424340816 VCU_Dbg_HeapStatus_CTRL: 8 VCU
 SG_ HeapFreeKb : 0|8@1+ (1,0) [0|0] "" Vector__XXX
 SG_ HeapMinEverKb : 8|8@1+ (1,0) [0|0] "" Vector__XXX
 SG_ UsedPct : 16|8@1+ (1,0) [0|0] "" Vector__XXX
 SG_ StackCritMask : 24|16@1+ (1,0) [0|0] "" Vector__XXX
 SG_ AllocFailCount : 40|8@1+ (1,0) [0|0] "" Vector__XXX
 SG_ WatermarkPct : 48|8@1+ (1,0) [0|0] "" Vector__XXX
 SG_ TotalStackUsedPct : 56|8@1+ (1,0) [0|0] "" Vector__XXX

BO_ 2424340817 VCU_Dbg_HeapStatus_PERIPH0: 8 VCU
 SG_ HeapFreeKb : 0|8@1+ (1,0) [0|0] "" Vector__XXX
 SG_ HeapMinEverKb : 8|8@1+ (1,0) [0|0] "" Vector__XXX
 SG_ UsedPct : 16|8@1+ (1,0) [0|0] "" Vector__XXX
 SG_ StackCritMask : 24|16@1+ (1,0) [0|0] "" Vector__XXX
 SG_ AllocFailCount : 40|8@1+ (1,0) [0|0] "" Vector__XXX
 SG_ WatermarkPct : 48|8@1+ (1,0) [0|0] "" Vector__XXX
 SG_ TotalStackUsedPct : 56|8@1+ (1,0) [0|0] "" Vector__XXX

BO_ 2424340818 VCU_Dbg_HeapStatus_PERIPH1: 8 VCU
 SG_ HeapFreeKb : 0|8@1+ (1,0) [0|0] "" Vector__XXX
 SG_ HeapMinEverKb : 8|8@1+ (1,0) [0|0] "" Vector__XXX
 SG_ UsedPct : 16|8@1+ (1,0) [0|0] "" Vector__XXX
 SG_ StackCritMask : 24|16@1+ (1,0) [0|0] "" Vector__XXX
 SG_ AllocFailCount : 40|8@1+ (1,0) [0|0] "" Vector__XXX
 SG_ WatermarkPct : 48|8@1+ (1,0) [0|0] "" Vector__XXX
 SG_ TotalStackUsedPct : 56|8@1+ (1,0) [0|0] "" Vector__XXX

BO_ 2424340819 VCU_Dbg_HeapStatus_FC: 8 VCU
 SG_ HeapFreeKb : 0|8@1+ (1,0) [0|0] "" Vector__XXX
 SG_ HeapMinEverKb : 8|8@1+ (1,0) [0|0] "" Vector__XXX
 SG_ UsedPct : 16|8@1+ (1,0) [0|0] "" Vector__XXX
 SG_ StackCritMask : 24|16@1+ (1,0) [0|0] "" Vector__XXX
 SG_ AllocFailCount : 40|8@1+ (1,0) [0|0] "" Vector__XXX
 SG_ WatermarkPct : 48|8@1+ (1,0) [0|0] "" Vector__XXX
 SG_ TotalStackUsedPct : 56|8@1+ (1,0) [0|0] "" Vector__XXX

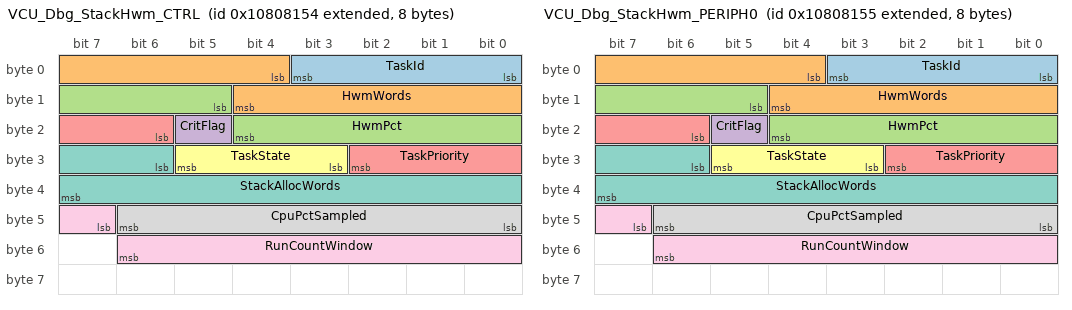
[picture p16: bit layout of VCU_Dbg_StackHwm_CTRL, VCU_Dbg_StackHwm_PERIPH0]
BO_ 2424340820 VCU_Dbg_StackHwm_CTRL: 8 VCU
 SG_ TaskId : 0|4@1+ (1,0) [0|0] "" Vector__XXX
 SG_ HwmWords : 4|9@1+ (1,0) [0|0] "" Vector__XXX
 SG_ HwmPct : 13|8@1+ (1,0) [0|0] "" Vector__XXX
 SG_ CritFlag : 21|1@1+ (1,0) [0|0] "" Vector__XXX
 SG_ TaskPriority : 22|5@1+ (1,0) [0|0] "" Vector__XXX
 SG_ TaskState : 27|3@1+ (1,0) [0|0] "" Vector__XXX
 SG_ StackAllocWords : 30|10@1+ (1,0) [0|0] "" Vector__XXX
 SG_ CpuPctSampled : 40|7@1+ (1,0) [0|0] "" Vector__XXX
 SG_ RunCountWindow : 47|8@1+ (1,0) [0|0] "" Vector__XXX

BO_ 2424340821 VCU_Dbg_StackHwm_PERIPH0: 8 VCU
 SG_ TaskId : 0|4@1+ (1,0) [0|0] "" Vector__XXX
 SG_ HwmWords : 4|9@1+ (1,0) [0|0] "" Vector__XXX
 SG_ HwmPct : 13|8@1+ (1,0) [0|0] "" Vector__XXX
 SG_ CritFlag : 21|1@1+ (1,0) [0|0] "" Vector__XXX
 SG_ TaskPriority : 22|5@1+ (1,0) [0|0] "" Vector__XXX
 SG_ TaskState : 27|3@1+ (1,0) [0|0] "" Vector__XXX
 SG_ StackAllocWords : 30|10@1+ (1,0) [0|0] "" Vector__XXX
 SG_ CpuPctSampled : 40|7@1+ (1,0) [0|0] "" Vector__XXX
 SG_ RunCountWindow : 47|8@1+ (1,0) [0|0] "" Vector__XXX

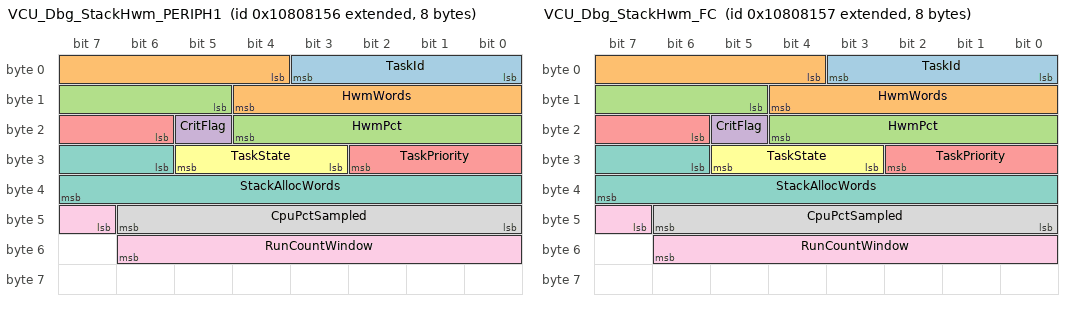
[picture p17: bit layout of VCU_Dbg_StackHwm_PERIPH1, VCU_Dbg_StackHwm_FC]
BO_ 2424340822 VCU_Dbg_StackHwm_PERIPH1: 8 VCU
 SG_ TaskId : 0|4@1+ (1,0) [0|0] "" Vector__XXX
 SG_ HwmWords : 4|9@1+ (1,0) [0|0] "" Vector__XXX
 SG_ HwmPct : 13|8@1+ (1,0) [0|0] "" Vector__XXX
 SG_ CritFlag : 21|1@1+ (1,0) [0|0] "" Vector__XXX
 SG_ TaskPriority : 22|5@1+ (1,0) [0|0] "" Vector__XXX
 SG_ TaskState : 27|3@1+ (1,0) [0|0] "" Vector__XXX
 SG_ StackAllocWords : 30|10@1+ (1,0) [0|0] "" Vector__XXX
 SG_ CpuPctSampled : 40|7@1+ (1,0) [0|0] "" Vector__XXX
 SG_ RunCountWindow : 47|8@1+ (1,0) [0|0] "" Vector__XXX

BO_ 2424340823 VCU_Dbg_StackHwm_FC: 8 VCU
 SG_ TaskId : 0|4@1+ (1,0) [0|0] "" Vector__XXX
 SG_ HwmWords : 4|9@1+ (1,0) [0|0] "" Vector__XXX
 SG_ HwmPct : 13|8@1+ (1,0) [0|0] "" Vector__XXX
 SG_ CritFlag : 21|1@1+ (1,0) [0|0] "" Vector__XXX
 SG_ TaskPriority : 22|5@1+ (1,0) [0|0] "" Vector__XXX
 SG_ TaskState : 27|3@1+ (1,0) [0|0] "" Vector__XXX
 SG_ StackAllocWords : 30|10@1+ (1,0) [0|0] "" Vector__XXX
 SG_ CpuPctSampled : 40|7@1+ (1,0) [0|0] "" Vector__XXX
 SG_ RunCountWindow : 47|8@1+ (1,0) [0|0] "" Vector__XXX

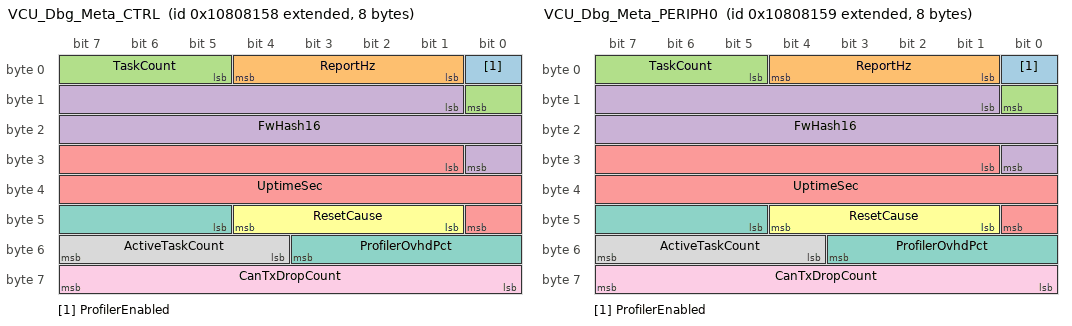
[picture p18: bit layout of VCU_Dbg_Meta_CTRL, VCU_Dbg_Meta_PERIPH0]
BO_ 2424340824 VCU_Dbg_Meta_CTRL: 8 VCU
 SG_ ProfilerEnabled : 0|1@1+ (1,0) [0|0] "" Vector__XXX
 SG_ ReportHz : 1|4@1+ (1,0) [0|0] "" Vector__XXX
 SG_ TaskCount : 5|4@1+ (1,0) [0|0] "" Vector__XXX
 SG_ FwHash16 : 9|16@1+ (1,0) [0|0] "" Vector__XXX
 SG_ UptimeSec : 25|16@1+ (1,0) [0|0] "" Vector__XXX
 SG_ ResetCause : 41|4@1+ (1,0) [0|0] "" Vector__XXX
 SG_ ProfilerOvhdPct : 45|7@1+ (1,0) [0|0] "" Vector__XXX
 SG_ ActiveTaskCount : 52|4@1+ (1,0) [0|0] "" Vector__XXX
 SG_ CanTxDropCount : 56|8@1+ (1,0) [0|0] "" Vector__XXX

BO_ 2424340825 VCU_Dbg_Meta_PERIPH0: 8 VCU
 SG_ ProfilerEnabled : 0|1@1+ (1,0) [0|0] "" Vector__XXX
 SG_ ReportHz : 1|4@1+ (1,0) [0|0] "" Vector__XXX
 SG_ TaskCount : 5|4@1+ (1,0) [0|0] "" Vector__XXX
 SG_ FwHash16 : 9|16@1+ (1,0) [0|0] "" Vector__XXX
 SG_ UptimeSec : 25|16@1+ (1,0) [0|0] "" Vector__XXX
 SG_ ResetCause : 41|4@1+ (1,0) [0|0] "" Vector__XXX
 SG_ ProfilerOvhdPct : 45|7@1+ (1,0) [0|0] "" Vector__XXX
 SG_ ActiveTaskCount : 52|4@1+ (1,0) [0|0] "" Vector__XXX
 SG_ CanTxDropCount : 56|8@1+ (1,0) [0|0] "" Vector__XXX

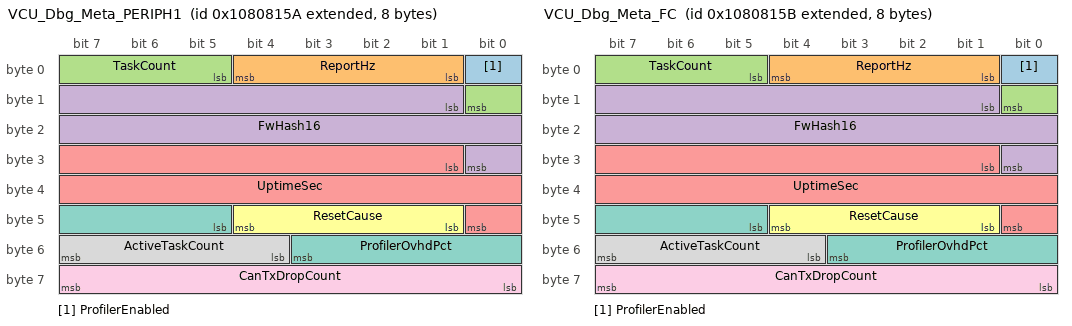
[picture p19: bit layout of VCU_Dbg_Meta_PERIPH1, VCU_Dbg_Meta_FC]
BO_ 2424340826 VCU_Dbg_Meta_PERIPH1: 8 VCU
 SG_ ProfilerEnabled : 0|1@1+ (1,0) [0|0] "" Vector__XXX
 SG_ ReportHz : 1|4@1+ (1,0) [0|0] "" Vector__XXX
 SG_ TaskCount : 5|4@1+ (1,0) [0|0] "" Vector__XXX
 SG_ FwHash16 : 9|16@1+ (1,0) [0|0] "" Vector__XXX
 SG_ UptimeSec : 25|16@1+ (1,0) [0|0] "" Vector__XXX
 SG_ ResetCause : 41|4@1+ (1,0) [0|0] "" Vector__XXX
 SG_ ProfilerOvhdPct : 45|7@1+ (1,0) [0|0] "" Vector__XXX
 SG_ ActiveTaskCount : 52|4@1+ (1,0) [0|0] "" Vector__XXX
 SG_ CanTxDropCount : 56|8@1+ (1,0) [0|0] "" Vector__XXX

BO_ 2424340827 VCU_Dbg_Meta_FC: 8 VCU
 SG_ ProfilerEnabled : 0|1@1+ (1,0) [0|0] "" Vector__XXX
 SG_ ReportHz : 1|4@1+ (1,0) [0|0] "" Vector__XXX
 SG_ TaskCount : 5|4@1+ (1,0) [0|0] "" Vector__XXX
 SG_ FwHash16 : 9|16@1+ (1,0) [0|0] "" Vector__XXX
 SG_ UptimeSec : 25|16@1+ (1,0) [0|0] "" Vector__XXX
 SG_ ResetCause : 41|4@1+ (1,0) [0|0] "" Vector__XXX
 SG_ ProfilerOvhdPct : 45|7@1+ (1,0) [0|0] "" Vector__XXX
 SG_ ActiveTaskCount : 52|4@1+ (1,0) [0|0] "" Vector__XXX
 SG_ CanTxDropCount : 56|8@1+ (1,0) [0|0] "" Vector__XXX

VAL_ 2424340800 DeadlineLoad 0 "LT25PCT" 1 "LT50PCT" 2 "LT75PCT" 3 "GT75PCT" ;
VAL_ 2424340801 DeadlineLoad 0 "LT25PCT" 1 "LT50PCT" 2 "LT75PCT" 3 "GT75PCT" ;
VAL_ 2424340802 DeadlineLoad 0 "LT25PCT" 1 "LT50PCT" 2 "LT75PCT" 3 "GT75PCT" ;
VAL_ 2424340803 DeadlineLoad 0 "LT25PCT" 1 "LT50PCT" 2 "LT75PCT" 3 "GT75PCT" ;

VAL_ 2424340804 Classification 0 "NONE" 1 "ONE_OFF" 2 "RECURRING" 3 "DEADLOCK_SUSPECTED" ;
VAL_ 2424340805 Classification 0 "NONE" 1 "ONE_OFF" 2 "RECURRING" 3 "DEADLOCK_SUSPECTED" ;
VAL_ 2424340806 Classification 0 "NONE" 1 "ONE_OFF" 2 "RECURRING" 3 "DEADLOCK_SUSPECTED" ;
VAL_ 2424340807 Classification 0 "NONE" 1 "ONE_OFF" 2 "RECURRING" 3 "DEADLOCK_SUSPECTED" ;

VAL_ 2424340820 TaskState 0 "eRunning" 1 "eReady" 2 "eBlocked" 3 "eSuspended" 4 "eDeleted" 5 "eInvalid" ;
VAL_ 2424340821 TaskState 0 "eRunning" 1 "eReady" 2 "eBlocked" 3 "eSuspended" 4 "eDeleted" 5 "eInvalid" ;
VAL_ 2424340822 TaskState 0 "eRunning" 1 "eReady" 2 "eBlocked" 3 "eSuspended" 4 "eDeleted" 5 "eInvalid" ;
VAL_ 2424340823 TaskState 0 "eRunning" 1 "eReady" 2 "eBlocked" 3 "eSuspended" 4 "eDeleted" 5 "eInvalid" ;

VAL_ 2424340824 ResetCause 0 "POR" 1 "IWDG" 2 "SW_RESET" 3 "PIN_RESET" 4 "BOR" 5 "LPWR" ;
VAL_ 2424340825 ResetCause 0 "POR" 1 "IWDG" 2 "SW_RESET" 3 "PIN_RESET" 4 "BOR" 5 "LPWR" ;
VAL_ 2424340826 ResetCause 0 "POR" 1 "IWDG" 2 "SW_RESET" 3 "PIN_RESET" 4 "BOR" 5 "LPWR" ;
VAL_ 2424340827 ResetCause 0 "POR" 1 "IWDG" 2 "SW_RESET" 3 "PIN_RESET" 4 "BOR" 5 "LPWR" ;
